VERSION "BodyCAN"

NS_ :

BS_:

BU_: CCM CEM DDM ETC ILCM PDM POT RLDM RRDM SMD SMP TRM Vector_XXX

BO_ 1 New_Message_240: 8 Vector__XXX
 SG_ New_Signal_3402 : 0|8@1+ (1,0) [0|0] "" Vector__XXX

BO_ 0 New_Message_239: 8 Vector__XXX
 SG_ New_Signal_3401 : 7|3@1- (2,3) [1|3] "ars" Vector__XXX

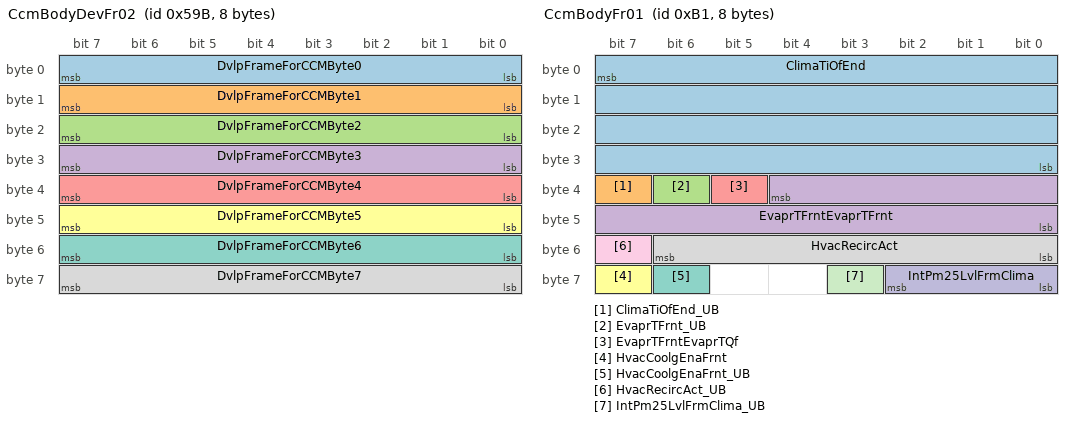
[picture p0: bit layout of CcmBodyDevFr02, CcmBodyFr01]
BO_ 1435 CcmBodyDevFr02: 8 CCM
 SG_ DvlpFrameForCCMByte0 : 7|8@0+ (1,0) [0|255] "Unitless"  CEM
 SG_ DvlpFrameForCCMByte1 : 15|8@0+ (1,0) [0|255] "Unitless"  CEM
 SG_ DvlpFrameForCCMByte2 : 23|8@0+ (1,0) [0|255] "Unitless"  CEM
 SG_ DvlpFrameForCCMByte3 : 31|8@0+ (1,0) [0|255] "Unitless"  CEM
 SG_ DvlpFrameForCCMByte4 : 39|8@0+ (1,0) [0|255] "Unitless"  CEM
 SG_ DvlpFrameForCCMByte5 : 47|8@0+ (1,0) [0|255] "Unitless"  CEM
 SG_ DvlpFrameForCCMByte6 : 55|8@0+ (1,0) [0|255] "Unitless"  CEM
 SG_ DvlpFrameForCCMByte7 : 63|8@0+ (1,0) [0|255] "Unitless"  CEM

BO_ 177 CcmBodyFr01: 8 CCM
 SG_ ClimaTiOfEnd : 7|32@0+ (0.1,0) [0|429496729.5] "s"  CEM
 SG_ ClimaTiOfEnd_UB : 39|1@0+ (1,0) [0|1] ""  CEM
 SG_ EvaprTFrnt_UB : 38|1@0+ (1,0) [0|1] ""  CEM
 SG_ EvaprTFrntEvaprTFrnt : 36|13@0- (0.1,0) [-256|255.9] "degC"  CEM
 SG_ EvaprTFrntEvaprTQf : 37|1@0+ (1,0) [0|1] ""  CEM
 SG_ HvacCoolgEnaFrnt : 63|1@0+ (1,0) [0|1] ""  CEM
 SG_ HvacCoolgEnaFrnt_UB : 62|1@0+ (1,0) [0|1] ""  CEM
 SG_ HvacRecircAct : 54|7@0+ (1,0) [0|100] "%"  CEM
 SG_ HvacRecircAct_UB : 55|1@0+ (1,0) [0|1] ""  CEM
 SG_ IntPm25LvlFrmClima : 58|3@0+ (1,0) [0|7] ""  CEM
 SG_ IntPm25LvlFrmClima_UB : 59|1@0+ (1,0) [0|1] ""  CEM

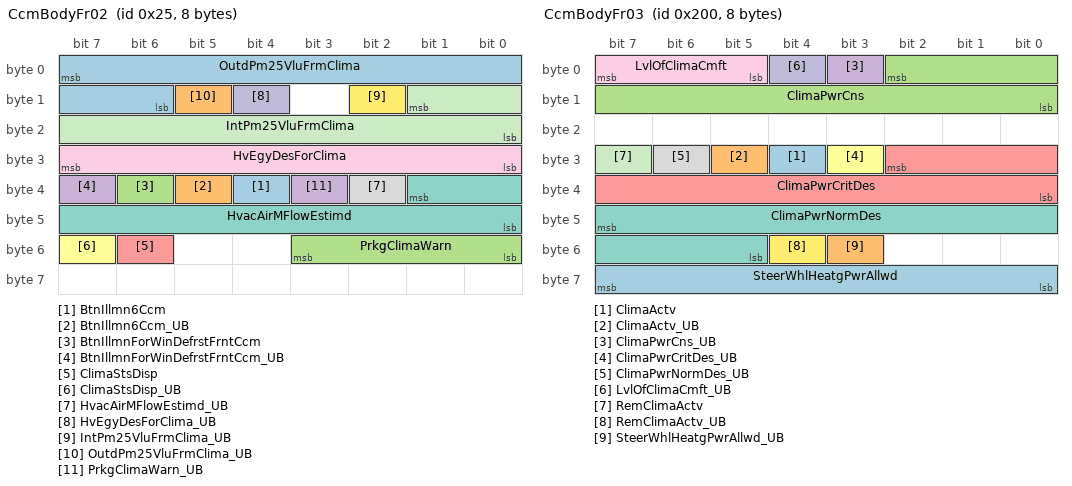
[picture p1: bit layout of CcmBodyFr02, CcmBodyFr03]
BO_ 37 CcmBodyFr02: 8 CCM
 SG_ BtnIllmn6Ccm : 36|1@0+ (1,0) [0|1] ""  CEM
 SG_ BtnIllmn6Ccm_UB : 37|1@0+ (1,0) [0|1] ""  CEM
 SG_ BtnIllmnForWinDefrstFrntCcm : 38|1@0+ (1,0) [0|1] ""  CEM
 SG_ BtnIllmnForWinDefrstFrntCcm_UB : 39|1@0+ (1,0) [0|1] ""  CEM
 SG_ ClimaStsDisp : 54|1@0+ (1,0) [0|1] ""  CEM
 SG_ ClimaStsDisp_UB : 55|1@0+ (1,0) [0|1] ""  CEM
 SG_ HvacAirMFlowEstimd : 33|10@0+ (1,0) [0|1000] "Kg / h"  CEM
 SG_ HvacAirMFlowEstimd_UB : 34|1@0+ (1,0) [0|1] ""  CEM
 SG_ HvEgyDesForClima : 31|8@0+ (50,0) [0|12750] "Wh"  CEM
 SG_ HvEgyDesForClima_UB : 12|1@0+ (1,0) [0|1] ""  CEM
 SG_ IntPm25VluFrmClima : 9|10@0+ (1,0) [0|1023] "Unitless"  CEM
 SG_ IntPm25VluFrmClima_UB : 10|1@0+ (1,0) [0|1] ""  CEM
 SG_ OutdPm25VluFrmClima : 7|10@0+ (1,0) [0|1023] "Unitless"  CEM
 SG_ OutdPm25VluFrmClima_UB : 13|1@0+ (1,0) [0|1] ""  CEM
 SG_ PrkgClimaWarn : 51|4@0+ (1,0) [0|15] ""  CEM
 SG_ PrkgClimaWarn_UB : 35|1@0+ (1,0) [0|1] ""  CEM

BO_ 512 CcmBodyFr03: 8 CCM
 SG_ ClimaActv : 28|1@0+ (1,0) [0|1] ""  CEM
 SG_ ClimaActv_UB : 29|1@0+ (1,0) [0|1] ""  CEM
 SG_ ClimaPwrCns : 2|11@0+ (1,0) [0|2047] "W"  CEM
 SG_ ClimaPwrCns_UB : 3|1@0+ (1,0) [0|1] ""  CEM
 SG_ ClimaPwrCritDes : 26|11@0+ (1,0) [0|2047] "W"  CEM
 SG_ ClimaPwrCritDes_UB : 27|1@0+ (1,0) [0|1] ""  CEM
 SG_ ClimaPwrNormDes : 47|11@0+ (1,0) [0|2047] "W"  CEM
 SG_ ClimaPwrNormDes_UB : 30|1@0+ (1,0) [0|1] ""  CEM
 SG_ LvlOfClimaCmft : 7|3@0+ (1,0) [0|7] ""  CEM
 SG_ LvlOfClimaCmft_UB : 4|1@0+ (1,0) [0|1] ""  CEM
 SG_ RemClimaActv : 31|1@0+ (1,0) [0|1] ""  CEM
 SG_ RemClimaActv_UB : 52|1@0+ (1,0) [0|1] ""  CEM
 SG_ SteerWhlHeatgPwrAllwd : 63|8@0+ (1,0) [0|255] "Unitless"  CEM
 SG_ SteerWhlHeatgPwrAllwd_UB : 51|1@0+ (1,0) [0|1] ""  CEM

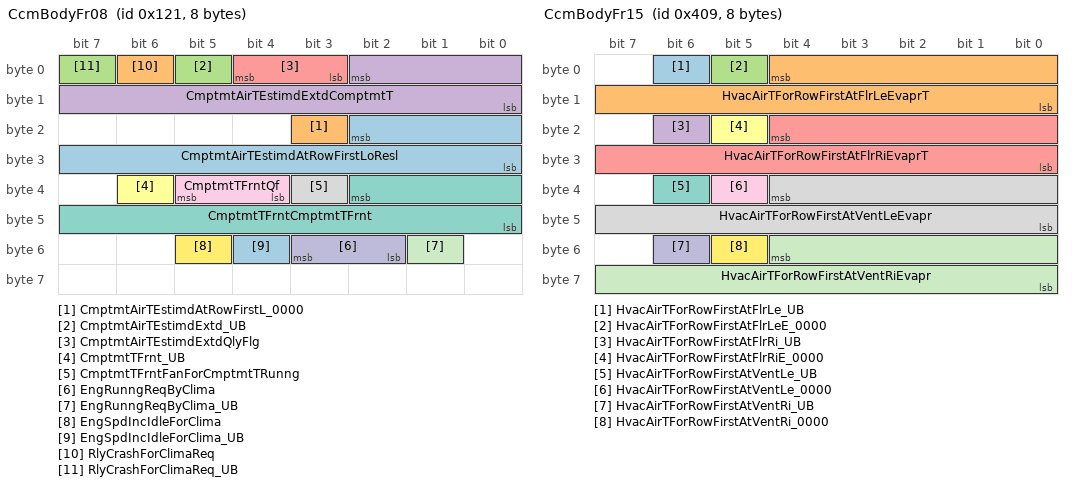
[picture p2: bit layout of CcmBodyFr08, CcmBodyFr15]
BO_ 289 CcmBodyFr08: 8 CCM
 SG_ CmptmtAirTEstimdAtRowFirstLoResl : 18|11@0+ (0.1,-60) [-60|125] "degC"  CEM
 SG_ CmptmtAirTEstimdAtRowFirstL_0000 : 19|1@0+ (1,0) [0|1] ""  CEM
 SG_ CmptmtAirTEstimdExtd_UB : 5|1@0+ (1,0) [0|1] ""  CEM
 SG_ CmptmtAirTEstimdExtdComptmtT : 2|11@0+ (0.1,-60) [-60|125] "degC"  CEM
 SG_ CmptmtAirTEstimdExtdQlyFlg : 4|2@0+ (1,0) [0|3] ""  CEM
 SG_ CmptmtTFrnt_UB : 38|1@0+ (1,0) [0|1] ""  CEM,SMD,SMP
 SG_ CmptmtTFrntCmptmtTFrnt : 34|11@0+ (0.1,-60) [-60|125] "degC"  CEM,SMD,SMP
 SG_ CmptmtTFrntFanForCmptmtTRunng : 35|1@0+ (1,0) [0|1] ""  CEM,SMD,SMP
 SG_ CmptmtTFrntQf : 37|2@0+ (1,0) [0|3] ""  CEM,SMD,SMP
 SG_ EngRunngReqByClima : 51|2@0+ (1,0) [0|3] ""  CEM
 SG_ EngRunngReqByClima_UB : 49|1@0+ (1,0) [0|1] ""  CEM
 SG_ EngSpdIncIdleForClima : 53|1@0+ (1,0) [0|1] ""  CEM
 SG_ EngSpdIncIdleForClima_UB : 52|1@0+ (1,0) [0|1] ""  CEM
 SG_ RlyCrashForClimaReq : 6|1@0+ (1,0) [0|1] ""  CEM
 SG_ RlyCrashForClimaReq_UB : 7|1@0+ (1,0) [0|1] ""  CEM

BO_ 1029 CcmBodyFr11: 8 CCM
 SG_ AirTFbFromClima_UB : 1|1@0+ (1,0) [0|1] ""  CEM
 SG_ AirTFbFromClimaAirTFbFromClima : 15|8@0- (1,0) [-128|127] "Unitless"  CEM
 SG_ AirTFbFromClimaDataQf : 0|1@0+ (1,0) [0|1] ""  CEM
 SG_ ClimaCmptSts : 5|3@0+ (1,0) [0|7] ""  CEM
 SG_ ClimaCmptSts_UB : 6|1@0+ (1,0) [0|1] ""  CEM
 SG_ ClimaDefrstSts : 28|1@0+ (1,0) [0|1] ""  CEM
 SG_ ClimaDefrstSts_UB : 27|1@0+ (1,0) [0|1] ""  CEM
 SG_ ClimaOvrHeatProActv : 54|1@0+ (1,0) [0|1] ""  CEM
 SG_ ClimaOvrHeatProActv_UB : 53|1@0+ (1,0) [0|1] ""  CEM
 SG_ CupHoldrActvAllwd : 25|10@0+ (0.1,0) [0|102.3] "W"  CEM
 SG_ CupHoldrActvAllwd_UB : 26|1@0+ (1,0) [0|1] ""  CEM
 SG_ HvacEvaprTSpFrnt : 47|8@0+ (0.1,-5) [-5|20] "Unitless"  CEM
 SG_ HvacEvaprTSpFrnt_UB : 55|1@0+ (1,0) [0|1] ""  CEM
 SG_ HvacEvaprTSpRe : 63|8@0+ (0.1,-5) [-5|20] "Unitless"  CEM
 SG_ HvacEvaprTSpRe_UB : 7|1@0+ (1,0) [0|1] ""  CEM
 SG_ PwrEstimdAtStbForClima : 23|11@0+ (1,0) [0|2047] "W"  CEM
 SG_ PwrEstimdAtStbForClima_UB : 2|1@0+ (1,0) [0|1] ""  CEM

BO_ 1033 CcmBodyFr15: 8 CCM
 SG_ HvacAirTForRowFirstAtFlrLe_UB : 6|1@0+ (1,0) [0|1] ""  CEM
 SG_ HvacAirTForRowFirstAtFlrLeEvaprT : 4|13@0- (0.1,0) [-256|255.9] "degC"  CEM
 SG_ HvacAirTForRowFirstAtFlrLeE_0000 : 5|1@0+ (1,0) [0|1] ""  CEM
 SG_ HvacAirTForRowFirstAtFlrRi_UB : 22|1@0+ (1,0) [0|1] ""  CEM
 SG_ HvacAirTForRowFirstAtFlrRiEvaprT : 20|13@0- (0.1,0) [-256|255.9] "degC"  CEM
 SG_ HvacAirTForRowFirstAtFlrRiE_0000 : 21|1@0+ (1,0) [0|1] ""  CEM
 SG_ HvacAirTForRowFirstAtVentLe_UB : 38|1@0+ (1,0) [0|1] ""  CEM
 SG_ HvacAirTForRowFirstAtVentLeEvapr : 36|13@0- (0.1,0) [-256|255.9] "degC"  CEM
 SG_ HvacAirTForRowFirstAtVentLe_0000 : 37|1@0+ (1,0) [0|1] ""  CEM
 SG_ HvacAirTForRowFirstAtVentRi_UB : 54|1@0+ (1,0) [0|1] ""  CEM
 SG_ HvacAirTForRowFirstAtVentRiEvapr : 52|13@0- (0.1,0) [-256|255.9] "degC"  CEM
 SG_ HvacAirTForRowFirstAtVentRi_0000 : 53|1@0+ (1,0) [0|1] ""  CEM

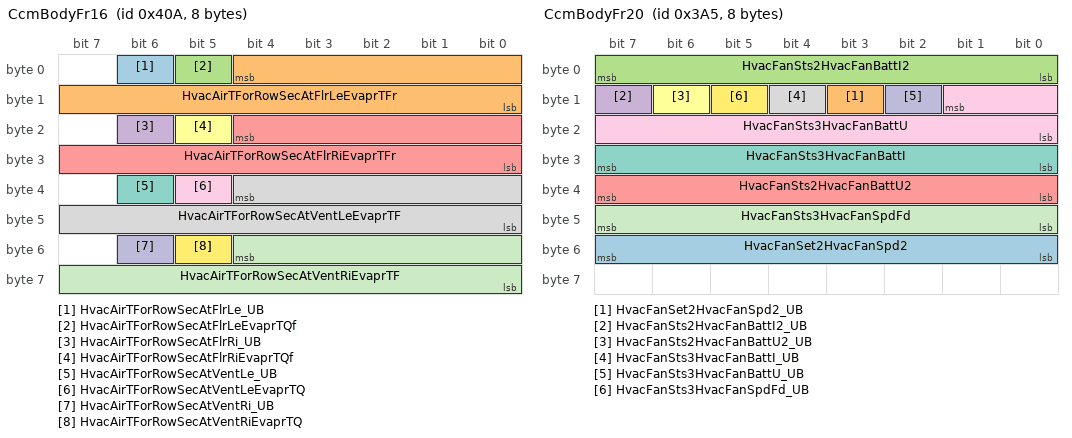
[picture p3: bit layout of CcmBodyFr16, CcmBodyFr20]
BO_ 1034 CcmBodyFr16: 8 CCM
 SG_ HvacAirTForRowSecAtFlrLe_UB : 6|1@0+ (1,0) [0|1] ""  CEM
 SG_ HvacAirTForRowSecAtFlrLeEvaprTFr : 4|13@0- (0.1,0) [-256|255.9] "degC"  CEM
 SG_ HvacAirTForRowSecAtFlrLeEvaprTQf : 5|1@0+ (1,0) [0|1] ""  CEM
 SG_ HvacAirTForRowSecAtFlrRi_UB : 22|1@0+ (1,0) [0|1] ""  CEM
 SG_ HvacAirTForRowSecAtFlrRiEvaprTFr : 20|13@0- (0.1,0) [-256|255.9] "degC"  CEM
 SG_ HvacAirTForRowSecAtFlrRiEvaprTQf : 21|1@0+ (1,0) [0|1] ""  CEM
 SG_ HvacAirTForRowSecAtVentLe_UB : 38|1@0+ (1,0) [0|1] ""  CEM
 SG_ HvacAirTForRowSecAtVentLeEvaprTF : 36|13@0- (0.1,0) [-256|255.9] "degC"  CEM
 SG_ HvacAirTForRowSecAtVentLeEvaprTQ : 37|1@0+ (1,0) [0|1] ""  CEM
 SG_ HvacAirTForRowSecAtVentRi_UB : 54|1@0+ (1,0) [0|1] ""  CEM
 SG_ HvacAirTForRowSecAtVentRiEvaprTF : 52|13@0- (0.1,0) [-256|255.9] "degC"  CEM
 SG_ HvacAirTForRowSecAtVentRiEvaprTQ : 53|1@0+ (1,0) [0|1] ""  CEM

BO_ 933 CcmBodyFr20: 8 CCM
 SG_ HvacFanSet2HvacFanSpd2 : 55|8@0+ (1,0) [0|255] "Unitless"  CEM
 SG_ HvacFanSet2HvacFanSpd2_UB : 11|1@0+ (1,0) [0|1] ""  CEM
 SG_ HvacFanSts2HvacFanBattI2 : 7|8@0+ (0.25,0) [0|63.25] "A"  CEM
 SG_ HvacFanSts2HvacFanBattI2_UB : 15|1@0+ (1,0) [0|1] ""  CEM
 SG_ HvacFanSts2HvacFanBattU2 : 39|8@0+ (0.1,0) [0|25.4] "Volt"  CEM
 SG_ HvacFanSts2HvacFanBattU2_UB : 14|1@0+ (1,0) [0|1] ""  CEM
 SG_ HvacFanSts3HvacFanBattI : 31|8@0+ (0.15,0) [0|38.25] "A"  CEM
 SG_ HvacFanSts3HvacFanBattI_UB : 12|1@0+ (1,0) [0|1] ""  CEM
 SG_ HvacFanSts3HvacFanBattU : 9|10@0+ (0.1,0) [0|102.3] "Volt"  CEM
 SG_ HvacFanSts3HvacFanBattU_UB : 10|1@0+ (1,0) [0|1] ""  CEM
 SG_ HvacFanSts3HvacFanSpdFd : 47|8@0+ (20,300) [300|5400] "rpm"  CEM
 SG_ HvacFanSts3HvacFanSpdFd_UB : 13|1@0+ (1,0) [0|1] ""  CEM

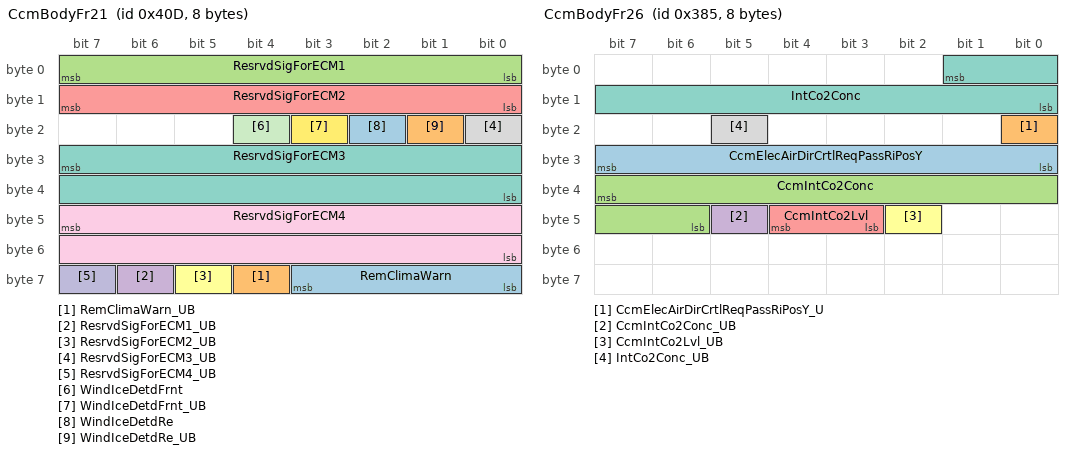
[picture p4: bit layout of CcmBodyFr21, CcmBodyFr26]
BO_ 1037 CcmBodyFr21: 8 CCM
 SG_ RemClimaWarn : 59|4@0+ (1,0) [0|15] ""  CEM
 SG_ RemClimaWarn_UB : 60|1@0+ (1,0) [0|1] ""  CEM
 SG_ ResrvdSigForECM1 : 7|8@0+ (1,0) [0|255] "Unitless"  CEM
 SG_ ResrvdSigForECM1_UB : 62|1@0+ (1,0) [0|1] ""  CEM
 SG_ ResrvdSigForECM2 : 15|8@0+ (1,0) [0|255] "Unitless"  CEM
 SG_ ResrvdSigForECM2_UB : 61|1@0+ (1,0) [0|1] ""  CEM
 SG_ ResrvdSigForECM3 : 31|16@0+ (1,0) [0|65535] "Unitless"  CEM
 SG_ ResrvdSigForECM3_UB : 16|1@0+ (1,0) [0|1] ""  CEM
 SG_ ResrvdSigForECM4 : 47|16@0+ (1,0) [0|65535] "Unitless"  CEM
 SG_ ResrvdSigForECM4_UB : 63|1@0+ (1,0) [0|1] ""  CEM
 SG_ WindIceDetdFrnt : 20|1@0+ (1,0) [0|1] ""  CEM
 SG_ WindIceDetdFrnt_UB : 19|1@0+ (1,0) [0|1] ""  CEM
 SG_ WindIceDetdRe : 18|1@0+ (1,0) [0|1] ""  CEM
 SG_ WindIceDetdRe_UB : 17|1@0+ (1,0) [0|1] ""  CEM

BO_ 1040 CcmBodyFr22: 8 CCM
 SG_ CmptModForHp : 23|3@0+ (1,0) [0|7] ""  CEM
 SG_ CmptModForHp_UB : 31|1@0+ (1,0) [0|1] ""  CEM
 SG_ HpReqCritSts : 4|1@0+ (1,0) [0|1] ""  CEM
 SG_ HpReqCritSts_UB : 47|1@0+ (1,0) [0|1] ""  CEM
 SG_ HvacCondsorT_UB : 30|1@0+ (1,0) [0|1] ""  CEM
 SG_ HvacCondsorTEvaprTFrnt : 28|13@0- (0.1,0) [-256|255.9] "degC"  CEM
 SG_ HvacCondsorTEvaprTQf : 29|1@0+ (1,0) [0|1] ""  CEM
 SG_ HvacCondsorTsp_UB : 46|1@0+ (1,0) [0|1] ""  CEM
 SG_ HvacCondsorTspEvaprTFrnt : 44|13@0- (0.1,0) [-256|255.9] "degC"  CEM
 SG_ HvacCondsorTspEvaprTQf : 45|1@0+ (1,0) [0|1] ""  CEM
 SG_ HvahBlwReq : 19|2@0+ (1,0) [0|3] ""  CEM
 SG_ HvahBlwReq_UB : 20|1@0+ (1,0) [0|1] ""  CEM
 SG_ HvahPwrReq : 15|8@0+ (20,0) [0|5100] "W"  CEM
 SG_ HvahPwrReq_UB : 16|1@0+ (1,0) [0|1] ""  CEM
 SG_ ReEvapVlvSts : 7|3@0+ (1,0) [0|7] ""  CEM
 SG_ ReEvapVlvSts_UB : 56|1@0+ (1,0) [0|1] ""  CEM
 SG_ RemClimaDelaySts : 57|1@0+ (1,0) [0|1] ""  CEM
 SG_ RemClimaDelaySts_UB : 58|1@0+ (1,0) [0|1] ""  CEM
 SG_ RemClimaExtnTiRspn : 59|1@0+ (1,0) [0|1] ""  CEM
 SG_ RemClimaExtnTiRspn_UB : 60|1@0+ (1,0) [0|1] ""  CEM
 SG_ RemClimaHvRspn : 61|1@0+ (1,0) [0|1] ""  CEM
 SG_ RemClimaHvRspn_UB : 62|1@0+ (1,0) [0|1] ""  CEM
 SG_ RemClimaHvSts : 63|1@0+ (1,0) [0|1] ""  CEM
 SG_ RemClimaHvSts_UB : 17|1@0+ (1,0) [0|1] ""  CEM

BO_ 1049 CcmBodyFr25: 8 CCM
 SG_ ClimaSts : 20|1@0+ (1,0) [0|1] ""  CEM
 SG_ ClimaSts_UB : 12|1@0+ (1,0) [0|1] ""  CEM
 SG_ ElecDefrstReq_UB : 56|1@0+ (1,0) [0|1] ""  CEM
 SG_ ElecDefrstReqMirrDefrstReq : 50|1@0+ (1,0) [0|1] ""  CEM
 SG_ ElecDefrstReqWinDefrstFrntReq : 49|1@0+ (1,0) [0|1] ""  CEM
 SG_ ElecDefrstReqWinDefrstReReq : 48|1@0+ (1,0) [0|1] ""  CEM
 SG_ FragCh1UseUpWrn : 60|1@0+ (1,0) [0|1] ""  CEM
 SG_ FragCh1UseUpWrn_UB : 59|1@0+ (1,0) [0|1] ""  CEM
 SG_ FragCh2UseUpWrn : 58|1@0+ (1,0) [0|1] ""  CEM
 SG_ FragCh2UseUpWrn_UB : 57|1@0+ (1,0) [0|1] ""  CEM
 SG_ FragCh3UseUpWrn : 42|1@0+ (1,0) [0|1] ""  CEM
 SG_ FragCh3UseUpWrn_UB : 41|1@0+ (1,0) [0|1] ""  CEM
 SG_ FragCh4UseUpWrn : 44|1@0+ (1,0) [0|1] ""  CEM
 SG_ FragCh4UseUpWrn_UB : 43|1@0+ (1,0) [0|1] ""  CEM
 SG_ FragCh5UseUpWrn : 46|1@0+ (1,0) [0|1] ""  CEM
 SG_ FragCh5UseUpWrn_UB : 45|1@0+ (1,0) [0|1] ""  CEM
 SG_ FragLvlFrmClima : 55|2@0+ (1,0) [0|3] ""  CEM
 SG_ FragLvlFrmClima_UB : 40|1@0+ (1,0) [0|1] ""  CEM
 SG_ FragStsFrmClima : 23|2@0+ (1,0) [0|3] ""  CEM
 SG_ FragStsFrmClima_UB : 61|1@0+ (1,0) [0|1] ""  CEM
 SG_ FrntHvacBlowerSts : 9|2@0+ (1,0) [0|3] ""  CEM
 SG_ FrntHvacBlowerSts_UB : 13|1@0+ (1,0) [0|1] ""  CEM
 SG_ HeatrAirTReq : 7|9@0+ (0.5,-60) [-60|195.5] "Unitless"  CEM
 SG_ HeatrAirTReq_UB : 14|1@0+ (1,0) [0|1] ""  CEM
 SG_ HvacCoolgEnaRe : 39|1@0+ (1,0) [0|1] ""  CEM
 SG_ HvacCoolgEnaRe_UB : 47|1@0+ (1,0) [0|1] ""  CEM
 SG_ HvacOsaAndRecActrQfForHp : 10|1@0+ (1,0) [0|1] ""  CEM
 SG_ HvacOsaAndRecActrQfForHp_UB : 34|1@0+ (1,0) [0|1] ""  CEM
 SG_ HvahAirTsp : 18|11@0+ (0.1,-40) [-40|164.7] "degC"  CEM
 SG_ HvahAirTsp_UB : 11|1@0+ (1,0) [0|1] ""  CEM
 SG_ HvahHeatgReq : 19|1@0+ (1,0) [0|1] ""  CEM
 SG_ HvahHeatgReq_UB : 21|1@0+ (1,0) [0|1] ""  CEM
 SG_ IntPm25StsFrmClima : 52|2@0+ (1,0) [0|3] ""  CEM
 SG_ IntPm25StsFrmClima_UB : 53|1@0+ (1,0) [0|1] ""  CEM
 SG_ OutdPm25LvlFrmClima : 37|3@0+ (1,0) [0|7] ""  CEM
 SG_ OutdPm25LvlFrmClima_UB : 38|1@0+ (1,0) [0|1] ""  CEM
 SG_ PostDrvgClimaAvl : 32|1@0+ (1,0) [0|1] ""  CEM
 SG_ PostDrvgClimaAvl_UB : 33|1@0+ (1,0) [0|1] ""  CEM

BO_ 901 CcmBodyFr26: 8 CCM
 SG_ CcmElecAirDirCrtlReqPassRiPosY : 31|8@0+ (1,0) [0|255] "Unitless"  CEM
 SG_ CcmElecAirDirCrtlReqPassRiPosY_U : 16|1@0+ (1,0) [0|1] ""  CEM
 SG_ CcmIntCo2Conc : 39|10@0+ (10,0) [0|10230] "Unitless"  CEM
 SG_ CcmIntCo2Conc_UB : 45|1@0+ (1,0) [0|1] ""  CEM
 SG_ CcmIntCo2Lvl : 44|2@0+ (1,0) [0|3] ""  CEM
 SG_ CcmIntCo2Lvl_UB : 42|1@0+ (1,0) [0|1] ""  CEM
 SG_ IntCo2Conc : 1|10@0+ (10,0) [0|10230] "Unitless"  CEM
 SG_ IntCo2Conc_UB : 21|1@0+ (1,0) [0|1] ""  CEM

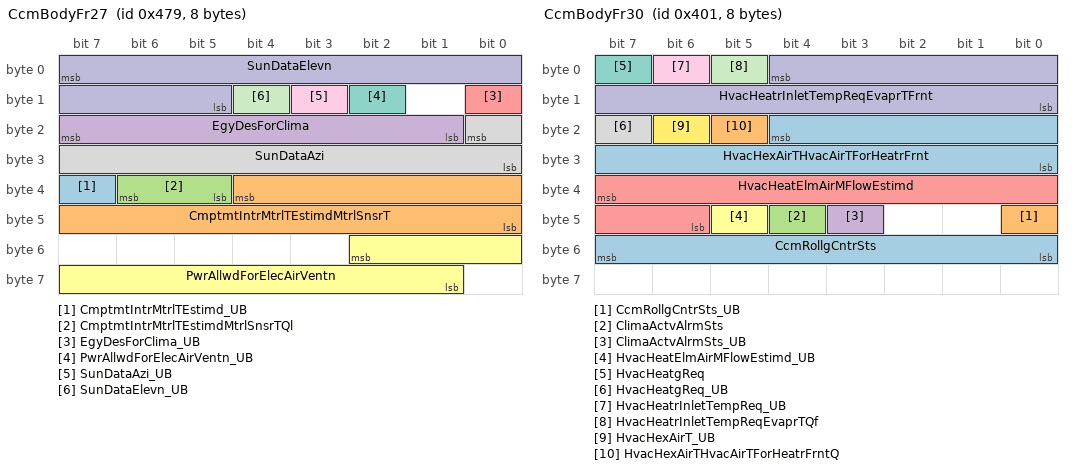
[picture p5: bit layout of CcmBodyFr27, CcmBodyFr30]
BO_ 1145 CcmBodyFr27: 8 CCM
 SG_ CmptmtIntrMtrlTEstimd_UB : 39|1@0+ (1,0) [0|1] ""  CEM
 SG_ CmptmtIntrMtrlTEstimdMtrlSnsrT : 36|13@0- (0.1,0) [-256|255.9] "degC"  CEM
 SG_ CmptmtIntrMtrlTEstimdMtrlSnsrTQl : 38|2@0+ (1,0) [0|3] ""  CEM
 SG_ EgyDesForClima : 23|7@0+ (1,0) [0|127] "Wh"  CEM
 SG_ EgyDesForClima_UB : 8|1@0+ (1,0) [0|1] ""  CEM
 SG_ PwrAllwdForElecAirVentn : 50|10@0+ (0.1,0) [0|102.3] "W"  CEM
 SG_ PwrAllwdForElecAirVentn_UB : 10|1@0+ (1,0) [0|1] ""  CEM
 SG_ SunDataAzi : 16|9@0+ (1,0) [0|511] "Unitless"  CEM
 SG_ SunDataAzi_UB : 11|1@0+ (1,0) [0|1] ""  CEM
 SG_ SunDataElevn : 7|11@0+ (0.1,-90) [-90|90] "Deg"  CEM
 SG_ SunDataElevn_UB : 12|1@0+ (1,0) [0|1] ""  CEM

BO_ 1168 CcmBodyFr28: 8 CCM
 SG_ AmbTEstimd_UB : 5|1@0+ (1,0) [0|1] ""  CEM
 SG_ AmbTEstimdAmbTEstimd : 2|11@0+ (0.1,-70) [-70|134.7] "degC"  CEM
 SG_ AmbTEstimdQf : 3|1@0+ (1,0) [0|1] ""  CEM
 SG_ CcmAirClngSts : 61|2@0+ (1,0) [0|3] ""  CEM
 SG_ CcmAirClngSts_UB : 59|1@0+ (1,0) [0|1] ""  CEM
 SG_ DrvrSeatHeatgPwrAllwd : 23|8@0+ (1,0) [0|255] "Unitless"  CEM,SMD
 SG_ DrvrSeatHeatgPwrAllwd_UB : 6|1@0+ (1,0) [0|1] ""  CEM,SMD
 SG_ PassSeatHeatgPwrAllwd : 31|8@0+ (1,0) [0|255] "Unitless"  CEM,SMP
 SG_ PassSeatHeatgPwrAllwd_UB : 7|1@0+ (1,0) [0|1] ""  CEM,SMP
 SG_ SeatClimaDurgClima_UB : 63|1@0+ (1,0) [0|1] ""  SMD,SMP
 SG_ SeatClimaDurgClimaHmiSeatHeatgFo : 41|2@0+ (1,0) [0|3] ""  SMD,SMP
 SG_ SeatClimaDurgClimaHmiSeatHe_0000 : 43|2@0+ (1,0) [0|3] ""  SMD,SMP
 SG_ SeatClimaDurgClimaHmiSeatHe_0001 : 45|2@0+ (1,0) [0|3] ""  SMD,SMP
 SG_ SeatClimaDurgClimaHmiSeatHe_0002 : 47|2@0+ (1,0) [0|3] ""  SMD,SMP
 SG_ SeatClimaDurgClimaHmiSeatVentnFo : 49|2@0+ (1,0) [0|3] ""  SMD,SMP
 SG_ SeatClimaDurgClimaHmiSeatVe_0000 : 51|2@0+ (1,0) [0|3] ""  SMD,SMP
 SG_ SeatClimaDurgClimaHmiSeatVe_0001 : 53|2@0+ (1,0) [0|3] ""  SMD,SMP
 SG_ SeatClimaDurgClimaHmiSeatVe_0002 : 55|2@0+ (1,0) [0|3] ""  SMD,SMP
 SG_ SecRowLeSeatHeatgPwrAllwd : 39|8@0+ (1,0) [0|255] "Unitless"  CEM
 SG_ SecRowLeSeatHeatgPwrAllwd_UB : 62|1@0+ (1,0) [0|1] ""  CEM

BO_ 1184 CcmBodyFr29: 8 CCM
 SG_ DefrstMaxSts : 63|1@0+ (1,0) [0|1] ""  CEM
 SG_ DefrstMaxSts_UB : 62|1@0+ (1,0) [0|1] ""  CEM
 SG_ ElecAirVentnAvlSts : 45|3@0+ (1,0) [0|7] ""  CEM
 SG_ ElecAirVentnAvlSts_UB : 42|1@0+ (1,0) [0|1] ""  CEM
 SG_ FragCh1Id : 7|8@0+ (1,0) [0|255] "Unitless"  CEM
 SG_ FragCh1Id_UB : 55|1@0+ (1,0) [0|1] ""  CEM
 SG_ FragCh2Id : 15|8@0+ (1,0) [0|255] "Unitless"  CEM
 SG_ FragCh2Id_UB : 54|1@0+ (1,0) [0|1] ""  CEM
 SG_ FragCh3Id : 23|8@0+ (1,0) [0|255] "Unitless"  CEM
 SG_ FragCh3Id_UB : 53|1@0+ (1,0) [0|1] ""  CEM
 SG_ FragCh4Id : 31|8@0+ (1,0) [0|255] "Unitless"  CEM
 SG_ FragCh4Id_UB : 52|1@0+ (1,0) [0|1] ""  CEM
 SG_ FragCh5Id : 39|8@0+ (1,0) [0|255] "Unitless"  CEM
 SG_ FragCh5Id_UB : 51|1@0+ (1,0) [0|1] ""  CEM
 SG_ FragRefreshPopUp : 41|1@0+ (1,0) [0|1] ""  CEM
 SG_ FragRefreshPopUp_UB : 50|1@0+ (1,0) [0|1] ""  CEM
 SG_ IntPm25HiPopUp : 49|2@0+ (1,0) [0|3] ""  CEM
 SG_ IntPm25HiPopUp_UB : 61|1@0+ (1,0) [0|1] ""  CEM
 SG_ OutdAirQly_UB : 59|1@0+ (1,0) [0|1] ""  CEM
 SG_ OutdAirQlyOutdAirQly : 57|2@0+ (1,0) [0|3] ""  CEM
 SG_ OutdAirQlyQf : 58|1@0+ (1,0) [0|1] ""  CEM
 SG_ OutdPm25StsFrmClima : 47|2@0+ (1,0) [0|3] ""  CEM
 SG_ OutdPm25StsFrmClima_UB : 60|1@0+ (1,0) [0|1] ""  CEM

BO_ 1025 CcmBodyFr30: 8 CCM
 SG_ CcmRollgCntrSts : 55|8@0+ (1,0) [0|255] "Unitless"  CEM
 SG_ CcmRollgCntrSts_UB : 40|1@0+ (1,0) [0|1] ""  CEM
 SG_ ClimaActvAlrmSts : 44|1@0+ (1,0) [0|1] ""  CEM
 SG_ ClimaActvAlrmSts_UB : 43|1@0+ (1,0) [0|1] ""  CEM
 SG_ HvacHeatElmAirMFlowEstimd : 39|10@0+ (1,0) [0|1000] "Kg / h"  CEM
 SG_ HvacHeatElmAirMFlowEstimd_UB : 45|1@0+ (1,0) [0|1] ""  CEM
 SG_ HvacHeatgReq : 7|1@0+ (1,0) [0|1] ""  CEM
 SG_ HvacHeatgReq_UB : 23|1@0+ (1,0) [0|1] ""  CEM
 SG_ HvacHeatrInletTempReq_UB : 6|1@0+ (1,0) [0|1] ""  CEM
 SG_ HvacHeatrInletTempReqEvaprTFrnt : 4|13@0- (0.1,0) [-256|255.9] "degC"  CEM
 SG_ HvacHeatrInletTempReqEvaprTQf : 5|1@0+ (1,0) [0|1] ""  CEM
 SG_ HvacHexAirT_UB : 22|1@0+ (1,0) [0|1] ""  CEM
 SG_ HvacHexAirTHvacAirTForHeatrFrnt : 20|13@0- (0.1,0) [-256|255.9] "degC"  CEM
 SG_ HvacHexAirTHvacAirTForHeatrFrntQ : 21|1@0+ (1,0) [0|1] ""  CEM

BO_ 295 CcmBodyFr31: 8 CCM
 SG_ AirFragCh1RunngSts : 55|1@0+ (1,0) [0|1] ""  CEM
 SG_ AirFragCh1RunngSts_UB : 58|1@0+ (1,0) [0|1] ""  CEM
 SG_ AirFragCh2RunngSts : 54|1@0+ (1,0) [0|1] ""  CEM
 SG_ AirFragCh2RunngSts_UB : 57|1@0+ (1,0) [0|1] ""  CEM
 SG_ AirFragCh3RunngSts : 53|1@0+ (1,0) [0|1] ""  CEM
 SG_ AirFragCh3RunngSts_UB : 56|1@0+ (1,0) [0|1] ""  CEM
 SG_ AirFragCh4RunngSts : 52|1@0+ (1,0) [0|1] ""  CEM
 SG_ AirFragCh4RunngSts_UB : 50|1@0+ (1,0) [0|1] ""  CEM
 SG_ AirFragCh5RunngSts : 51|1@0+ (1,0) [0|1] ""  CEM
 SG_ AirFragCh5RunngSts_UB : 49|1@0+ (1,0) [0|1] ""  CEM
 SG_ DrvrSeatVentnPwrAllwd : 7|8@0+ (1,0) [0|255] "Unitless"  CEM,SMD
 SG_ DrvrSeatVentnPwrAllwd_UB : 59|1@0+ (1,0) [0|1] ""  CEM,SMD
 SG_ EcoClimaSts : 47|1@0+ (1,0) [0|1] ""  CEM
 SG_ EcoClimaSts_UB : 46|1@0+ (1,0) [0|1] ""  CEM
 SG_ PassSeatVentnPwrAllwd : 15|8@0+ (1,0) [0|255] "Unitless"  CEM,SMP
 SG_ PassSeatVentnPwrAllwd_UB : 60|1@0+ (1,0) [0|1] ""  CEM,SMP
 SG_ SecRowLeSeatVentnPwrAllwd : 23|8@0+ (1,0) [0|255] "Unitless"  CEM
 SG_ SecRowLeSeatVentnPwrAllwd_UB : 61|1@0+ (1,0) [0|1] ""  CEM
 SG_ SecRowRiSeatHeatgPwrAllwd : 31|8@0+ (1,0) [0|255] "Unitless"  CEM
 SG_ SecRowRiSeatHeatgPwrAllwd_UB : 62|1@0+ (1,0) [0|1] ""  CEM
 SG_ SecRowRiSeatVentnPwrAllwd : 39|8@0+ (1,0) [0|255] "Unitless"  CEM
 SG_ SecRowRiSeatVentnPwrAllwd_UB : 63|1@0+ (1,0) [0|1] ""  CEM
 SG_ SteerWhlHeatgDurgClima : 45|1@0+ (1,0) [0|1] ""  CEM
 SG_ SteerWhlHeatgDurgClima_UB : 44|1@0+ (1,0) [0|1] ""  CEM

BO_ 831 CcmBodyFr34: 8 CCM
 SG_ CarTiIntForClima : 39|32@0+ (0.1,0) [0|429496729.5] "s"  CEM
 SG_ CarTiIntForClima_UB : 31|1@0+ (1,0) [0|1] ""  CEM
 SG_ ClimaCoolgReqLvl : 27|2@0+ (1,0) [0|3] ""  CEM
 SG_ ClimaCoolgReqLvl_UB : 29|1@0+ (1,0) [0|1] ""  CEM
 SG_ ClimaHeatgReqLvl : 25|2@0+ (1,0) [0|3] ""  CEM
 SG_ ClimaHeatgReqLvl_UB : 28|1@0+ (1,0) [0|1] ""  CEM
 SG_ ClimaOvrHeatPrtSts : 23|1@0+ (1,0) [0|1] ""  CEM
 SG_ ClimaOvrHeatPrtSts_UB : 30|1@0+ (1,0) [0|1] ""  CEM
 SG_ EvaprVlvReStsExtd_UB : 14|1@0+ (1,0) [0|1] ""  CEM
 SG_ EvaprVlvReStsExtdDiagcStsForCirc : 13|2@0+ (1,0) [0|3] ""  CEM
 SG_ EvaprVlvReStsExtdDiagcStsForShoT : 11|2@0+ (1,0) [0|3] ""  CEM
 SG_ EvaprVlvReStsExtdDiagcStsFo_0000 : 9|2@0+ (1,0) [0|3] ""  CEM
 SG_ ReHvacBlowerSts : 17|2@0+ (1,0) [0|3] ""  CEM
 SG_ ReHvacBlowerSts_UB : 18|1@0+ (1,0) [0|1] ""  CEM
 SG_ RlyCmftForClimaReq : 22|1@0+ (1,0) [0|1] ""  CEM
 SG_ RlyCmftForClimaReq_UB : 21|1@0+ (1,0) [0|1] ""  CEM
 SG_ UBoostReqByClima : 20|1@0+ (1,0) [0|1] ""  CEM
 SG_ UBoostReqByClima_UB : 19|1@0+ (1,0) [0|1] ""  CEM

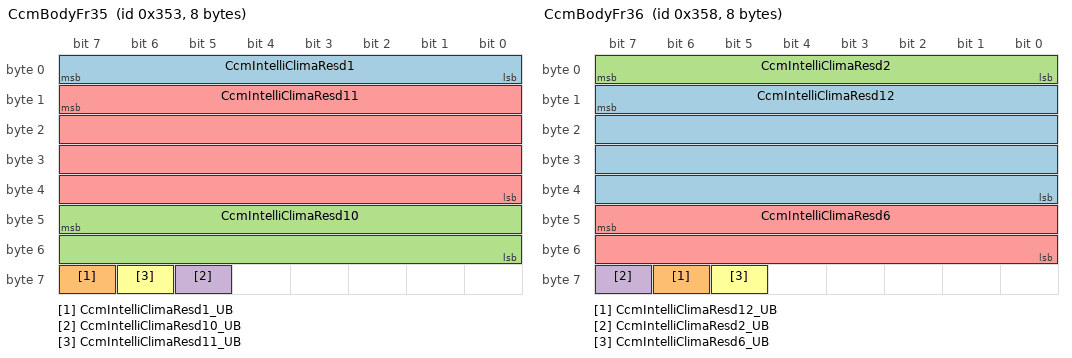
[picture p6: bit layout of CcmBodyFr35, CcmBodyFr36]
BO_ 851 CcmBodyFr35: 8 CCM
 SG_ CcmIntelliClimaResd1 : 7|8@0+ (1,0) [0|255] "Unitless"  CEM
 SG_ CcmIntelliClimaResd1_UB : 63|1@0+ (1,0) [0|1] ""  CEM
 SG_ CcmIntelliClimaResd10 : 47|16@0+ (1,0) [0|65535] "Unitless"  CEM
 SG_ CcmIntelliClimaResd10_UB : 61|1@0+ (1,0) [0|1] ""  CEM
 SG_ CcmIntelliClimaResd11 : 15|32@0+ (1,0) [0|4294967295] "Unitless"  CEM
 SG_ CcmIntelliClimaResd11_UB : 62|1@0+ (1,0) [0|1] ""  CEM

BO_ 856 CcmBodyFr36: 8 CCM
 SG_ CcmIntelliClimaResd12 : 15|32@0+ (1,0) [0|4294967295] "Unitless"  CEM
 SG_ CcmIntelliClimaResd12_UB : 62|1@0+ (1,0) [0|1] ""  CEM
 SG_ CcmIntelliClimaResd2 : 7|8@0+ (1,0) [0|255] "Unitless"  CEM
 SG_ CcmIntelliClimaResd2_UB : 63|1@0+ (1,0) [0|1] ""  CEM
 SG_ CcmIntelliClimaResd6 : 47|16@0+ (1,0) [0|65535] "Unitless"  CEM
 SG_ CcmIntelliClimaResd6_UB : 61|1@0+ (1,0) [0|1] ""  CEM

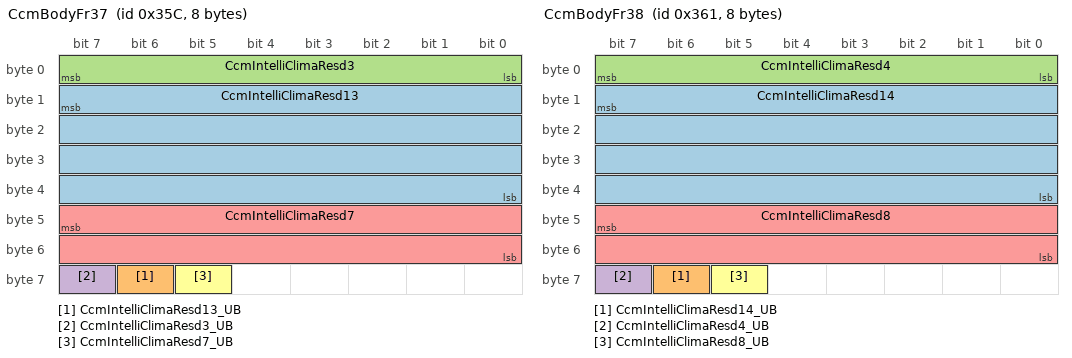
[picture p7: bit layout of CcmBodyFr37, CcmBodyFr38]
BO_ 860 CcmBodyFr37: 8 CCM
 SG_ CcmIntelliClimaResd13 : 15|32@0+ (1,0) [0|4294967295] "Unitless"  CEM
 SG_ CcmIntelliClimaResd13_UB : 62|1@0+ (1,0) [0|1] ""  CEM
 SG_ CcmIntelliClimaResd3 : 7|8@0+ (1,0) [0|255] "Unitless"  CEM
 SG_ CcmIntelliClimaResd3_UB : 63|1@0+ (1,0) [0|1] ""  CEM
 SG_ CcmIntelliClimaResd7 : 47|16@0+ (1,0) [0|65535] "Unitless"  CEM
 SG_ CcmIntelliClimaResd7_UB : 61|1@0+ (1,0) [0|1] ""  CEM

BO_ 865 CcmBodyFr38: 8 CCM
 SG_ CcmIntelliClimaResd14 : 15|32@0+ (1,0) [0|4294967295] "Unitless"  CEM
 SG_ CcmIntelliClimaResd14_UB : 62|1@0+ (1,0) [0|1] ""  CEM
 SG_ CcmIntelliClimaResd4 : 7|8@0+ (1,0) [0|255] "Unitless"  CEM
 SG_ CcmIntelliClimaResd4_UB : 63|1@0+ (1,0) [0|1] ""  CEM
 SG_ CcmIntelliClimaResd8 : 47|16@0+ (1,0) [0|65535] "Unitless"  CEM
 SG_ CcmIntelliClimaResd8_UB : 61|1@0+ (1,0) [0|1] ""  CEM

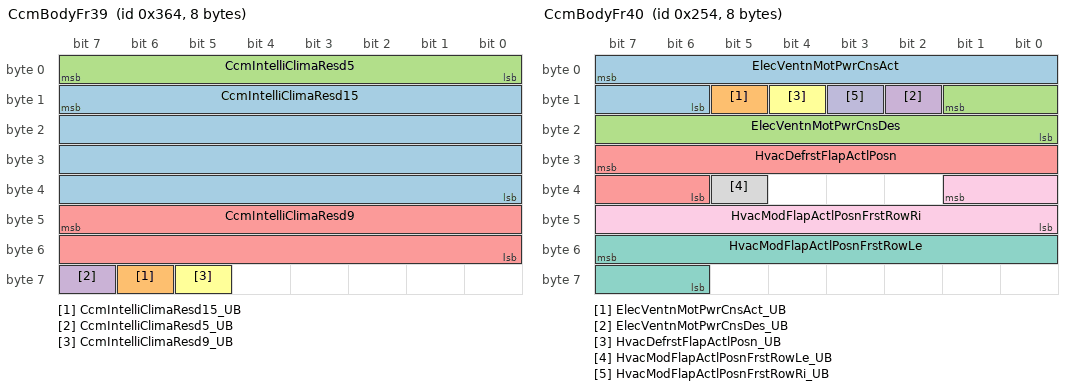
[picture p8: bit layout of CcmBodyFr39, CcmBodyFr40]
BO_ 868 CcmBodyFr39: 8 CCM
 SG_ CcmIntelliClimaResd15 : 15|32@0+ (1,0) [0|4294967295] "Unitless"  CEM
 SG_ CcmIntelliClimaResd15_UB : 62|1@0+ (1,0) [0|1] ""  CEM
 SG_ CcmIntelliClimaResd5 : 7|8@0+ (1,0) [0|255] "Unitless"  CEM
 SG_ CcmIntelliClimaResd5_UB : 63|1@0+ (1,0) [0|1] ""  CEM
 SG_ CcmIntelliClimaResd9 : 47|16@0+ (1,0) [0|65535] "Unitless"  CEM
 SG_ CcmIntelliClimaResd9_UB : 61|1@0+ (1,0) [0|1] ""  CEM

BO_ 596 CcmBodyFr40: 8 CCM
 SG_ ElecVentnMotPwrCnsAct : 7|10@0+ (0.1,0) [0|102.3] "W"  CEM
 SG_ ElecVentnMotPwrCnsAct_UB : 13|1@0+ (1,0) [0|1] ""  CEM
 SG_ ElecVentnMotPwrCnsDes : 9|10@0+ (0.1,0) [0|102.3] "W"  CEM
 SG_ ElecVentnMotPwrCnsDes_UB : 10|1@0+ (1,0) [0|1] ""  CEM
 SG_ HvacDefrstFlapActlPosn : 31|10@0+ (0.1,0) [0|100] "%"  CEM
 SG_ HvacDefrstFlapActlPosn_UB : 12|1@0+ (1,0) [0|1] ""  CEM
 SG_ HvacModFlapActlPosnFrstRowLe : 55|10@0+ (0.1,0) [0|100] "%"  CEM
 SG_ HvacModFlapActlPosnFrstRowLe_UB : 37|1@0+ (1,0) [0|1] ""  CEM
 SG_ HvacModFlapActlPosnFrstRowRi : 33|10@0+ (0.1,0) [0|100] "%"  CEM
 SG_ HvacModFlapActlPosnFrstRowRi_UB : 11|1@0+ (1,0) [0|1] ""  CEM

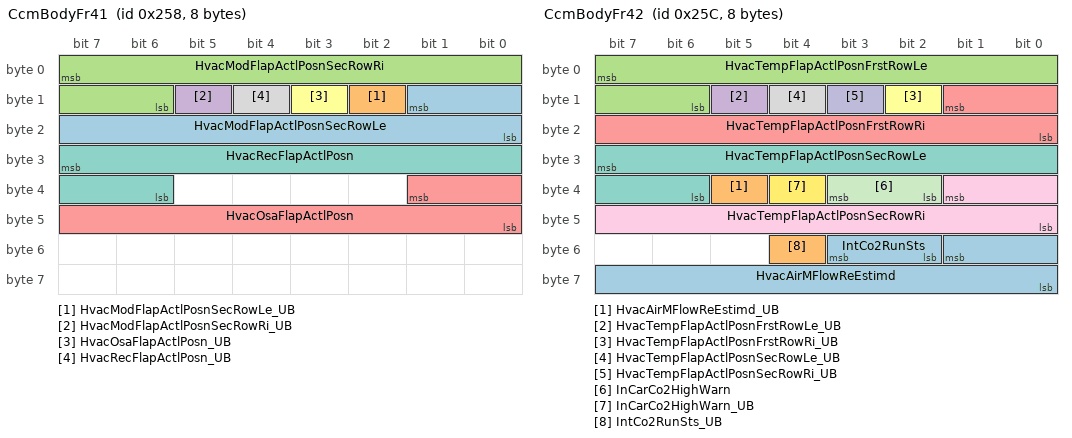
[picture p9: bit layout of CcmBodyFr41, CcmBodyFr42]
BO_ 600 CcmBodyFr41: 8 CCM
 SG_ HvacModFlapActlPosnSecRowLe : 9|10@0+ (0.1,0) [0|100] "%"  CEM
 SG_ HvacModFlapActlPosnSecRowLe_UB : 10|1@0+ (1,0) [0|1] ""  CEM
 SG_ HvacModFlapActlPosnSecRowRi : 7|10@0+ (0.1,0) [0|100] "%"  CEM
 SG_ HvacModFlapActlPosnSecRowRi_UB : 13|1@0+ (1,0) [0|1] ""  CEM
 SG_ HvacOsaFlapActlPosn : 33|10@0+ (0.1,0) [0|100] "%"  CEM
 SG_ HvacOsaFlapActlPosn_UB : 11|1@0+ (1,0) [0|1] ""  CEM
 SG_ HvacRecFlapActlPosn : 31|10@0+ (0.1,0) [0|100] "%"  CEM
 SG_ HvacRecFlapActlPosn_UB : 12|1@0+ (1,0) [0|1] ""  CEM

BO_ 604 CcmBodyFr42: 8 CCM
 SG_ HvacAirMFlowReEstimd : 49|10@0+ (1,0) [0|1000] "Kg / h"  CEM
 SG_ HvacAirMFlowReEstimd_UB : 37|1@0+ (1,0) [0|1] ""  CEM
 SG_ HvacTempFlapActlPosnFrstRowLe : 7|10@0+ (0.1,0) [0|100] "%"  CEM
 SG_ HvacTempFlapActlPosnFrstRowLe_UB : 13|1@0+ (1,0) [0|1] ""  CEM
 SG_ HvacTempFlapActlPosnFrstRowRi : 9|10@0+ (0.1,0) [0|100] "%"  CEM
 SG_ HvacTempFlapActlPosnFrstRowRi_UB : 10|1@0+ (1,0) [0|1] ""  CEM
 SG_ HvacTempFlapActlPosnSecRowLe : 31|10@0+ (0.1,0) [0|100] "%"  CEM
 SG_ HvacTempFlapActlPosnSecRowLe_UB : 12|1@0+ (1,0) [0|1] ""  CEM
 SG_ HvacTempFlapActlPosnSecRowRi : 33|10@0+ (0.1,0) [0|100] "%"  CEM
 SG_ HvacTempFlapActlPosnSecRowRi_UB : 11|1@0+ (1,0) [0|1] ""  CEM
 SG_ InCarCo2HighWarn : 35|2@0+ (1,0) [0|3] ""  CEM
 SG_ InCarCo2HighWarn_UB : 36|1@0+ (1,0) [0|1] ""  CEM
 SG_ IntCo2RunSts : 51|2@0+ (1,0) [0|3] ""  CEM
 SG_ IntCo2RunSts_UB : 52|1@0+ (1,0) [0|1] ""  CEM

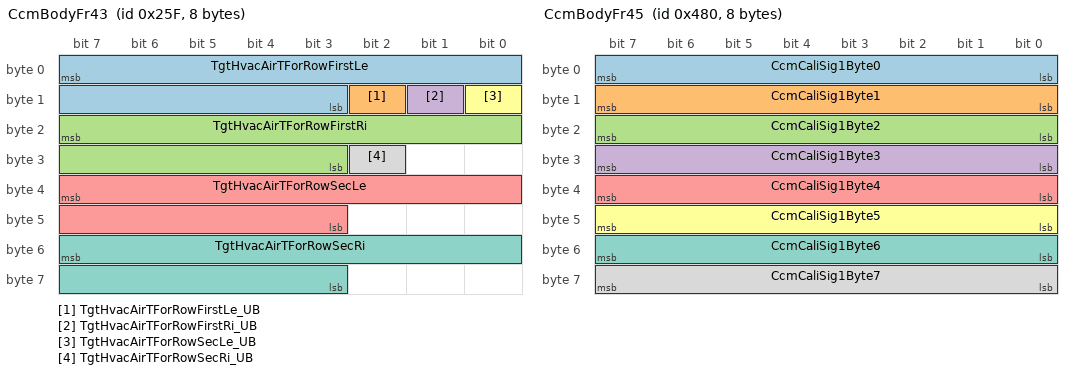
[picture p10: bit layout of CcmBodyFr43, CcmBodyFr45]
BO_ 607 CcmBodyFr43: 8 CCM
 SG_ TgtHvacAirTForRowFirstLe : 7|13@0- (0.1,0) [-256|255.9] "degC"  CEM
 SG_ TgtHvacAirTForRowFirstLe_UB : 10|1@0+ (1,0) [0|1] ""  CEM
 SG_ TgtHvacAirTForRowFirstRi : 23|13@0- (0.1,0) [-256|255.9] "degC"  CEM
 SG_ TgtHvacAirTForRowFirstRi_UB : 9|1@0+ (1,0) [0|1] ""  CEM
 SG_ TgtHvacAirTForRowSecLe : 39|13@0- (0.1,0) [-256|255.9] "degC"  CEM
 SG_ TgtHvacAirTForRowSecLe_UB : 8|1@0+ (1,0) [0|1] ""  CEM
 SG_ TgtHvacAirTForRowSecRi : 55|13@0- (0.1,0) [-256|255.9] "degC"  CEM
 SG_ TgtHvacAirTForRowSecRi_UB : 26|1@0+ (1,0) [0|1] ""  CEM

BO_ 593 CcmBodyFr44: 8 CCM
 SG_ AutoDefrstReqPopUp : 23|1@0+ (1,0) [0|1] ""  CEM
 SG_ AutoDefrstReqPopUp_UB : 22|1@0+ (1,0) [0|1] ""  CEM
 SG_ AutoDeHumPopUp : 21|1@0+ (1,0) [0|1] ""  CEM
 SG_ AutoDeHumPopUp_UB : 20|1@0+ (1,0) [0|1] ""  CEM
 SG_ ClimaOffReq : 13|2@0+ (1,0) [0|3] ""  CEM
 SG_ ClimaOffReq_UB : 11|1@0+ (1,0) [0|1] ""  CEM
 SG_ ClimaOnReq : 26|3@0+ (1,0) [0|7] ""  CEM
 SG_ ClimaOnReq_UB : 17|1@0+ (1,0) [0|1] ""  CEM
 SG_ ClimaOvrHeatProRspn : 31|1@0+ (1,0) [0|1] ""  CEM
 SG_ ClimaOvrHeatProRspn_UB : 30|1@0+ (1,0) [0|1] ""  CEM
 SG_ ClimaOvrHeatProWarn : 29|2@0+ (1,0) [0|3] ""  CEM
 SG_ ClimaOvrHeatProWarn_UB : 27|1@0+ (1,0) [0|1] ""  CEM
 SG_ Co2WarnForTelm : 19|1@0+ (1,0) [0|1] ""  CEM
 SG_ Co2WarnForTelm_UB : 18|1@0+ (1,0) [0|1] ""  CEM
 SG_ DiDblLock : 2|1@0+ (1,0) [0|1] ""  CEM
 SG_ DiDblLock_UB : 1|1@0+ (1,0) [0|1] ""  CEM
 SG_ RemStrtClimaRspn : 15|1@0+ (1,0) [0|1] ""  CEM
 SG_ RemStrtClimaRspn_UB : 14|1@0+ (1,0) [0|1] ""  CEM
 SG_ RoofOpnReqFrmClima : 7|1@0+ (1,0) [0|1] ""  CEM
 SG_ RoofOpnReqFrmClima_UB : 6|1@0+ (1,0) [0|1] ""  CEM
 SG_ SunRoofOpnPopUpForHmi : 10|1@0+ (1,0) [0|1] ""  CEM
 SG_ SunRoofOpnPopUpForHmi_UB : 9|1@0+ (1,0) [0|1] ""  CEM
 SG_ WinAndRoofReqFrmClima : 5|2@0+ (1,0) [0|3] ""  CEM
 SG_ WinAndRoofReqFrmClima_UB : 3|1@0+ (1,0) [0|1] ""  CEM
 SG_ WinRfClsdReqForCoolgDwn : 0|1@0+ (1,0) [0|1] ""  CEM
 SG_ WinRfClsdReqForCoolgDwn_UB : 8|1@0+ (1,0) [0|1] ""  CEM

BO_ 1152 CcmBodyFr45: 8 CCM
 SG_ CcmCaliSig1Byte0 : 7|8@0+ (1,0) [0|255] "Unitless"  CEM
 SG_ CcmCaliSig1Byte1 : 15|8@0+ (1,0) [0|255] "Unitless"  CEM
 SG_ CcmCaliSig1Byte2 : 23|8@0+ (1,0) [0|255] "Unitless"  CEM
 SG_ CcmCaliSig1Byte3 : 31|8@0+ (1,0) [0|255] "Unitless"  CEM
 SG_ CcmCaliSig1Byte4 : 39|8@0+ (1,0) [0|255] "Unitless"  CEM
 SG_ CcmCaliSig1Byte5 : 47|8@0+ (1,0) [0|255] "Unitless"  CEM
 SG_ CcmCaliSig1Byte6 : 55|8@0+ (1,0) [0|255] "Unitless"  CEM
 SG_ CcmCaliSig1Byte7 : 63|8@0+ (1,0) [0|255] "Unitless"  CEM

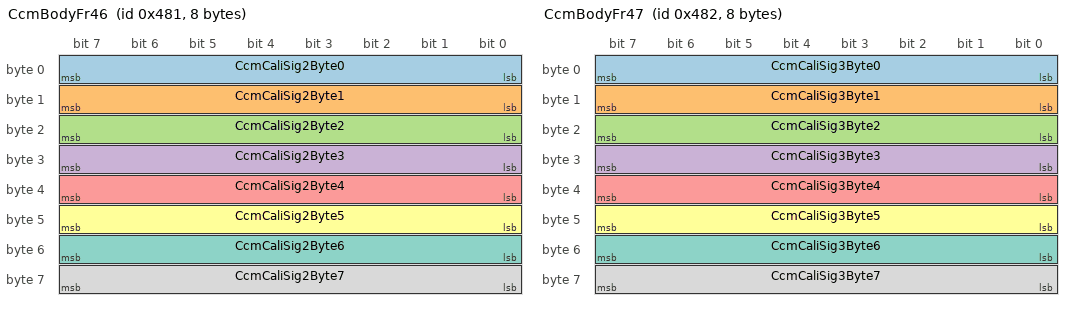
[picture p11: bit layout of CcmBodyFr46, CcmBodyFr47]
BO_ 1153 CcmBodyFr46: 8 CCM
 SG_ CcmCaliSig2Byte0 : 7|8@0+ (1,0) [0|255] "Unitless"  CEM
 SG_ CcmCaliSig2Byte1 : 15|8@0+ (1,0) [0|255] "Unitless"  CEM
 SG_ CcmCaliSig2Byte2 : 23|8@0+ (1,0) [0|255] "Unitless"  CEM
 SG_ CcmCaliSig2Byte3 : 31|8@0+ (1,0) [0|255] "Unitless"  CEM
 SG_ CcmCaliSig2Byte4 : 39|8@0+ (1,0) [0|255] "Unitless"  CEM
 SG_ CcmCaliSig2Byte5 : 47|8@0+ (1,0) [0|255] "Unitless"  CEM
 SG_ CcmCaliSig2Byte6 : 55|8@0+ (1,0) [0|255] "Unitless"  CEM
 SG_ CcmCaliSig2Byte7 : 63|8@0+ (1,0) [0|255] "Unitless"  CEM

BO_ 1154 CcmBodyFr47: 8 CCM
 SG_ CcmCaliSig3Byte0 : 7|8@0+ (1,0) [0|255] "Unitless"  CEM
 SG_ CcmCaliSig3Byte1 : 15|8@0+ (1,0) [0|255] "Unitless"  CEM
 SG_ CcmCaliSig3Byte2 : 23|8@0+ (1,0) [0|255] "Unitless"  CEM
 SG_ CcmCaliSig3Byte3 : 31|8@0+ (1,0) [0|255] "Unitless"  CEM
 SG_ CcmCaliSig3Byte4 : 39|8@0+ (1,0) [0|255] "Unitless"  CEM
 SG_ CcmCaliSig3Byte5 : 47|8@0+ (1,0) [0|255] "Unitless"  CEM
 SG_ CcmCaliSig3Byte6 : 55|8@0+ (1,0) [0|255] "Unitless"  CEM
 SG_ CcmCaliSig3Byte7 : 63|8@0+ (1,0) [0|255] "Unitless"  CEM

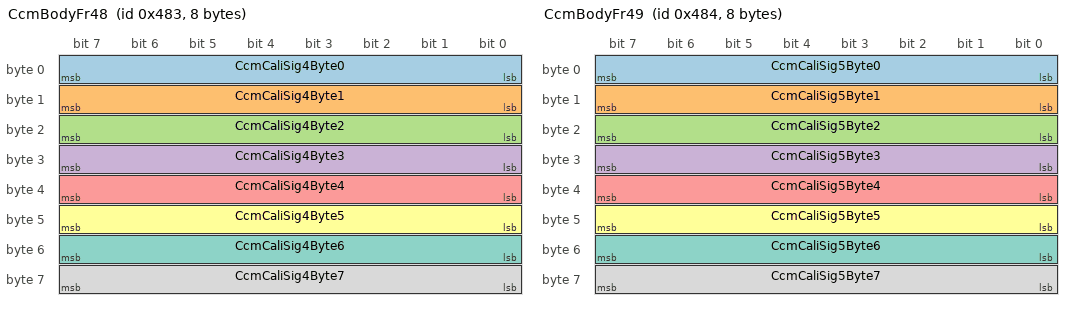
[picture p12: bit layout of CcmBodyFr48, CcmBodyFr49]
BO_ 1155 CcmBodyFr48: 8 CCM
 SG_ CcmCaliSig4Byte0 : 7|8@0+ (1,0) [0|255] "Unitless"  CEM
 SG_ CcmCaliSig4Byte1 : 15|8@0+ (1,0) [0|255] "Unitless"  CEM
 SG_ CcmCaliSig4Byte2 : 23|8@0+ (1,0) [0|255] "Unitless"  CEM
 SG_ CcmCaliSig4Byte3 : 31|8@0+ (1,0) [0|255] "Unitless"  CEM
 SG_ CcmCaliSig4Byte4 : 39|8@0+ (1,0) [0|255] "Unitless"  CEM
 SG_ CcmCaliSig4Byte5 : 47|8@0+ (1,0) [0|255] "Unitless"  CEM
 SG_ CcmCaliSig4Byte6 : 55|8@0+ (1,0) [0|255] "Unitless"  CEM
 SG_ CcmCaliSig4Byte7 : 63|8@0+ (1,0) [0|255] "Unitless"  CEM

BO_ 1156 CcmBodyFr49: 8 CCM
 SG_ CcmCaliSig5Byte0 : 7|8@0+ (1,0) [0|255] "Unitless"  CEM
 SG_ CcmCaliSig5Byte1 : 15|8@0+ (1,0) [0|255] "Unitless"  CEM
 SG_ CcmCaliSig5Byte2 : 23|8@0+ (1,0) [0|255] "Unitless"  CEM
 SG_ CcmCaliSig5Byte3 : 31|8@0+ (1,0) [0|255] "Unitless"  CEM
 SG_ CcmCaliSig5Byte4 : 39|8@0+ (1,0) [0|255] "Unitless"  CEM
 SG_ CcmCaliSig5Byte5 : 47|8@0+ (1,0) [0|255] "Unitless"  CEM
 SG_ CcmCaliSig5Byte6 : 55|8@0+ (1,0) [0|255] "Unitless"  CEM
 SG_ CcmCaliSig5Byte7 : 63|8@0+ (1,0) [0|255] "Unitless"  CEM

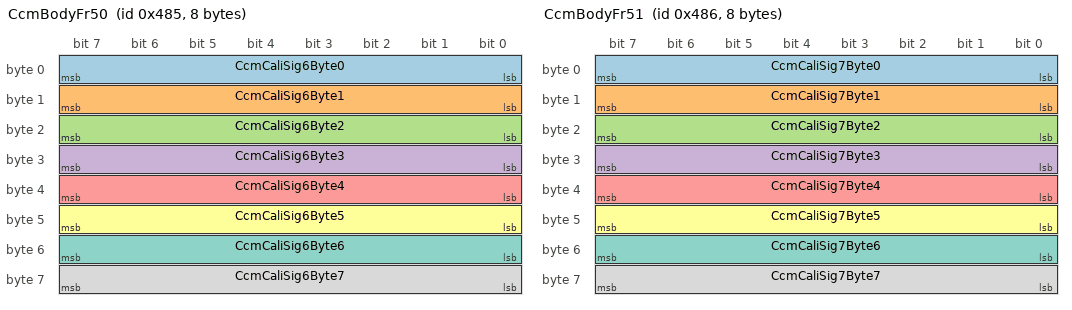
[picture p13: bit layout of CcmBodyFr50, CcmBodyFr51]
BO_ 1157 CcmBodyFr50: 8 CCM
 SG_ CcmCaliSig6Byte0 : 7|8@0+ (1,0) [0|255] "Unitless"  CEM
 SG_ CcmCaliSig6Byte1 : 15|8@0+ (1,0) [0|255] "Unitless"  CEM
 SG_ CcmCaliSig6Byte2 : 23|8@0+ (1,0) [0|255] "Unitless"  CEM
 SG_ CcmCaliSig6Byte3 : 31|8@0+ (1,0) [0|255] "Unitless"  CEM
 SG_ CcmCaliSig6Byte4 : 39|8@0+ (1,0) [0|255] "Unitless"  CEM
 SG_ CcmCaliSig6Byte5 : 47|8@0+ (1,0) [0|255] "Unitless"  CEM
 SG_ CcmCaliSig6Byte6 : 55|8@0+ (1,0) [0|255] "Unitless"  CEM
 SG_ CcmCaliSig6Byte7 : 63|8@0+ (1,0) [0|255] "Unitless"  CEM

BO_ 1158 CcmBodyFr51: 8 CCM
 SG_ CcmCaliSig7Byte0 : 7|8@0+ (1,0) [0|255] "Unitless"  CEM
 SG_ CcmCaliSig7Byte1 : 15|8@0+ (1,0) [0|255] "Unitless"  CEM
 SG_ CcmCaliSig7Byte2 : 23|8@0+ (1,0) [0|255] "Unitless"  CEM
 SG_ CcmCaliSig7Byte3 : 31|8@0+ (1,0) [0|255] "Unitless"  CEM
 SG_ CcmCaliSig7Byte4 : 39|8@0+ (1,0) [0|255] "Unitless"  CEM
 SG_ CcmCaliSig7Byte5 : 47|8@0+ (1,0) [0|255] "Unitless"  CEM
 SG_ CcmCaliSig7Byte6 : 55|8@0+ (1,0) [0|255] "Unitless"  CEM
 SG_ CcmCaliSig7Byte7 : 63|8@0+ (1,0) [0|255] "Unitless"  CEM

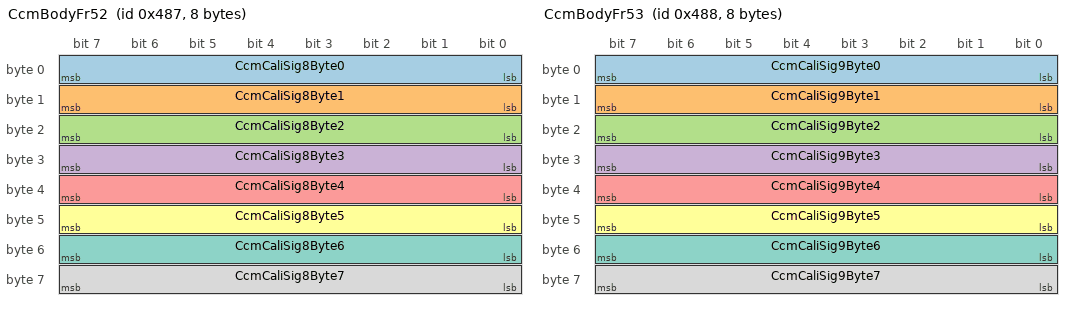
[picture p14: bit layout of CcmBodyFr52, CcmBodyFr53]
BO_ 1159 CcmBodyFr52: 8 CCM
 SG_ CcmCaliSig8Byte0 : 7|8@0+ (1,0) [0|255] "Unitless"  CEM
 SG_ CcmCaliSig8Byte1 : 15|8@0+ (1,0) [0|255] "Unitless"  CEM
 SG_ CcmCaliSig8Byte2 : 23|8@0+ (1,0) [0|255] "Unitless"  CEM
 SG_ CcmCaliSig8Byte3 : 31|8@0+ (1,0) [0|255] "Unitless"  CEM
 SG_ CcmCaliSig8Byte4 : 39|8@0+ (1,0) [0|255] "Unitless"  CEM
 SG_ CcmCaliSig8Byte5 : 47|8@0+ (1,0) [0|255] "Unitless"  CEM
 SG_ CcmCaliSig8Byte6 : 55|8@0+ (1,0) [0|255] "Unitless"  CEM
 SG_ CcmCaliSig8Byte7 : 63|8@0+ (1,0) [0|255] "Unitless"  CEM

BO_ 1160 CcmBodyFr53: 8 CCM
 SG_ CcmCaliSig9Byte0 : 7|8@0+ (1,0) [0|255] "Unitless"  CEM
 SG_ CcmCaliSig9Byte1 : 15|8@0+ (1,0) [0|255] "Unitless"  CEM
 SG_ CcmCaliSig9Byte2 : 23|8@0+ (1,0) [0|255] "Unitless"  CEM
 SG_ CcmCaliSig9Byte3 : 31|8@0+ (1,0) [0|255] "Unitless"  CEM
 SG_ CcmCaliSig9Byte4 : 39|8@0+ (1,0) [0|255] "Unitless"  CEM
 SG_ CcmCaliSig9Byte5 : 47|8@0+ (1,0) [0|255] "Unitless"  CEM
 SG_ CcmCaliSig9Byte6 : 55|8@0+ (1,0) [0|255] "Unitless"  CEM
 SG_ CcmCaliSig9Byte7 : 63|8@0+ (1,0) [0|255] "Unitless"  CEM

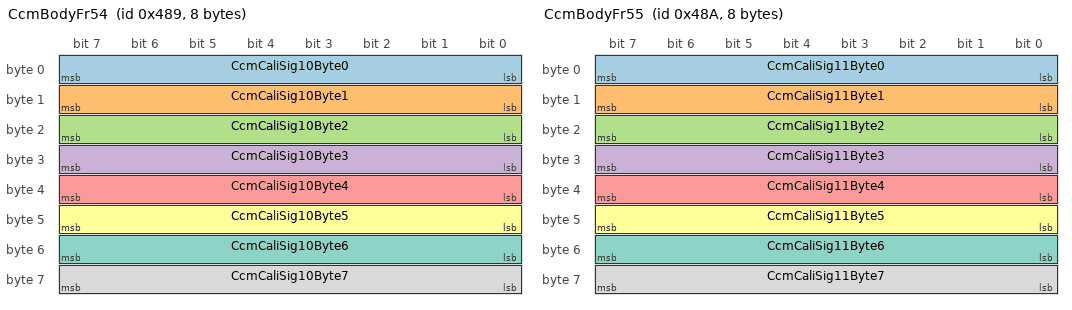
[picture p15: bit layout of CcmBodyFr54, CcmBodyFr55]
BO_ 1161 CcmBodyFr54: 8 CCM
 SG_ CcmCaliSig10Byte0 : 7|8@0+ (1,0) [0|255] "Unitless"  CEM
 SG_ CcmCaliSig10Byte1 : 15|8@0+ (1,0) [0|255] "Unitless"  CEM
 SG_ CcmCaliSig10Byte2 : 23|8@0+ (1,0) [0|255] "Unitless"  CEM
 SG_ CcmCaliSig10Byte3 : 31|8@0+ (1,0) [0|255] "Unitless"  CEM
 SG_ CcmCaliSig10Byte4 : 39|8@0+ (1,0) [0|255] "Unitless"  CEM
 SG_ CcmCaliSig10Byte5 : 47|8@0+ (1,0) [0|255] "Unitless"  CEM
 SG_ CcmCaliSig10Byte6 : 55|8@0+ (1,0) [0|255] "Unitless"  CEM
 SG_ CcmCaliSig10Byte7 : 63|8@0+ (1,0) [0|255] "Unitless"  CEM

BO_ 1162 CcmBodyFr55: 8 CCM
 SG_ CcmCaliSig11Byte0 : 7|8@0+ (1,0) [0|255] "Unitless"  CEM
 SG_ CcmCaliSig11Byte1 : 15|8@0+ (1,0) [0|255] "Unitless"  CEM
 SG_ CcmCaliSig11Byte2 : 23|8@0+ (1,0) [0|255] "Unitless"  CEM
 SG_ CcmCaliSig11Byte3 : 31|8@0+ (1,0) [0|255] "Unitless"  CEM
 SG_ CcmCaliSig11Byte4 : 39|8@0+ (1,0) [0|255] "Unitless"  CEM
 SG_ CcmCaliSig11Byte5 : 47|8@0+ (1,0) [0|255] "Unitless"  CEM
 SG_ CcmCaliSig11Byte6 : 55|8@0+ (1,0) [0|255] "Unitless"  CEM
 SG_ CcmCaliSig11Byte7 : 63|8@0+ (1,0) [0|255] "Unitless"  CEM

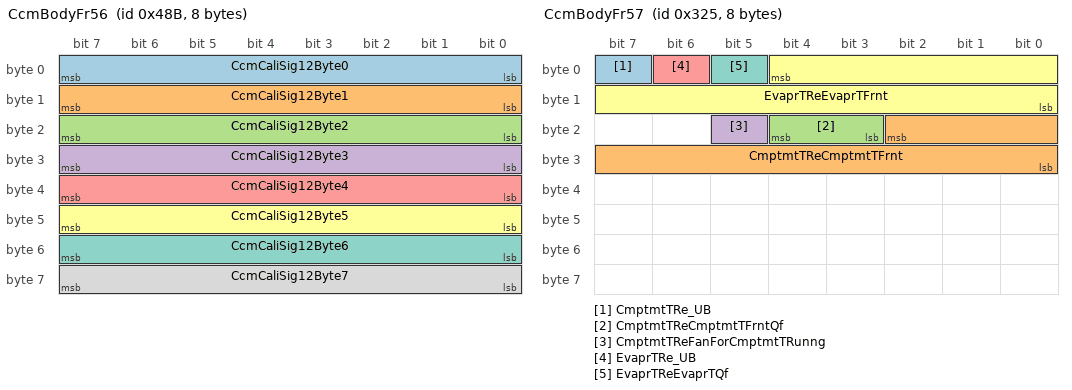
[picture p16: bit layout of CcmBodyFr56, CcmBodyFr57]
BO_ 1163 CcmBodyFr56: 8 CCM
 SG_ CcmCaliSig12Byte0 : 7|8@0+ (1,0) [0|255] "Unitless"  CEM
 SG_ CcmCaliSig12Byte1 : 15|8@0+ (1,0) [0|255] "Unitless"  CEM
 SG_ CcmCaliSig12Byte2 : 23|8@0+ (1,0) [0|255] "Unitless"  CEM
 SG_ CcmCaliSig12Byte3 : 31|8@0+ (1,0) [0|255] "Unitless"  CEM
 SG_ CcmCaliSig12Byte4 : 39|8@0+ (1,0) [0|255] "Unitless"  CEM
 SG_ CcmCaliSig12Byte5 : 47|8@0+ (1,0) [0|255] "Unitless"  CEM
 SG_ CcmCaliSig12Byte6 : 55|8@0+ (1,0) [0|255] "Unitless"  CEM
 SG_ CcmCaliSig12Byte7 : 63|8@0+ (1,0) [0|255] "Unitless"  CEM

BO_ 805 CcmBodyFr57: 8 CCM
 SG_ CmptmtTRe_UB : 7|1@0+ (1,0) [0|1] ""  CEM
 SG_ CmptmtTReCmptmtTFrnt : 18|11@0+ (0.1,-60) [-60|125] "degC"  CEM
 SG_ CmptmtTReCmptmtTFrntQf : 20|2@0+ (1,0) [0|3] ""  CEM
 SG_ CmptmtTReFanForCmptmtTRunng : 21|1@0+ (1,0) [0|1] ""  CEM
 SG_ EvaprTRe_UB : 6|1@0+ (1,0) [0|1] ""  CEM
 SG_ EvaprTReEvaprTFrnt : 4|13@0- (0.1,0) [-256|255.9] "degC"  CEM
 SG_ EvaprTReEvaprTQf : 5|1@0+ (1,0) [0|1] ""  CEM

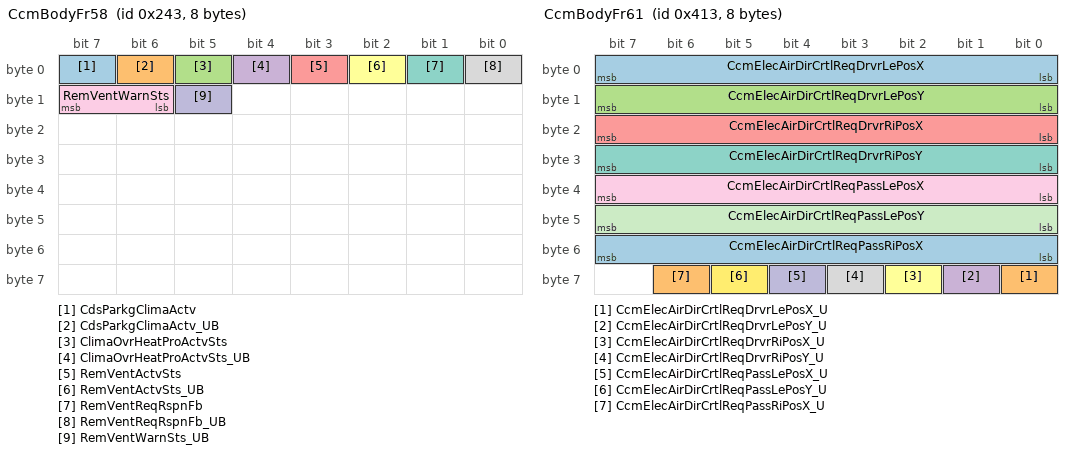
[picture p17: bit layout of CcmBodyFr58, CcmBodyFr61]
BO_ 579 CcmBodyFr58: 8 CCM
 SG_ CdsParkgClimaActv : 7|1@0+ (1,0) [0|1] ""  CEM
 SG_ CdsParkgClimaActv_UB : 6|1@0+ (1,0) [0|1] ""  CEM
 SG_ ClimaOvrHeatProActvSts : 5|1@0+ (1,0) [0|1] ""  CEM
 SG_ ClimaOvrHeatProActvSts_UB : 4|1@0+ (1,0) [0|1] ""  CEM
 SG_ RemVentActvSts : 3|1@0+ (1,0) [0|1] ""  CEM
 SG_ RemVentActvSts_UB : 2|1@0+ (1,0) [0|1] ""  CEM
 SG_ RemVentReqRspnFb : 1|1@0+ (1,0) [0|1] ""  CEM
 SG_ RemVentReqRspnFb_UB : 0|1@0+ (1,0) [0|1] ""  CEM
 SG_ RemVentWarnSts : 15|2@0+ (1,0) [0|3] ""  CEM
 SG_ RemVentWarnSts_UB : 13|1@0+ (1,0) [0|1] ""  CEM

BO_ 1043 CcmBodyFr61: 8 CCM
 SG_ CcmElecAirDirCrtlReqDrvrLePosX : 7|8@0+ (1,0) [0|255] "Unitless"  CEM
 SG_ CcmElecAirDirCrtlReqDrvrLePosX_U : 56|1@0+ (1,0) [0|1] ""  CEM
 SG_ CcmElecAirDirCrtlReqDrvrLePosY : 15|8@0+ (1,0) [0|255] "Unitless"  CEM
 SG_ CcmElecAirDirCrtlReqDrvrLePosY_U : 57|1@0+ (1,0) [0|1] ""  CEM
 SG_ CcmElecAirDirCrtlReqDrvrRiPosX : 23|8@0+ (1,0) [0|255] "Unitless"  CEM
 SG_ CcmElecAirDirCrtlReqDrvrRiPosX_U : 58|1@0+ (1,0) [0|1] ""  CEM
 SG_ CcmElecAirDirCrtlReqDrvrRiPosY : 31|8@0+ (1,0) [0|255] "Unitless"  CEM
 SG_ CcmElecAirDirCrtlReqDrvrRiPosY_U : 59|1@0+ (1,0) [0|1] ""  CEM
 SG_ CcmElecAirDirCrtlReqPassLePosX : 39|8@0+ (1,0) [0|255] "Unitless"  CEM
 SG_ CcmElecAirDirCrtlReqPassLePosX_U : 60|1@0+ (1,0) [0|1] ""  CEM
 SG_ CcmElecAirDirCrtlReqPassLePosY : 47|8@0+ (1,0) [0|255] "Unitless"  CEM
 SG_ CcmElecAirDirCrtlReqPassLePosY_U : 61|1@0+ (1,0) [0|1] ""  CEM
 SG_ CcmElecAirDirCrtlReqPassRiPosX : 55|8@0+ (1,0) [0|255] "Unitless"  CEM
 SG_ CcmElecAirDirCrtlReqPassRiPosX_U : 62|1@0+ (1,0) [0|1] ""  CEM

BO_ 1282 CcmBodyNMFr: 8 CCM
 SG_ PNC16_CCM : 16|1@0+ (1,0) [0|0] ""  TRM
 SG_ PNC17_CCM : 17|1@0+ (1,0) [0|0] ""  TRM
 SG_ PNC18_CCM : 18|1@0+ (1,0) [0|0] ""  TRM
 SG_ PNC19_CCM : 19|1@0+ (1,0) [0|0] ""  TRM
 SG_ PNC20_CCM : 20|1@0+ (1,0) [0|0] ""  TRM
 SG_ PNC21_CCM : 21|1@0+ (1,0) [0|0] ""  TRM
 SG_ PNC22_CCM : 22|1@0+ (1,0) [0|0] ""  TRM
 SG_ PNC23_CCM : 23|1@0+ (1,0) [0|0] ""  TRM
 SG_ PNC24_CCM : 24|1@0+ (1,0) [0|0] ""  TRM
 SG_ PNC25_CCM : 25|1@0+ (1,0) [0|0] ""  TRM
 SG_ PNC26_CCM : 26|1@0+ (1,0) [0|0] ""  TRM
 SG_ PNC27_CCM : 27|1@0+ (1,0) [0|0] ""  TRM
 SG_ PNC28_CCM : 28|1@0+ (1,0) [0|0] ""  TRM
 SG_ PNC29_CCM : 29|1@0+ (1,0) [0|0] ""  TRM
 SG_ PNC30_CCM : 30|1@0+ (1,0) [0|0] ""  TRM
 SG_ PNC31_CCM : 31|1@0+ (1,0) [0|0] ""  TRM
 SG_ PNC32_CCM : 32|1@0+ (1,0) [0|0] ""  TRM
 SG_ PNC33_CCM : 33|1@0+ (1,0) [0|0] ""  TRM
 SG_ PNC34_CCM : 34|1@0+ (1,0) [0|0] ""  TRM
 SG_ PNC35_CCM : 35|1@0+ (1,0) [0|0] ""  TRM
 SG_ PNC36_CCM : 36|1@0+ (1,0) [0|0] ""  TRM
 SG_ PNC37_CCM : 37|1@0+ (1,0) [0|0] ""  TRM
 SG_ PNC38_CCM : 38|1@0+ (1,0) [0|0] ""  TRM
 SG_ PNC39_CCM : 39|1@0+ (1,0) [0|0] ""  TRM
 SG_ PNC40_CCM : 40|1@0+ (1,0) [0|0] ""  TRM
 SG_ PNC41_CCM : 41|1@0+ (1,0) [0|0] ""  TRM
 SG_ PNC42_CCM : 42|1@0+ (1,0) [0|0] ""  TRM
 SG_ NM_PNI_CCM : 14|1@0+ (1,0) [0|0] ""  TRM
 SG_ NM_AW_CCM : 12|1@0+ (1,0) [0|0] ""  TRM
 SG_ NM_CS_CCM : 11|1@0+ (1,0) [0|0] ""  TRM
 SG_ NM_RMR_CCM : 8|1@0+ (1,0) [0|0] ""  TRM
 SG_ NM_NodeID_CCM : 7|8@0+ (1,0) [0|0] ""  TRM

BO_ 1346 CcmBodyVFCVectorFr: 8 CCM
 SG_ VFCVectorCCMBlockID : 1|2@0+ (1,0) [0|3] "Unitless"  ETC
 SG_ VFCVectorCCMVFCid0 : 2|1@0+ (1,0) [0|1] ""  ETC
 SG_ VFCVectorCCMVFCid1 : 3|1@0+ (1,0) [0|1] ""  ETC
 SG_ VFCVectorCCMVFCid10 : 12|1@0+ (1,0) [0|1] ""  ETC
 SG_ VFCVectorCCMVFCid11 : 13|1@0+ (1,0) [0|1] ""  ETC
 SG_ VFCVectorCCMVFCid12 : 14|1@0+ (1,0) [0|1] ""  ETC
 SG_ VFCVectorCCMVFCid13 : 15|1@0+ (1,0) [0|1] ""  ETC
 SG_ VFCVectorCCMVFCid14 : 16|1@0+ (1,0) [0|1] ""  ETC
 SG_ VFCVectorCCMVFCid15 : 17|1@0+ (1,0) [0|1] ""  ETC
 SG_ VFCVectorCCMVFCid16 : 18|1@0+ (1,0) [0|1] ""  ETC
 SG_ VFCVectorCCMVFCid17 : 19|1@0+ (1,0) [0|1] ""  ETC
 SG_ VFCVectorCCMVFCid18 : 20|1@0+ (1,0) [0|1] ""  ETC
 SG_ VFCVectorCCMVFCid19 : 21|1@0+ (1,0) [0|1] ""  ETC
 SG_ VFCVectorCCMVFCid2 : 4|1@0+ (1,0) [0|1] ""  ETC
 SG_ VFCVectorCCMVFCid20 : 22|1@0+ (1,0) [0|1] ""  ETC
 SG_ VFCVectorCCMVFCid21 : 23|1@0+ (1,0) [0|1] ""  ETC
 SG_ VFCVectorCCMVFCid22 : 24|1@0+ (1,0) [0|1] ""  ETC
 SG_ VFCVectorCCMVFCid23 : 25|1@0+ (1,0) [0|1] ""  ETC
 SG_ VFCVectorCCMVFCid24 : 26|1@0+ (1,0) [0|1] ""  ETC
 SG_ VFCVectorCCMVFCid25 : 27|1@0+ (1,0) [0|1] ""  ETC
 SG_ VFCVectorCCMVFCid26 : 28|1@0+ (1,0) [0|1] ""  ETC
 SG_ VFCVectorCCMVFCid27 : 29|1@0+ (1,0) [0|1] ""  ETC
 SG_ VFCVectorCCMVFCid28 : 30|1@0+ (1,0) [0|1] ""  ETC
 SG_ VFCVectorCCMVFCid29 : 31|1@0+ (1,0) [0|1] ""  ETC
 SG_ VFCVectorCCMVFCid3 : 5|1@0+ (1,0) [0|1] ""  ETC
 SG_ VFCVectorCCMVFCid30 : 32|1@0+ (1,0) [0|1] ""  ETC
 SG_ VFCVectorCCMVFCid31 : 33|1@0+ (1,0) [0|1] ""  ETC
 SG_ VFCVectorCCMVFCid32 : 34|1@0+ (1,0) [0|1] ""  ETC
 SG_ VFCVectorCCMVFCid33 : 35|1@0+ (1,0) [0|1] ""  ETC
 SG_ VFCVectorCCMVFCid34 : 36|1@0+ (1,0) [0|1] ""  ETC
 SG_ VFCVectorCCMVFCid35 : 37|1@0+ (1,0) [0|1] ""  ETC
 SG_ VFCVectorCCMVFCid36 : 38|1@0+ (1,0) [0|1] ""  ETC
 SG_ VFCVectorCCMVFCid37 : 39|1@0+ (1,0) [0|1] ""  ETC
 SG_ VFCVectorCCMVFCid38 : 40|1@0+ (1,0) [0|1] ""  ETC
 SG_ VFCVectorCCMVFCid39 : 41|1@0+ (1,0) [0|1] ""  ETC
 SG_ VFCVectorCCMVFCid4 : 6|1@0+ (1,0) [0|1] ""  ETC
 SG_ VFCVectorCCMVFCid40 : 42|1@0+ (1,0) [0|1] ""  ETC
 SG_ VFCVectorCCMVFCid41 : 43|1@0+ (1,0) [0|1] ""  ETC
 SG_ VFCVectorCCMVFCid42 : 44|1@0+ (1,0) [0|1] ""  ETC
 SG_ VFCVectorCCMVFCid43 : 45|1@0+ (1,0) [0|1] ""  ETC
 SG_ VFCVectorCCMVFCid44 : 46|1@0+ (1,0) [0|1] ""  ETC
 SG_ VFCVectorCCMVFCid45 : 47|1@0+ (1,0) [0|1] ""  ETC
 SG_ VFCVectorCCMVFCid46 : 48|1@0+ (1,0) [0|1] ""  ETC
 SG_ VFCVectorCCMVFCid47 : 49|1@0+ (1,0) [0|1] ""  ETC
 SG_ VFCVectorCCMVFCid48 : 50|1@0+ (1,0) [0|1] ""  ETC
 SG_ VFCVectorCCMVFCid49 : 51|1@0+ (1,0) [0|1] ""  ETC
 SG_ VFCVectorCCMVFCid5 : 7|1@0+ (1,0) [0|1] ""  ETC
 SG_ VFCVectorCCMVFCid50 : 52|1@0+ (1,0) [0|1] ""  ETC
 SG_ VFCVectorCCMVFCid51 : 53|1@0+ (1,0) [0|1] ""  ETC
 SG_ VFCVectorCCMVFCid52 : 54|1@0+ (1,0) [0|1] ""  ETC
 SG_ VFCVectorCCMVFCid53 : 55|1@0+ (1,0) [0|1] ""  ETC
 SG_ VFCVectorCCMVFCid54 : 56|1@0+ (1,0) [0|1] ""  ETC
 SG_ VFCVectorCCMVFCid55 : 57|1@0+ (1,0) [0|1] ""  ETC
 SG_ VFCVectorCCMVFCid56 : 58|1@0+ (1,0) [0|1] ""  ETC
 SG_ VFCVectorCCMVFCid57 : 59|1@0+ (1,0) [0|1] ""  ETC
 SG_ VFCVectorCCMVFCid58 : 60|1@0+ (1,0) [0|1] ""  ETC
 SG_ VFCVectorCCMVFCid59 : 61|1@0+ (1,0) [0|1] ""  ETC
 SG_ VFCVectorCCMVFCid6 : 8|1@0+ (1,0) [0|1] ""  ETC
 SG_ VFCVectorCCMVFCid60 : 62|1@0+ (1,0) [0|1] ""  ETC
 SG_ VFCVectorCCMVFCid61 : 63|1@0+ (1,0) [0|1] ""  ETC
 SG_ VFCVectorCCMVFCid7 : 9|1@0+ (1,0) [0|1] ""  ETC
 SG_ VFCVectorCCMVFCid8 : 10|1@0+ (1,0) [0|1] ""  ETC
 SG_ VFCVectorCCMVFCid9 : 11|1@0+ (1,0) [0|1] ""  ETC

BO_ 1553 CcmToCemBodyDiagResFrame: 8 CCM
 SG_ CcmToCemBodyDiagResNpdu : 7|64@0+ (1,0) [0|0] ""  CEM

BO_ 1409 CcmToEtcXCPFr01: 8 CCM

BO_ 1410 CcmToEtcXCPFr02: 8 CCM

BO_ 1411 CcmToEtcXCPFr03: 8 CCM

BO_ 1412 CcmToEtcXCPFr04: 8 CCM

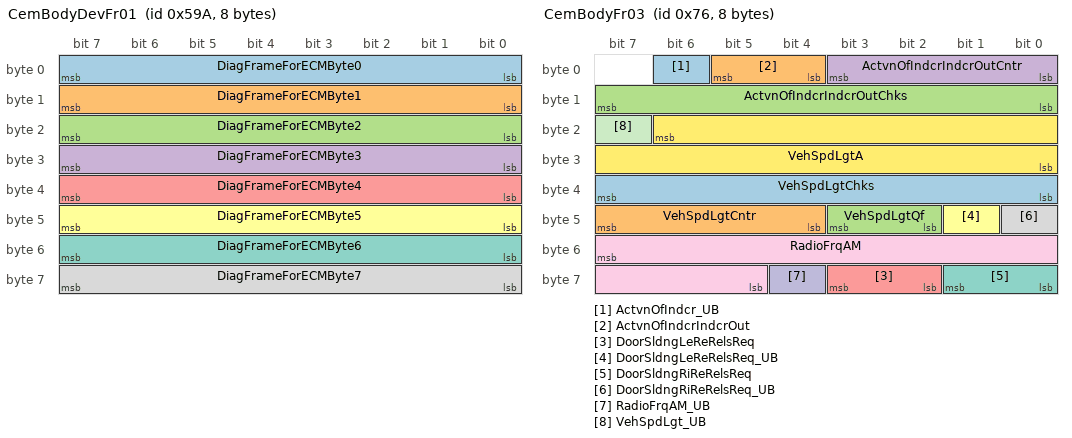
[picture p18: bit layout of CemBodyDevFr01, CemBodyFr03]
BO_ 1434 CemBodyDevFr01: 8 CEM
 SG_ DiagFrameForECMByte0 : 7|8@0+ (1,0) [0|255] "Unitless"  CCM
 SG_ DiagFrameForECMByte1 : 15|8@0+ (1,0) [0|255] "Unitless"  CCM
 SG_ DiagFrameForECMByte2 : 23|8@0+ (1,0) [0|255] "Unitless"  CCM
 SG_ DiagFrameForECMByte3 : 31|8@0+ (1,0) [0|255] "Unitless"  CCM
 SG_ DiagFrameForECMByte4 : 39|8@0+ (1,0) [0|255] "Unitless"  CCM
 SG_ DiagFrameForECMByte5 : 47|8@0+ (1,0) [0|255] "Unitless"  CCM
 SG_ DiagFrameForECMByte6 : 55|8@0+ (1,0) [0|255] "Unitless"  CCM
 SG_ DiagFrameForECMByte7 : 63|8@0+ (1,0) [0|255] "Unitless"  CCM

BO_ 32 CemBodyFr01: 8 CEM
 SG_ DigVideoRecSwt : 17|1@0+ (1,0) [0|1] ""  CCM
 SG_ DigVideoRecSwt_UB : 16|1@0+ (1,0) [0|1] ""  CCM
 SG_ DoorDrvrLockCmd : 7|4@0+ (1,0) [0|15] ""  DDM
 SG_ DoorDrvrLockCmd_UB : 3|1@0+ (1,0) [0|1] ""  DDM
 SG_ DoorDrvrRelsReq : 39|2@0+ (1,0) [0|3] ""  DDM
 SG_ DoorDrvrRelsReq_UB : 25|1@0+ (1,0) [0|1] ""  DDM
 SG_ DoorLeReLockCmd : 11|4@0+ (1,0) [0|15] ""  RLDM
 SG_ DoorLeReLockCmd_UB : 12|1@0+ (1,0) [0|1] ""  RLDM
 SG_ DoorLeReRelsReq : 37|2@0+ (1,0) [0|3] ""  RLDM
 SG_ DoorLeReRelsReq_UB : 62|1@0+ (1,0) [0|1] ""  RLDM
 SG_ DoorPassLockCmd : 23|4@0+ (1,0) [0|15] ""  PDM
 SG_ DoorPassLockCmd_UB : 19|1@0+ (1,0) [0|1] ""  PDM
 SG_ DoorPassRelsReq : 35|2@0+ (1,0) [0|3] ""  PDM
 SG_ DoorPassRelsReq_UB : 61|1@0+ (1,0) [0|1] ""  PDM
 SG_ DoorRiReLockCmd : 31|4@0+ (1,0) [0|15] ""  RRDM
 SG_ DoorRiReLockCmd_UB : 27|1@0+ (1,0) [0|1] ""  RRDM
 SG_ DoorRiReRelsReq : 33|2@0+ (1,0) [0|3] ""  RRDM
 SG_ DoorRiReRelsReq_UB : 24|1@0+ (1,0) [0|1] ""  RRDM
 SG_ GlvBoxOpenReqFromUI : 18|1@0+ (1,0) [0|1] ""  CCM
 SG_ GlvBoxOpenReqFromUI_UB : 26|1@0+ (1,0) [0|1] ""  CCM
 SG_ HmiSeatClima_UB : 63|1@0+ (1,0) [0|1] ""  CCM,SMD,SMP
 SG_ HmiSeatClimaHmiSeatHeatgForRowFi : 41|2@0+ (1,0) [0|3] ""  CCM,SMD,SMP
 SG_ HmiSeatClimaHmiSeatHeatgFor_0000 : 43|2@0+ (1,0) [0|3] ""  CCM,SMD,SMP
 SG_ HmiSeatClimaHmiSeatHeatgForRowSe : 45|2@0+ (1,0) [0|3] ""  CCM,SMD,SMP
 SG_ HmiSeatClimaHmiSeatHeatgFor_0001 : 47|2@0+ (1,0) [0|3] ""  CCM,SMD,SMP
 SG_ HmiSeatClimaHmiSeatVentnForRowFi : 49|2@0+ (1,0) [0|3] ""  CCM,SMD,SMP
 SG_ HmiSeatClimaHmiSeatVentnFor_0000 : 51|2@0+ (1,0) [0|3] ""  CCM,SMD,SMP
 SG_ HmiSeatClimaHmiSeatVentnForRowSe : 53|2@0+ (1,0) [0|3] ""  CCM,SMD,SMP
 SG_ HmiSeatClimaHmiSeatVentnFor_0001 : 55|2@0+ (1,0) [0|3] ""  CCM,SMD,SMP
 SG_ IndcrSts : 58|2@0+ (1,0) [0|3] ""  DDM,PDM,TRM
 SG_ IndcrSts_UB : 56|1@0+ (1,0) [0|1] ""  DDM,PDM,TRM
 SG_ TrlrLiBrkActvt : 60|1@0+ (1,0) [0|1] ""  TRM
 SG_ TrlrLiBrkActvt_UB : 59|1@0+ (1,0) [0|1] ""  TRM
 SG_ TrlrLiTurnIndcrActvt : 2|2@0+ (1,0) [0|3] ""  TRM
 SG_ TrlrLiTurnIndcrActvt_UB : 15|1@0+ (1,0) [0|1] ""  TRM

BO_ 64 CemBodyFr02: 8 CEM
 SG_ CabinCoolingReq : 60|1@0+ (1,0) [0|1] ""  CCM
 SG_ CabinCoolingReq_UB : 59|1@0+ (1,0) [0|1] ""  CCM
 SG_ DoorDrvrIntrSwtLedLockgCmd : 31|1@0+ (1,0) [0|1] ""  DDM
 SG_ DoorDrvrIntrSwtLedLockgCmd_UB : 30|1@0+ (1,0) [0|1] ""  DDM
 SG_ DoorDrvrSts : 55|2@0+ (1,0) [0|3] ""  CCM,DDM,ILCM,PDM,RLDM,RRDM,SMD,TRM
 SG_ DoorDrvrSts_UB : 53|1@0+ (1,0) [0|1] ""  CCM,DDM,ILCM,PDM,RLDM,RRDM,SMD,TRM
 SG_ DoorLeReSts : 43|2@0+ (1,0) [0|3] ""  CCM,DDM,ILCM,PDM,RLDM,RRDM,TRM
 SG_ DoorLeReSts_UB : 44|1@0+ (1,0) [0|1] ""  CCM,DDM,ILCM,PDM,RLDM,RRDM,TRM
 SG_ DoorPassIntrSwtLedLockgCmd : 39|1@0+ (1,0) [0|1] ""  PDM
 SG_ DoorPassIntrSwtLedLockgCmd_UB : 38|1@0+ (1,0) [0|1] ""  PDM
 SG_ IHUAPSts : 58|1@0+ (1,0) [0|1] ""  CCM
 SG_ IHUAPSts_UB : 57|1@0+ (1,0) [0|1] ""  CCM
 SG_ LcmaIndcnLe : 51|2@0+ (1,0) [0|3] ""  DDM,PDM
 SG_ LcmaIndcnLe_UB : 52|1@0+ (1,0) [0|1] ""  DDM,PDM
 SG_ LcmaIndcnRi : 63|2@0+ (1,0) [0|3] ""  DDM,PDM
 SG_ LcmaIndcnRi_UB : 36|1@0+ (1,0) [0|1] ""  DDM,PDM
 SG_ PassLoadAndStoreReq_UB : 29|1@0+ (1,0) [0|1] ""  SMP
 SG_ PassLoadAndStoreReqErgoPosn : 28|2@0+ (1,0) [0|3] ""  SMP
 SG_ PassLoadAndStoreReqErgoSetgEve : 26|3@0+ (1,0) [0|7] ""  SMP
 SG_ SaveSetgToMemPrmnt : 49|2@0+ (1,0) [0|3] ""  CCM,DDM,ILCM,SMD
 SG_ SaveSetgToMemPrmnt_UB : 37|1@0+ (1,0) [0|1] ""  CCM,DDM,ILCM,SMD
 SG_ TrNoKeyPrsntAcoustReq : 41|1@0+ (1,0) [0|1] ""  POT
 SG_ TrNoKeyPrsntAcoustReq_UB : 40|1@0+ (1,0) [0|1] ""  POT
 SG_ TrOpenerReq_UB : 61|1@0+ (1,0) [0|1] ""  POT
 SG_ TrOpenerReqTrigSrc : 18|3@0+ (1,0) [0|7] ""  POT
 SG_ TrOpenerReqTrOpenerReq : 21|3@0+ (1,0) [0|7] ""  POT
 SG_ TwliBriSts : 23|1@0+ (1,0) [0|1] ""  CCM,DDM,ILCM,PDM,RLDM,RRDM,TRM
 SG_ TwliBriSts_UB : 22|1@0+ (1,0) [0|1] ""  CCM,DDM,ILCM,PDM,RLDM,RRDM,TRM
 SG_ VehMtnSt_UB : 7|1@0+ (1,0) [0|1] ""  DDM,PDM,POT,RLDM,RRDM,TRM
 SG_ VehMtnStChks : 15|8@0+ (1,0) [0|255] "Unitless"  DDM,PDM,POT,RLDM,RRDM,TRM
 SG_ VehMtnStCntr : 6|4@0+ (1,0) [0|15] "Unitless"  DDM,PDM,POT,RLDM,RRDM,TRM
 SG_ VehMtnStVehMtnSt : 2|3@0+ (1,0) [0|7] ""  DDM,PDM,POT,RLDM,RRDM,TRM
 SG_ WinGlbCmd : 34|3@0+ (1,0) [0|7] ""  CCM,DDM,PDM,RLDM,RRDM
 SG_ WinGlbCmd_UB : 35|1@0+ (1,0) [0|1] ""  CCM,DDM,PDM,RLDM,RRDM

BO_ 118 CemBodyFr03: 8 CEM
 SG_ ActvnOfIndcr_UB : 6|1@0+ (1,0) [0|1] ""  DDM,PDM
 SG_ ActvnOfIndcrIndcrOut : 5|2@0+ (1,0) [0|3] ""  DDM,PDM
 SG_ ActvnOfIndcrIndcrOutChks : 15|8@0+ (1,0) [0|255] "Unitless"  DDM,PDM
 SG_ ActvnOfIndcrIndcrOutCntr : 3|4@0+ (1,0) [0|15] "Unitless"  DDM,PDM
 SG_ DoorSldngLeReRelsReq : 59|2@0+ (1,0) [0|3] ""  Vector_XXX
 SG_ DoorSldngLeReRelsReq_UB : 41|1@0+ (1,0) [0|1] ""  Vector_XXX
 SG_ DoorSldngRiReRelsReq : 57|2@0+ (1,0) [0|3] ""  Vector_XXX
 SG_ DoorSldngRiReRelsReq_UB : 40|1@0+ (1,0) [0|1] ""  Vector_XXX
 SG_ RadioFrqAM : 55|11@0+ (1,522) [522|1710] "Unitless"  DDM,PDM,POT,RLDM,RRDM
 SG_ RadioFrqAM_UB : 60|1@0+ (1,0) [0|1] ""  DDM,PDM,POT,RLDM,RRDM
 SG_ VehSpdLgt_UB : 23|1@0+ (1,0) [0|1] ""  CCM,DDM,ILCM,PDM,POT,RLDM,RRDM,SMD,SMP,TRM
 SG_ VehSpdLgtA : 22|15@0+ (0.00391,0) [0|125.0027] "m/s"  CCM,DDM,ILCM,PDM,POT,RLDM,RRDM,SMD,SMP,TRM
 SG_ VehSpdLgtChks : 39|8@0+ (1,0) [0|255] "Unitless"  CCM,DDM,ILCM,PDM,POT,RLDM,RRDM,SMD,SMP,TRM
 SG_ VehSpdLgtCntr : 47|4@0+ (1,0) [0|15] "Unitless"  CCM,DDM,ILCM,PDM,POT,RLDM,RRDM,SMD,SMP,TRM
 SG_ VehSpdLgtQf : 43|2@0+ (1,0) [0|3] ""  CCM,DDM,ILCM,PDM,POT,RLDM,RRDM,SMD,SMP,TRM

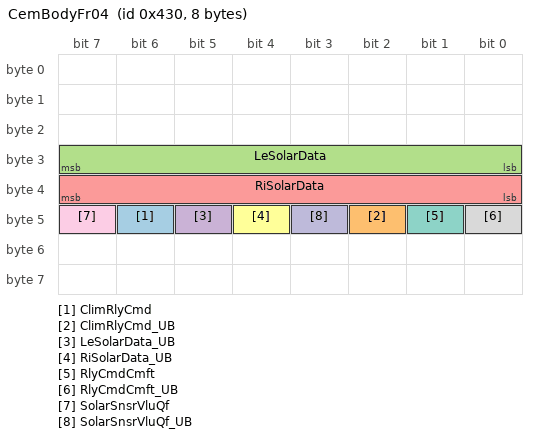
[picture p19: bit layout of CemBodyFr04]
BO_ 1072 CemBodyFr04: 8 CEM
 SG_ ClimRlyCmd : 46|1@0+ (1,0) [0|1] ""  CCM
 SG_ ClimRlyCmd_UB : 42|1@0+ (1,0) [0|1] ""  CCM
 SG_ LeSolarData : 31|8@0+ (5,0) [0|1275] "W/m2"  CCM
 SG_ LeSolarData_UB : 45|1@0+ (1,0) [0|1] ""  CCM
 SG_ RiSolarData : 39|8@0+ (5,0) [0|1275] "W/m2"  CCM
 SG_ RiSolarData_UB : 44|1@0+ (1,0) [0|1] ""  CCM
 SG_ RlyCmdCmft : 41|1@0+ (1,0) [0|1] ""  CCM
 SG_ RlyCmdCmft_UB : 40|1@0+ (1,0) [0|1] ""  CCM
 SG_ SolarSnsrVluQf : 47|1@0+ (1,0) [0|1] ""  CCM
 SG_ SolarSnsrVluQf_UB : 43|1@0+ (1,0) [0|1] ""  CCM

CM_ BU_ CEM "Central Electronic Module";
CM_ BU_ DDM "Driver Door Module";
CM_ BU_ ETC "External Tester Connector";
CM_ BU_ PDM "Passenger Door Module";
CM_ BU_ POT "Power Operated Tailgate";
CM_ BU_ RLDM "Rear Driver Door Module";
CM_ BU_ RRDM "Rear Passenger Door Module ";
CM_ BU_ TRM "Trailer Module";
CM_ SG_ 1435 DvlpFrameForCCMByte0 "Reserved developing frame byte0 for CCM.";
CM_ SG_ 1435 DvlpFrameForCCMByte1 "Reserved developing frame byte1 for CCM.";
CM_ SG_ 1435 DvlpFrameForCCMByte2 "Reserved developing frame byte2 for CCM.";
CM_ SG_ 1435 DvlpFrameForCCMByte3 "Reserved developing frame byte3 for CCM.";
CM_ SG_ 1435 DvlpFrameForCCMByte4 "Reserved developing frame byte4 for CCM.";
CM_ SG_ 1435 DvlpFrameForCCMByte5 "Reserved developing frame byte5 for CCM.";
CM_ SG_ 1435 DvlpFrameForCCMByte6 "Reserved developing frame byte6 for CCM.";
CM_ SG_ 1435 DvlpFrameForCCMByte7 "Reserved developing frame byte7 for CCM.";
CM_ SG_ 177 ClimaTiOfEnd "Informs of when the last pre-conditioning was ended.";
CM_ SG_ 177 EvaprTFrntEvaprTFrnt "Air temperature measured in HVAC after evaporator";
CM_ SG_ 177 EvaprTFrntEvaprTQf "Air temperature measured in HVAC after evaporator signal quality.";
CM_ SG_ 177 HvacCoolgEnaFrnt "Request cooling for front HVAC. ";
CM_ SG_ 177 HvacRecircAct "Amount of recirculated air in front HVAC. ";
CM_ SG_ 177 IntPm25LvlFrmClima "Inside PM 2.5 level of compartment.";
CM_ SG_ 37 BtnIllmn6Ccm "Rear frost function illumination.";
CM_ SG_ 37 BtnIllmnForWinDefrstFrntCcm "Front frost function illumination.";
CM_ SG_ 37 ClimaStsDisp "Climate status for Hmi.";
CM_ SG_ 37 HvacAirMFlowEstimd "Estimated total mass air flow in front HVAC. ";
CM_ SG_ 37 HvEgyDesForClima "Desired energy from high voltage system to use for climatisation";
CM_ SG_ 37 IntPm25VluFrmClima "Inside PM 2.5 value of compartment.";
CM_ SG_ 37 OutdPm25VluFrmClima "Outside PM2.5 value of compartment.";
CM_ SG_ 37 PrkgClimaWarn "Informs if anything has gone wrong with the parking climatisation.";
CM_ SG_ 512 ClimaActv "Informs if a parking climatisation is active (either pre- or post conditioning).";
CM_ SG_ 512 ClimaPwrCns "Actual current consumption of electric climate loads";
CM_ SG_ 512 ClimaPwrCritDes "Critical power level needed for electric climate loads";
CM_ SG_ 512 ClimaPwrNormDes "Desired power wanted for electric climate loads";
CM_ SG_ 512 LvlOfClimaCmft "Current Clean Zone level sent to HMI.";
CM_ SG_ 512 RemClimaActv "Remote climate start status.";
CM_ SG_ 512 SteerWhlHeatgPwrAllwd "Steering wheel heating power allowed percent.";
CM_ SG_ 289 CmptmtAirTEstimdAtRowFirstLoResl "Estimated compartment temperature at head level, first row";
CM_ SG_ 289 CmptmtAirTEstimdExtdComptmtT "Estimated compartment temperature with quality flag Estimated compartment Temperature";
CM_ SG_ 289 CmptmtAirTEstimdExtdQlyFlg "Estimated compartment temperature with quality flag Quality flag ";
CM_ SG_ 289 CmptmtTFrntCmptmtTFrnt "Measured temperature in compartment. ";
CM_ SG_ 289 CmptmtTFrntFanForCmptmtTRunng "Fan for component temperature requirement.";
CM_ SG_ 289 CmptmtTFrntQf "Component temperature sensor signal quality.";
CM_ SG_ 289 EngRunngReqByClima "Request from climate control to start engine or inhibit stop. Used maintain a desirable comfort level in compartment.";
CM_ SG_ 289 EngSpdIncIdleForClima "Request to increase idle speed. Used when current engine speed is insufficient for climate comfort";
CM_ SG_ 289 RlyCrashForClimaReq "Request to activate crash relay in order to have power supply for front blower.";
CM_ SG_ 1029 AirTFbFromClimaAirTFbFromClima "Air Temperature feedback in % from Climate control";
CM_ SG_ 1029 AirTFbFromClimaDataQf "Data quality signal";
CM_ SG_ 1029 ClimaCmptSts "Compartment climate status.";
CM_ SG_ 1029 ClimaDefrstSts "Defrost status.";
CM_ SG_ 1029 ClimaOvrHeatProActv "Over heat protection function activation status.";
CM_ SG_ 1029 CupHoldrActvAllwd "Cup holder activation power allowed for cup holder.";
CM_ SG_ 1029 HvacEvaprTSpFrnt "Set value for air temperature after evaporator in front HVAC";
CM_ SG_ 1029 HvacEvaprTSpRe "Set value for air temperature after evaporator in rear HVAC";
CM_ SG_ 1029 PwrEstimdAtStbForClima "Estimated power reduction in standby";
CM_ SG_ 1033 HvacAirTForRowFirstAtFlrLeEvaprT "First row left floor air temperature.";
CM_ SG_ 1033 HvacAirTForRowFirstAtFlrLeE_0000 "First row left floor air temperature quality flag.";
CM_ SG_ 1033 HvacAirTForRowFirstAtFlrRiEvaprT "First row right floor air temperature.";
CM_ SG_ 1033 HvacAirTForRowFirstAtFlrRiE_0000 "First row right floor air temperature quality flag";
CM_ SG_ 1033 HvacAirTForRowFirstAtVentLeEvapr "First row left ventilation air temperature.";
CM_ SG_ 1033 HvacAirTForRowFirstAtVentLe_0000 "First row left ventilation air temperature quality flag.";
CM_ SG_ 1033 HvacAirTForRowFirstAtVentRiEvapr "First row right ventilation air temperature.";
CM_ SG_ 1033 HvacAirTForRowFirstAtVentRi_0000 "First row right ventilation air temperature quality flag";
CM_ SG_ 1034 HvacAirTForRowSecAtFlrLeEvaprTFr "Second row left floor air temperature.";
CM_ SG_ 1034 HvacAirTForRowSecAtFlrLeEvaprTQf "Second row left floor air temperature quality flag.";
CM_ SG_ 1034 HvacAirTForRowSecAtFlrRiEvaprTFr "Second row right floor air temperature.";
CM_ SG_ 1034 HvacAirTForRowSecAtFlrRiEvaprTQf "Second row right floor air temperature quality flag.";
CM_ SG_ 1034 HvacAirTForRowSecAtVentLeEvaprTF "Second row left ventilation air temperature.";
CM_ SG_ 1034 HvacAirTForRowSecAtVentLeEvaprTQ "Second row left ventilation air temperature quality flag.";
CM_ SG_ 1034 HvacAirTForRowSecAtVentRiEvaprTF "Second row right ventilation air temperature.";
CM_ SG_ 1034 HvacAirTForRowSecAtVentRiEvaprTQ "Second row right ventilation air temperature quality flag.";
CM_ SG_ 933 HvacFanSet2HvacFanSpd2 "Fan speed.";
CM_ SG_ 933 HvacFanSts2HvacFanBattI2 "blower current.";
CM_ SG_ 933 HvacFanSts2HvacFanBattU2 "supply voltage.";
CM_ SG_ 933 HvacFanSts3HvacFanBattI "blower current.";
CM_ SG_ 933 HvacFanSts3HvacFanBattU "supply voltage.";
CM_ SG_ 933 HvacFanSts3HvacFanSpdFd "blower speed feedback";
CM_ SG_ 1037 RemClimaWarn "Remote climate activation failure feedback.";
CM_ SG_ 1037 ResrvdSigForECM1 "Reserved signal 1 for ECM.";
CM_ SG_ 1037 ResrvdSigForECM2 "Reserved signal 2 for ECM.";
CM_ SG_ 1037 ResrvdSigForECM3 "Reserved signal 3 for ECM.";
CM_ SG_ 1037 ResrvdSigForECM4 "Reserved signal 4 for ECM.";
CM_ SG_ 1037 WindIceDetdFrnt "Ice on the front windscreen is detected according to algorithm in CCM.";
CM_ SG_ 1037 WindIceDetdRe "Ice on the rear window and or exterior rear view mirrors is detected according to algorithm in CCM.";
CM_ SG_ 1040 CmptModForHp "Compartment status for heat pump system. Value is 0x0 vent, 0x1 cool, 0x2 heat, 0x3 cool defog, 0x4 heat defog, 0x5 to 0x255 reserved.";
CM_ SG_ 1040 HpReqCritSts "Heat pump critical request status.";
CM_ SG_ 1040 HvacCondsorTEvaprTFrnt "heat pump inner condensor actual temperature.";
CM_ SG_ 1040 HvacCondsorTEvaprTQf "heat pump inner condensor actual temperature quality flag.";
CM_ SG_ 1040 HvacCondsorTspEvaprTFrnt "heat pump inner condensor target temperture.";
CM_ SG_ 1040 HvacCondsorTspEvaprTQf "heat pump inner condensor target temperture signal quality.";
CM_ SG_ 1040 HvahBlwReq "Blower off request for Hvah short to battery error.";
CM_ SG_ 1040 HvahPwrReq "HVAH power consumption request.";
CM_ SG_ 1040 ReEvapVlvSts "Status of rear evaporator valve.";
CM_ SG_ 1040 RemClimaDelaySts "remote climate delay request status feedback.";
CM_ SG_ 1040 RemClimaExtnTiRspn "Remote climate delay time execution response.";
CM_ SG_ 1040 RemClimaHvRspn "Remote climate high voltage request receiving response to telematics system.";
CM_ SG_ 1040 RemClimaHvSts "Climate request high voltage status.";
CM_ SG_ 1049 ClimaSts "Climatisation status";
CM_ SG_ 1049 ElecDefrstReqMirrDefrstReq "Request to activate electric defrosters.  Mirror defroster request";
CM_ SG_ 1049 ElecDefrstReqWinDefrstFrntReq "Request to activate electric defrosters.  Windscreen defroster request";
CM_ SG_ 1049 ElecDefrstReqWinDefrstReReq "Request to activate electric defrosters.  Rear window defroster request";
CM_ SG_ 1049 FragCh1UseUpWrn "To remind customer the fragrance channel 1 use up.";
CM_ SG_ 1049 FragCh2UseUpWrn "To remind customer the fragrance channel 2 use up.";
CM_ SG_ 1049 FragCh3UseUpWrn "To remind customer the fragrance channel 3 use up.";
CM_ SG_ 1049 FragCh4UseUpWrn "To remind customer the fragrance channel 4 use up.";
CM_ SG_ 1049 FragCh5UseUpWrn "To remind customer the fragrance channel 5 use up.";
CM_ SG_ 1049 FragLvlFrmClima "Fragrance level status from climate.";
CM_ SG_ 1049 FragStsFrmClima "Fragrance use up and error warn from climate to Hmi.";
CM_ SG_ 1049 FrntHvacBlowerSts "Front blower status.";
CM_ SG_ 1049 HeatrAirTReq "Heater air temperature request.";
CM_ SG_ 1049 HvacCoolgEnaRe "Request cooling for rear HVAC";
CM_ SG_ 1049 HvacOsaAndRecActrQfForHp "Recirculation ratio for HVAC from CCM to Heatpump.";
CM_ SG_ 1049 HvahAirTsp "Air temperature target temperature at outlet of HVAH. Only used by EF1E.";
CM_ SG_ 1049 HvahHeatgReq "HVAH heater heating enable.";
CM_ SG_ 1049 IntPm25StsFrmClima "Interior Pm 2.5 sensor status feedback.";
CM_ SG_ 1049 OutdPm25LvlFrmClima "Outside PM 2.5 level of compartment.";
CM_ SG_ 1049 PostDrvgClimaAvl "Informs if post climatisation is available.";
CM_ SG_ 901 CcmElecAirDirCrtlReqPassRiPosY "VGA position for HMI";
CM_ SG_ 901 CcmIntCo2Conc "concentration of Co2";
CM_ SG_ 901 CcmIntCo2Lvl "Level of Co2 concentration";
CM_ SG_ 901 IntCo2Conc "In car CO2 concentration.";
CM_ SG_ 1145 CmptmtIntrMtrlTEstimdMtrlSnsrT "Material temperature";
CM_ SG_ 1145 CmptmtIntrMtrlTEstimdMtrlSnsrTQl "Materical quality flag";
CM_ SG_ 1145 EgyDesForClima "Desired energy to use for climatisation";
CM_ SG_ 1145 PwrAllwdForElecAirVentn "Power allowed for electrical ventilation motor.";
CM_ SG_ 1145 SunDataAzi "Sun azimuth angle.";
CM_ SG_ 1145 SunDataElevn "Sun elevation angle";
CM_ SG_ 1168 AmbTEstimdAmbTEstimd "Estimated/filtered/modelled amibient temperature based on information from ambient temp sensor and all other available temperature sensors and vehicle information.  Estimated ambient temperature";
CM_ SG_ 1168 AmbTEstimdQf "Estimated/filtered/modelled amibient temperature based on information from ambient temp sensor and all other available temperature sensors and vehicle information.  Quality factor for estimated signal";
CM_ SG_ 1168 CcmAirClngSts "CCM feedback AIU Status to HMI";
CM_ SG_ 1168 DrvrSeatHeatgPwrAllwd "Power limitation for driver seat climatization.";
CM_ SG_ 1168 PassSeatHeatgPwrAllwd "Power limitation for passenger seat climatization.";
CM_ SG_ 1168 SeatClimaDurgClimaHmiSeatHeatgFo "Seat heating status for first row left seat";
CM_ SG_ 1168 SeatClimaDurgClimaHmiSeatHe_0000 "Seat heating status for first row right seat.";
CM_ SG_ 1168 SeatClimaDurgClimaHmiSeatHe_0001 "Seat heating status for second row left status.";
CM_ SG_ 1168 SeatClimaDurgClimaHmiSeatHe_0002 "Seat heating status for second row right seat.";
CM_ SG_ 1168 SeatClimaDurgClimaHmiSeatVentnFo "Seat ventialtion status for first row left seat";
CM_ SG_ 1168 SeatClimaDurgClimaHmiSeatVe_0000 "Seat ventilation status for first row right";
CM_ SG_ 1168 SeatClimaDurgClimaHmiSeatVe_0001 "Seat ventilation status for second row left";
CM_ SG_ 1168 SeatClimaDurgClimaHmiSeatVe_0002 "Seat ventilation status for second row right";
CM_ SG_ 1168 SecRowLeSeatHeatgPwrAllwd "Power limitation for second row left seat climatization.";
CM_ SG_ 1184 DefrstMaxSts "Max defroster status";
CM_ SG_ 1184 ElecAirVentnAvlSts "Electrical air ventilation motor on, off, error status.";
CM_ SG_ 1184 FragCh1Id "Fragrance channel 1 ID from climate to Hmi.";
CM_ SG_ 1184 FragCh2Id "Fragrance channel 1 ID from climate to Hmi.";
CM_ SG_ 1184 FragCh3Id "Fragrance channel 1 ID from climate to Hmi.";
CM_ SG_ 1184 FragCh4Id "Fragrance channel 1 ID from climate to Hmi.";
CM_ SG_ 1184 FragCh5Id "Fragrance channel 1 ID from climate to Hmi.";
CM_ SG_ 1184 FragRefreshPopUp "This port is used to inform driver fragrance refresh is activated.";
CM_ SG_ 1184 IntPm25HiPopUp "Inside PM2.5 value high warning for IHU to Pop up.";
CM_ SG_ 1184 OutdAirQlyOutdAirQly "OutSide Air Quality";
CM_ SG_ 1184 OutdAirQlyQf "Quality Factor OutSide Air Quality";
CM_ SG_ 1184 OutdPm25StsFrmClima "Outside Pm 2.5 sensor status feedback.";
CM_ SG_ 1025 CcmRollgCntrSts "Ccm round counter signal to indicate CCM busoff status.";
CM_ SG_ 1025 ClimaActvAlrmSts "Siignal to inform IMS (Interior Motion Sensor) that some kind of climatisation/heating/cooling/fan running activity is ongoing.";
CM_ SG_ 1025 HvacHeatElmAirMFlowEstimd "Estimated total mass air flow in front HVAC heater element. ";
CM_ SG_ 1025 HvacHeatgReq "Hvac heating request";
CM_ SG_ 1025 HvacHeatrInletTempReqEvaprTFrnt "Front evaporator temperature.";
CM_ SG_ 1025 HvacHeatrInletTempReqEvaprTQf "Front evaporator signal quality.";
CM_ SG_ 1025 HvacHexAirTHvacAirTForHeatrFrnt "Temperature";
CM_ SG_ 1025 HvacHexAirTHvacAirTForHeatrFrntQ "Interpretation: 
SnsrDataNotOk - The accuracy of the data is undefinable
SnrsDataOk - The data is calculated with the specified accuracy";
CM_ SG_ 295 AirFragCh1RunngSts "Air fragrance channel 1 detection.";
CM_ SG_ 295 AirFragCh2RunngSts "Air fragrance channel 2 detection.";
CM_ SG_ 295 AirFragCh3RunngSts "Air fragrance channel 3 detection.";
CM_ SG_ 295 AirFragCh4RunngSts "Air fragrance channel 4 detection.";
CM_ SG_ 295 AirFragCh5RunngSts "Air fragrance channel 5 detection.";
CM_ SG_ 295 DrvrSeatVentnPwrAllwd "Allowed driver seat ventilation power.";
CM_ SG_ 295 EcoClimaSts "Eco climate status.";
CM_ SG_ 295 PassSeatVentnPwrAllwd "Allowed passenger seat ventilation power.";
CM_ SG_ 295 SecRowLeSeatVentnPwrAllwd "Allowed second row left seat ventilation power.";
CM_ SG_ 295 SecRowRiSeatHeatgPwrAllwd "Power limitation for second row right seat climatization.";
CM_ SG_ 295 SecRowRiSeatVentnPwrAllwd "Allowed second row right seat ventilation power.";
CM_ SG_ 295 SteerWhlHeatgDurgClima "Requests for remote steering wheel heating.";
CM_ SG_ 831 CarTiIntForClima "CCM internal mirror of CarTiGlb. Keeps counting when the bus signal is not available.";
CM_ SG_ 831 ClimaCoolgReqLvl "Climatization cooling level request.";
CM_ SG_ 831 ClimaHeatgReqLvl "Climatization heating level request.";
CM_ SG_ 831 ClimaOvrHeatPrtSts "Request for climate system to change usage mode from abandon to inactive.";
CM_ SG_ 831 EvaprVlvReStsExtdDiagcStsForCirc "The electric circuit of rear evaporator valve is open";
CM_ SG_ 831 EvaprVlvReStsExtdDiagcStsForShoT "Rear evaporator valve short to battery.";
CM_ SG_ 831 EvaprVlvReStsExtdDiagcStsFo_0000 "Rear evaporator valve short to ground";
CM_ SG_ 831 ReHvacBlowerSts "Rear HVAC blower status.";
CM_ SG_ 831 RlyCmftForClimaReq "Request to close comfort relay, used by ClimateControl to ensure all wanted sensors and actuators are power supplied.";
CM_ SG_ 831 UBoostReqByClima "Request of extra voltage to boost HVAC fan speed level";
CM_ SG_ 851 CcmIntelliClimaResd1 "CCM reserved signal for intelligent climate.";
CM_ SG_ 851 CcmIntelliClimaResd10 "CCM reserved signal for intelligent climate.";
CM_ SG_ 851 CcmIntelliClimaResd11 "CCM reserved signal for intelligent climate.";
CM_ SG_ 856 CcmIntelliClimaResd12 "CCM reserved signal for intelligent climate.";
CM_ SG_ 856 CcmIntelliClimaResd2 "CCM reserved signal for intelligent climate.";
CM_ SG_ 856 CcmIntelliClimaResd6 "CCM reserved signal for intelligent climate.";
CM_ SG_ 860 CcmIntelliClimaResd13 "CCM reserved signal for intelligent climate.";
CM_ SG_ 860 CcmIntelliClimaResd3 "CCM reserved signal for intelligent climate.";
CM_ SG_ 860 CcmIntelliClimaResd7 "CCM reserved signal for intelligent climate.";
CM_ SG_ 865 CcmIntelliClimaResd14 "CCM reserved signal for intelligent climate.";
CM_ SG_ 865 CcmIntelliClimaResd4 "CCM reserved signal for intelligent climate.";
CM_ SG_ 865 CcmIntelliClimaResd8 "CCM reserved signal for intelligent climate.";
CM_ SG_ 868 CcmIntelliClimaResd15 "CCM reserved signal for intelligent climate.";
CM_ SG_ 868 CcmIntelliClimaResd5 "CCM reserved signal for intelligent climate.";
CM_ SG_ 868 CcmIntelliClimaResd9 "CCM reserved signal for intelligent climate.";
CM_ SG_ 596 ElecVentnMotPwrCnsAct "Electrical ventilation motor actual power consumption.";
CM_ SG_ 596 ElecVentnMotPwrCnsDes "Electrical ventilation motor estimated power consumption.";
CM_ SG_ 596 HvacDefrstFlapActlPosn "Defrost actual flap position.";
CM_ SG_ 596 HvacModFlapActlPosnFrstRowLe "Vent actual flap position for first row.";
CM_ SG_ 596 HvacModFlapActlPosnFrstRowRi "Floor actual flap position for first row.";
CM_ SG_ 600 HvacModFlapActlPosnSecRowLe "Vent actual flap position for second row.";
CM_ SG_ 600 HvacModFlapActlPosnSecRowRi "Floor actual flap position for second row.";
CM_ SG_ 600 HvacOsaFlapActlPosn "OSA actual flap position.";
CM_ SG_ 600 HvacRecFlapActlPosn "Recirculation actual flap position.";
CM_ SG_ 604 HvacAirMFlowReEstimd "Estimated total mass air flow in rear HVAC.";
CM_ SG_ 604 HvacTempFlapActlPosnFrstRowLe "Left temperature actual flap position for first row.";
CM_ SG_ 604 HvacTempFlapActlPosnFrstRowRi "Right temperature actual flap position for first row.";
CM_ SG_ 604 HvacTempFlapActlPosnSecRowLe "Left temperature actual flap position for second row.";
CM_ SG_ 604 HvacTempFlapActlPosnSecRowRi "Right temperature actual flap position for second row.";
CM_ SG_ 604 InCarCo2HighWarn "In car CO2 concentration high warning for different level.";
CM_ SG_ 604 IntCo2RunSts "CO2 Sensor run status.";
CM_ SG_ 607 TgtHvacAirTForRowFirstLe "First row left target outlet air temperature.";
CM_ SG_ 607 TgtHvacAirTForRowFirstRi "First row right target outlet air temperature.";
CM_ SG_ 607 TgtHvacAirTForRowSecLe "Second row left target outlet air temperature.";
CM_ SG_ 607 TgtHvacAirTForRowSecRi "Second row right target outlet air temperature.";
CM_ SG_ 593 AutoDefrstReqPopUp "Auto defroster request pop up.";
CM_ SG_ 593 AutoDeHumPopUp "Pop up for compartment auto dehumidity to HMI system.";
CM_ SG_ 593 ClimaOffReq "Signal sent from CCM to IHU to request climate off.";
CM_ SG_ 593 ClimaOnReq "The climate activation request.";
CM_ SG_ 593 ClimaOvrHeatProRspn "Response signal used to notice telematics system that climate control system already receive setting signal for over heat protection from telematics system successfully.";
CM_ SG_ 593 ClimaOvrHeatProWarn "Feedback warning of Over heat protection function";
CM_ SG_ 593 Co2WarnForTelm "Indicating CO2 sensor error status.";
CM_ SG_ 593 DiDblLock "Disable double lock due to increasing incar carbon dioxide concentration.";
CM_ SG_ 593 RemStrtClimaRspn "remote start climatization response to telematics.";
CM_ SG_ 593 RoofOpnReqFrmClima "Roof window open request from climate.";
CM_ SG_ 593 SunRoofOpnPopUpForHmi "Pop up for high Co2 in compartment.";
CM_ SG_ 593 WinAndRoofReqFrmClima "To request open or close all windows and roof. 0x0: No req; 0x1: Open req; 0x2: Close req.";
CM_ SG_ 593 WinRfClsdReqForCoolgDwn "Windows and sunroof closed rquest due to poor cooling down or heating up.";
CM_ SG_ 1152 CcmCaliSig1Byte0 "Climate control internal calibration signals polling part 1 byte 0.";
CM_ SG_ 1152 CcmCaliSig1Byte1 "Climate control internal calibration signals polling part 1 byte 1.";
CM_ SG_ 1152 CcmCaliSig1Byte2 "Climate control internal calibration signals polling part 1 byte 2.";
CM_ SG_ 1152 CcmCaliSig1Byte3 "Climate control internal calibration signals polling part 1 byte 3.";
CM_ SG_ 1152 CcmCaliSig1Byte4 "Climate control internal calibration signals polling part 1 byte 4.";
CM_ SG_ 1152 CcmCaliSig1Byte5 "Climate control internal calibration signals polling part 1 byte 5.";
CM_ SG_ 1152 CcmCaliSig1Byte6 "Climate control internal calibration signals polling part 1 byte 6.";
CM_ SG_ 1152 CcmCaliSig1Byte7 "Climate control internal calibration signals polling part 1 byte 7.";
CM_ SG_ 1153 CcmCaliSig2Byte0 "Climate control internal calibration signals polling part 2 byte 0.";
CM_ SG_ 1153 CcmCaliSig2Byte1 "Climate control internal calibration signals polling part 2 byte 1.";
CM_ SG_ 1153 CcmCaliSig2Byte2 "Climate control internal calibration signals polling part 2 byte 2.";
CM_ SG_ 1153 CcmCaliSig2Byte3 "Climate control internal calibration signals polling part 2 byte 3.";
CM_ SG_ 1153 CcmCaliSig2Byte4 "Climate control internal calibration signals polling part 2 byte 4.";
CM_ SG_ 1153 CcmCaliSig2Byte5 "Climate control internal calibration signals polling part 2 byte 5.";
CM_ SG_ 1153 CcmCaliSig2Byte6 "Climate control internal calibration signals polling part 2 byte 6.";
CM_ SG_ 1153 CcmCaliSig2Byte7 "Climate control internal calibration signals polling part 2 byte 7.";
CM_ SG_ 1154 CcmCaliSig3Byte0 "Climate control internal calibration signals polling part 3 byte 0.";
CM_ SG_ 1154 CcmCaliSig3Byte1 "Climate control internal calibration signals polling part 3 byte 1.";
CM_ SG_ 1154 CcmCaliSig3Byte2 "Climate control internal calibration signals polling part 3 byte 2.";
CM_ SG_ 1154 CcmCaliSig3Byte3 "Climate control internal calibration signals polling part 3 byte 3.";
CM_ SG_ 1154 CcmCaliSig3Byte4 "Climate control internal calibration signals polling part 3 byte 4.";
CM_ SG_ 1154 CcmCaliSig3Byte5 "Climate control internal calibration signals polling part 3 byte 5.";
CM_ SG_ 1154 CcmCaliSig3Byte6 "Climate control internal calibration signals polling part 3 byte 6.";
CM_ SG_ 1154 CcmCaliSig3Byte7 "Climate control internal calibration signals polling part 3 byte 7.";
CM_ SG_ 1155 CcmCaliSig4Byte0 "Climate control internal calibration signals polling part 4 byte 0.";
CM_ SG_ 1155 CcmCaliSig4Byte1 "Climate control internal calibration signals polling part 4 byte 1.";
CM_ SG_ 1155 CcmCaliSig4Byte2 "Climate control internal calibration signals polling part 4 byte 2.";
CM_ SG_ 1155 CcmCaliSig4Byte3 "Climate control internal calibration signals polling part 4 byte 3.";
CM_ SG_ 1155 CcmCaliSig4Byte4 "Climate control internal calibration signals polling part 4 byte 4.";
CM_ SG_ 1155 CcmCaliSig4Byte5 "Climate control internal calibration signals polling part 4 byte 5.";
CM_ SG_ 1155 CcmCaliSig4Byte6 "Climate control internal calibration signals polling part 4 byte 6.";
CM_ SG_ 1155 CcmCaliSig4Byte7 "Climate control internal calibration signals polling part 4 byte 7.";
CM_ SG_ 1156 CcmCaliSig5Byte0 "Climate control internal calibration signals polling part 5 byte 0.";
CM_ SG_ 1156 CcmCaliSig5Byte1 "Climate control internal calibration signals polling part 5 byte 1.";
CM_ SG_ 1156 CcmCaliSig5Byte2 "Climate control internal calibration signals polling part 5 byte 2.";
CM_ SG_ 1156 CcmCaliSig5Byte3 "Climate control internal calibration signals polling part 5 byte 3.";
CM_ SG_ 1156 CcmCaliSig5Byte4 "Climate control internal calibration signals polling part 5 byte 4.";
CM_ SG_ 1156 CcmCaliSig5Byte5 "Climate control internal calibration signals polling part 5 byte 5.";
CM_ SG_ 1156 CcmCaliSig5Byte6 "Climate control internal calibration signals polling part 5 byte 6.";
CM_ SG_ 1156 CcmCaliSig5Byte7 "Climate control internal calibration signals polling part 5 byte 7.";
CM_ SG_ 1157 CcmCaliSig6Byte0 "Climate control internal calibration signals polling part 6 byte 0.";
CM_ SG_ 1157 CcmCaliSig6Byte1 "Climate control internal calibration signals polling part 6 byte 1.";
CM_ SG_ 1157 CcmCaliSig6Byte2 "Climate control internal calibration signals polling part 6 byte 2.";
CM_ SG_ 1157 CcmCaliSig6Byte3 "Climate control internal calibration signals polling part 6 byte 3.";
CM_ SG_ 1157 CcmCaliSig6Byte4 "Climate control internal calibration signals polling part 6 byte 4.";
CM_ SG_ 1157 CcmCaliSig6Byte5 "Climate control internal calibration signals polling part 6 byte 5.";
CM_ SG_ 1157 CcmCaliSig6Byte6 "Climate control internal calibration signals polling part 6 byte 6.";
CM_ SG_ 1157 CcmCaliSig6Byte7 "Climate control internal calibration signals polling part 6 byte 7.";
CM_ SG_ 1158 CcmCaliSig7Byte0 "Climate control internal calibration signals polling part 7 byte 0.";
CM_ SG_ 1158 CcmCaliSig7Byte1 "Climate control internal calibration signals polling part 7 byte 1.";
CM_ SG_ 1158 CcmCaliSig7Byte2 "Climate control internal calibration signals polling part 7 byte 2.";
CM_ SG_ 1158 CcmCaliSig7Byte3 "Climate control internal calibration signals polling part 7 byte 3.";
CM_ SG_ 1158 CcmCaliSig7Byte4 "Climate control internal calibration signals polling part 7 byte 4.";
CM_ SG_ 1158 CcmCaliSig7Byte5 "Climate control internal calibration signals polling part 7 byte 5.";
CM_ SG_ 1158 CcmCaliSig7Byte6 "Climate control internal calibration signals polling part 7 byte 6.";
CM_ SG_ 1158 CcmCaliSig7Byte7 "Climate control internal calibration signals polling part 7 byte 7.";
CM_ SG_ 1159 CcmCaliSig8Byte0 "Climate control internal calibration signals polling part 8 byte 0.";
CM_ SG_ 1159 CcmCaliSig8Byte1 "Climate control internal calibration signals polling part 8 byte 1.";
CM_ SG_ 1159 CcmCaliSig8Byte2 "Climate control internal calibration signals polling part 8 byte 2.";
CM_ SG_ 1159 CcmCaliSig8Byte3 "Climate control internal calibration signals polling part 8 byte 3.";
CM_ SG_ 1159 CcmCaliSig8Byte4 "Climate control internal calibration signals polling part 8 byte 4.";
CM_ SG_ 1159 CcmCaliSig8Byte5 "Climate control internal calibration signals polling part 8 byte 5.";
CM_ SG_ 1159 CcmCaliSig8Byte6 "Climate control internal calibration signals polling part 8 byte 6.";
CM_ SG_ 1159 CcmCaliSig8Byte7 "Climate control internal calibration signals polling part 8 byte 7.";
CM_ SG_ 1160 CcmCaliSig9Byte0 "Climate control internal calibration signals polling part 9 byte 0.";
CM_ SG_ 1160 CcmCaliSig9Byte1 "Climate control internal calibration signals polling part 9 byte 1.";
CM_ SG_ 1160 CcmCaliSig9Byte2 "Climate control internal calibration signals polling part 9 byte 2.";
CM_ SG_ 1160 CcmCaliSig9Byte3 "Climate control internal calibration signals polling part 9 byte 3.";
CM_ SG_ 1160 CcmCaliSig9Byte4 "Climate control internal calibration signals polling part 9 byte 4.";
CM_ SG_ 1160 CcmCaliSig9Byte5 "Climate control internal calibration signals polling part 9 byte 5.";
CM_ SG_ 1160 CcmCaliSig9Byte6 "Climate control internal calibration signals polling part 9 byte 6.";
CM_ SG_ 1160 CcmCaliSig9Byte7 "Climate control internal calibration signals polling part 9 byte 7.";
CM_ SG_ 1161 CcmCaliSig10Byte0 "Climate control internal calibration signals polling part 10 byte 0.";
CM_ SG_ 1161 CcmCaliSig10Byte1 "Climate control internal calibration signals polling part 10 byte 1.";
CM_ SG_ 1161 CcmCaliSig10Byte2 "Climate control internal calibration signals polling part 10 byte 2.";
CM_ SG_ 1161 CcmCaliSig10Byte3 "Climate control internal calibration signals polling part 10 byte 3.";
CM_ SG_ 1161 CcmCaliSig10Byte4 "Climate control internal calibration signals polling part 10 byte 4.";
CM_ SG_ 1161 CcmCaliSig10Byte5 "Climate control internal calibration signals polling part 10 byte 5.";
CM_ SG_ 1161 CcmCaliSig10Byte6 "Climate control internal calibration signals polling part 10 byte 6.";
CM_ SG_ 1161 CcmCaliSig10Byte7 "Climate control internal calibration signals polling part 10 byte 7.";
CM_ SG_ 1162 CcmCaliSig11Byte0 "Climate control internal calibration signals polling part 11 byte 0.";
CM_ SG_ 1162 CcmCaliSig11Byte1 "Climate control internal calibration signals polling part 11 byte 1.";
CM_ SG_ 1162 CcmCaliSig11Byte2 "Climate control internal calibration signals polling part 11 byte 2.";
CM_ SG_ 1162 CcmCaliSig11Byte3 "Climate control internal calibration signals polling part 11 byte 3.";
CM_ SG_ 1162 CcmCaliSig11Byte4 "Climate control internal calibration signals polling part 11 byte 4.";
CM_ SG_ 1162 CcmCaliSig11Byte5 "Climate control internal calibration signals polling part 11 byte 5.";
CM_ SG_ 1162 CcmCaliSig11Byte6 "Climate control internal calibration signals polling part 11 byte 6.";
CM_ SG_ 1162 CcmCaliSig11Byte7 "Climate control internal calibration signals polling part 11 byte 7.";
CM_ SG_ 1163 CcmCaliSig12Byte0 "Climate control internal calibration signals polling part 12 byte 0.";
CM_ SG_ 1163 CcmCaliSig12Byte1 "Climate control internal calibration signals polling part 12 byte 1.";
CM_ SG_ 1163 CcmCaliSig12Byte2 "Climate control internal calibration signals polling part 12 byte 2.";
CM_ SG_ 1163 CcmCaliSig12Byte3 "Climate control internal calibration signals polling part 12 byte 3.";
CM_ SG_ 1163 CcmCaliSig12Byte4 "Climate control internal calibration signals polling part 12 byte 4.";
CM_ SG_ 1163 CcmCaliSig12Byte5 "Climate control internal calibration signals polling part 12 byte 5.";
CM_ SG_ 1163 CcmCaliSig12Byte6 "Climate control internal calibration signals polling part 12 byte 6.";
CM_ SG_ 1163 CcmCaliSig12Byte7 "Climate control internal calibration signals polling part 12 byte 7.";
CM_ SG_ 805 CmptmtTReCmptmtTFrnt "Rear incar temperature.";
CM_ SG_ 805 CmptmtTReCmptmtTFrntQf "Rear incar temperature quality flag";
CM_ SG_ 805 CmptmtTReFanForCmptmtTRunng "Fan for component temperature requirement.";
CM_ SG_ 805 EvaprTReEvaprTFrnt "Actual air temperature after rear evaporator.";
CM_ SG_ 805 EvaprTReEvaprTQf "Actual air temperature quality flag after rear evaporator.";
CM_ SG_ 579 CdsParkgClimaActv "CDS parking climatization activation status.";
CM_ SG_ 579 ClimaOvrHeatProActvSts "Feedback over heat protection function enable/disable.";
CM_ SG_ 579 RemVentActvSts "Report remote ventilation activation status.";
CM_ SG_ 579 RemVentReqRspnFb "Feedback to telematics whether receive remote ventilation activate/deactivate successfully.";
CM_ SG_ 579 RemVentWarnSts "Reporting actuator or energy errors during RemVent ";
CM_ SG_ 1043 CcmElecAirDirCrtlReqDrvrLePosX "VGA position for HMI";
CM_ SG_ 1043 CcmElecAirDirCrtlReqDrvrLePosY "VGA position for HMI";
CM_ SG_ 1043 CcmElecAirDirCrtlReqDrvrRiPosX "VGA position for HMI";
CM_ SG_ 1043 CcmElecAirDirCrtlReqDrvrRiPosY "VGA position for HMI";
CM_ SG_ 1043 CcmElecAirDirCrtlReqPassLePosX "VGA position for HMI";
CM_ SG_ 1043 CcmElecAirDirCrtlReqPassLePosY "VGA position for HMI";
CM_ SG_ 1043 CcmElecAirDirCrtlReqPassRiPosX "VGA position for HMI";
CM_ SG_ 1346 VFCVectorCCMBlockID "Block Identifier";
CM_ SG_ 1346 VFCVectorCCMVFCid0 "VFC0";
CM_ SG_ 1346 VFCVectorCCMVFCid1 "VFC1";
CM_ SG_ 1346 VFCVectorCCMVFCid10 "VFC10";
CM_ SG_ 1346 VFCVectorCCMVFCid11 "VFC11";
CM_ SG_ 1346 VFCVectorCCMVFCid12 "VFC12";
CM_ SG_ 1346 VFCVectorCCMVFCid13 "VFC13";
CM_ SG_ 1346 VFCVectorCCMVFCid14 "VFC14";
CM_ SG_ 1346 VFCVectorCCMVFCid15 "VFC15";
CM_ SG_ 1346 VFCVectorCCMVFCid16 "VFC16";
CM_ SG_ 1346 VFCVectorCCMVFCid17 "VFC17";
CM_ SG_ 1346 VFCVectorCCMVFCid18 "VFC18";
CM_ SG_ 1346 VFCVectorCCMVFCid19 "VFC19";
CM_ SG_ 1346 VFCVectorCCMVFCid2 "VFC2";
CM_ SG_ 1346 VFCVectorCCMVFCid20 "VFC20";
CM_ SG_ 1346 VFCVectorCCMVFCid21 "VFC21";
CM_ SG_ 1346 VFCVectorCCMVFCid22 "VFC22";
CM_ SG_ 1346 VFCVectorCCMVFCid23 "VFC23";
CM_ SG_ 1346 VFCVectorCCMVFCid24 "VFC24";
CM_ SG_ 1346 VFCVectorCCMVFCid25 "VFC25";
CM_ SG_ 1346 VFCVectorCCMVFCid26 "VFC26";
CM_ SG_ 1346 VFCVectorCCMVFCid27 "VFC27";
CM_ SG_ 1346 VFCVectorCCMVFCid28 "VFC28";
CM_ SG_ 1346 VFCVectorCCMVFCid29 "VFC29";
CM_ SG_ 1346 VFCVectorCCMVFCid3 "VFC3";
CM_ SG_ 1346 VFCVectorCCMVFCid30 "VFC30";
CM_ SG_ 1346 VFCVectorCCMVFCid31 "VFC31";
CM_ SG_ 1346 VFCVectorCCMVFCid32 "VFC32";
CM_ SG_ 1346 VFCVectorCCMVFCid33 "VFC33";
CM_ SG_ 1346 VFCVectorCCMVFCid34 "VFC34";
CM_ SG_ 1346 VFCVectorCCMVFCid35 "VFC35";
CM_ SG_ 1346 VFCVectorCCMVFCid36 "VFC36";
CM_ SG_ 1346 VFCVectorCCMVFCid37 "VFC37";
CM_ SG_ 1346 VFCVectorCCMVFCid38 "VFC38";
CM_ SG_ 1346 VFCVectorCCMVFCid39 "VFC39";
CM_ SG_ 1346 VFCVectorCCMVFCid4 "VFC4";
CM_ SG_ 1346 VFCVectorCCMVFCid40 "VFC40";
CM_ SG_ 1346 VFCVectorCCMVFCid41 "VFC41";
CM_ SG_ 1346 VFCVectorCCMVFCid42 "VFC42";
CM_ SG_ 1346 VFCVectorCCMVFCid43 "VFC43";
CM_ SG_ 1346 VFCVectorCCMVFCid44 "VFC44";
CM_ SG_ 1346 VFCVectorCCMVFCid45 "VFC45";
CM_ SG_ 1346 VFCVectorCCMVFCid46 "VFC46";
CM_ SG_ 1346 VFCVectorCCMVFCid47 "VFC47";
CM_ SG_ 1346 VFCVectorCCMVFCid48 "VFC48";
CM_ SG_ 1346 VFCVectorCCMVFCid49 "VFC49";
CM_ SG_ 1346 VFCVectorCCMVFCid5 "VFC5";
CM_ SG_ 1346 VFCVectorCCMVFCid50 "VFC50";
CM_ SG_ 1346 VFCVectorCCMVFCid51 "VFC51";
CM_ SG_ 1346 VFCVectorCCMVFCid52 "VFC52";
CM_ SG_ 1346 VFCVectorCCMVFCid53 "VFC53";
CM_ SG_ 1346 VFCVectorCCMVFCid54 "VFC54";
CM_ SG_ 1346 VFCVectorCCMVFCid55 "VFC55";
CM_ SG_ 1346 VFCVectorCCMVFCid56 "VFC56";
CM_ SG_ 1346 VFCVectorCCMVFCid57 "VFC57";
CM_ SG_ 1346 VFCVectorCCMVFCid58 "VFC58";
CM_ SG_ 1346 VFCVectorCCMVFCid59 "VFC59";
CM_ SG_ 1346 VFCVectorCCMVFCid6 "VFC6";
CM_ SG_ 1346 VFCVectorCCMVFCid60 "VFC60";
CM_ SG_ 1346 VFCVectorCCMVFCid61 "VFC61";
CM_ SG_ 1346 VFCVectorCCMVFCid7 "VFC7";
CM_ SG_ 1346 VFCVectorCCMVFCid8 "VFC8";
CM_ SG_ 1346 VFCVectorCCMVFCid9 "VFC9";
CM_ SG_ 1434 DiagFrameForECMByte0 "Sequence number.";
CM_ SG_ 1434 DiagFrameForECMByte1 "ECM diagnostic message1.";
CM_ SG_ 1434 DiagFrameForECMByte2 "ECM diagnostic message2.";
CM_ SG_ 1434 DiagFrameForECMByte3 "ECM diagnostic message3.";
CM_ SG_ 1434 DiagFrameForECMByte4 "ECM diagnostic message4.";
CM_ SG_ 1434 DiagFrameForECMByte5 "ECM diagnostic message5.";
CM_ SG_ 1434 DiagFrameForECMByte6 "ECM diagnostic message6.";
CM_ SG_ 1434 DiagFrameForECMByte7 "ECM diagnostic message7.";
CM_ SG_ 32 DigVideoRecSwt "Digital video recorder";
CM_ SG_ 32 DoorDrvrLockCmd "DoorDrvrLockCmd - Driver Door Lock Command
Locking Command signal to driver door
LockActvnOff - Idle Command
LockActvnUnlck - Unlock door
LockActvnLock - Lock door
LockActvnSafe - Double lock door
LockActvnUnlckByCrash - Crash Unlock door";
CM_ SG_ 32 DoorDrvrRelsReq "DoorDrvrRelsReq - Driver Door Release Request
Request to release the driver door.
On - Release request
Off - No release request
Invalid1and2 - No release request";
CM_ SG_ 32 DoorLeReLockCmd "DoorLeReLockCmd - Left Rear Door Lock Command
Locking Command signal to left rear door
LockActvnOff - Idle Command
LockActvnUnlck - Unlock door
LockActvnLock - Lock door
LockActvnSafe - Double lock door
LockActvnUnlckByCrash - Crash Unlock door";
CM_ SG_ 32 DoorLeReRelsReq "DoorLeReRelsReq - Left Rear Door Release Request
Request to release the left rear door.
On - Release request
Off - No release request
Invalid1and2 - No release request";
CM_ SG_ 32 DoorPassLockCmd "DoorPassLockCmd - Passenger Door Lock Command
Locking Command signal to passenger door
LockActvnOff - Idle Command
LockActvnUnlck - Unlock door
LockActvnLock - Lock door
LockActvnSafe - Double lock door
LockActvnUnlckByCrash - Crash Unlock door";
CM_ SG_ 32 DoorPassRelsReq "DoorPassRelsReq - Passenger Door Release Request
Request to release the passenger door.
On - Release request
Off - No release request
Invalid1and2 - No release request";
CM_ SG_ 32 DoorRiReLockCmd "DoorRiReLockCmd - Right Rear Door Lock Command
Locking Command signal to right rear door
LockActvnOff - Idle Command
LockActvnUnlck - Unlock door
LockActvnLock - Lock door
LockActvnSafe - Double lock door
LockActvnUnlckByCrash - Crash Unlock door";
CM_ SG_ 32 DoorRiReRelsReq "DoorRiReRelsReq - Right Rear Door Release Request
Request to release the right rear door.
On - Release request
Off - No release request
Invalid1and2 - No release request";
CM_ SG_ 32 GlvBoxOpenReqFromUI "E-glove box open";
CM_ SG_ 32 HmiSeatClimaHmiSeatHeatgForRowFi "Heating level for seat first row left";
CM_ SG_ 32 HmiSeatClimaHmiSeatHeatgFor_0000 "Heating level for seat first row right";
CM_ SG_ 32 HmiSeatClimaHmiSeatHeatgForRowSe "Heating level for seat second row left";
CM_ SG_ 32 HmiSeatClimaHmiSeatHeatgFor_0001 "Heating level for seat second row right";
CM_ SG_ 32 HmiSeatClimaHmiSeatVentnForRowFi "Ventilation level for seat first row left";
CM_ SG_ 32 HmiSeatClimaHmiSeatVentnFor_0000 "Ventilation level for seat first row right";
CM_ SG_ 32 HmiSeatClimaHmiSeatVentnForRowSe "Ventilation level for seat second row left";
CM_ SG_ 32 HmiSeatClimaHmiSeatVentnFor_0001 "Ventilation level for seat second row right";
CM_ SG_ 32 IndcrSts "Provides the state and not the event of HWL/Direction Indicator.";
CM_ SG_ 32 TrlrLiBrkActvt "Brake Light request for trailer if connected.";
CM_ SG_ 32 TrlrLiTurnIndcrActvt "Turn Indicators activation Trailer.";
CM_ SG_ 64 CabinCoolingReq "Cabin cooling activation request. Internal to ThermalManagement.";
CM_ SG_ 64 DoorDrvrIntrSwtLedLockgCmd "DoorDrvrIntrSwtLedLockgCmd - Driver Door Interior Lockg Switch LED command.
This is the command signal for the locking LED located in the driver door interior central locking switch.
On - LED shall be on
Off - LED shall be off";
CM_ SG_ 64 DoorDrvrSts "DoorDrvrSts - Driver Door Status
Ukwn - Unknown status
Opend - Opened
Clsd - Closed";
CM_ SG_ 64 DoorLeReSts "DoorLeReSts - Left Rear Side Door Status.
Ukwn - Unknown status
Opend - Opened
Clsd - Closed";
CM_ SG_ 64 DoorPassIntrSwtLedLockgCmd "DoorPassIntrSwtLedLockgCmd - Passenger Door Interior Lockg Switch LED command.
This is the command signal for the locking LED located in the passenger door interior central locking switch.
On - LED shall be on
Off - LED shall be off";
CM_ SG_ 64 IHUAPSts "APs status";
CM_ SG_ 64 LcmaIndcnLe "LCA left waning signal.";
CM_ SG_ 64 LcmaIndcnRi "LCA right waning signal";
CM_ SG_ 64 PassLoadAndStoreReqErgoPosn "EgroPosn is passenger,memory position signal, contain PassMemPosn.Idle,PassMemPosn.MemBnk1,PassMemPosn.MemBnk2,PassMemPosn.MemBnk3.
";
CM_ SG_ 64 PassLoadAndStoreReqErgoSetgEve "ErgoSetgEve is contains five command signal,EveMemPosn.Idle,EveMemPosn.Store,EveMemPosn.Load, EveMemPosn.Stop, EveMemPosn.AutMovmt";
CM_ SG_ 64 SaveSetgToMemPrmnt "Signal for personal settings saving concept
0: Profile locked, no saving to be performed
1: On the event (toggle 0 to 1) settings shall be saved (manually saving)
2: Automatic saving";
CM_ SG_ 64 TrNoKeyPrsntAcoustReq "TrNoKeyPrsntAcoustReq - Request for audible feedback sound when no valid key is present.
The audible sound shall be given when the signal changes value from off to on.";
CM_ SG_ 64 TrOpenerReqTrigSrc "TrOpenerReq - Tailgate or Bootlid Opener Request
Request signal to POT ECU. Signal contains type of request and trig source of request.";
CM_ SG_ 64 TrOpenerReqTrOpenerReq "TrOpenerReq - Tailgate or Bootlid Opener Request
Request signal to POT ECU. Signal contains type of request and trig source of request";
CM_ SG_ 64 TwliBriSts "Day or night status signal. Lux value (not this signal) sent from SUS to CEM and CEM sets day or night signal.";
CM_ SG_ 64 VehMtnStChks "Vehicle motion state information based on wheel speed sensors. Provides information about vehicle stand still and vehicle rolling direction. Checksum for vehicle motion state";
CM_ SG_ 64 VehMtnStCntr "Vehicle motion state information based on wheel speed sensors. Provides information about vehicle stand still and vehicle rolling direction. Counter for vehicle motion state";
CM_ SG_ 64 VehMtnStVehMtnSt "Vehicle motion state information based on wheel speed sensors. Provides information about vehicle stand still and vehicle rolling direction. Vehicle motion state";
CM_ SG_ 64 WinGlbCmd "Global open/close command that tells when to perform a global open or close.";
CM_ SG_ 118 ActvnOfIndcrIndcrOut "Direction indicator command";
CM_ SG_ 118 ActvnOfIndcrIndcrOutChks "CheckSum";
CM_ SG_ 118 ActvnOfIndcrIndcrOutCntr "Coounter";
CM_ SG_ 118 DoorSldngLeReRelsReq "DoorSldngLeReRelsReq - Left Rear Sliding Door Release Request
Request to release the left rear sliding door.
On - Release request
Off - No release request
Invalid1and2 - No release request";
CM_ SG_ 118 DoorSldngRiReRelsReq "DoorSldngRiReRelsReq - Right Rear Sliding Door Release Request
Request to release the right rear sliding door.
On - Release request
Off - No release request
Invalid1and2 - No release request";
CM_ SG_ 118 RadioFrqAM "radio frequency analog";
CM_ SG_ 118 VehSpdLgtA "Vehicle speed longitudinal based on wheel speed sensors and longitudinal acceleration.";
CM_ SG_ 118 VehSpdLgtChks "Checksum";
CM_ SG_ 118 VehSpdLgtCntr "Counter";
CM_ SG_ 118 VehSpdLgtQf "Quality factor for vehicle speed as measured by wheel speed sensors and longitudinal acceleration.";
CM_ SG_ 1072 ClimRlyCmd "climate relay status";
CM_ SG_ 1072 LeSolarData "left side solar value for climate control.";
CM_ SG_ 1072 RiSolarData "right side solar value for climate control.";
CM_ SG_ 1072 RlyCmdCmft "Comfort Relat status";
CM_ SG_ 1072 SolarSnsrVluQf "Solar value quality flag for climate control.";
BA_DEF_  "Baudrate" INT 1000 1000000;
BA_DEF_ BO_  "GenMsgSendType" ENUM  "cyclic","spontaneous","not-used","not-used","not-used","cyclicAndSpontaneous","not-used","cyclicIfActive","NoMsgSendType";
BA_DEF_ BO_  "GenMsgCycleTime" INT 0 65536;
BA_DEF_ BO_  "GenMsgStartDelayTime" INT 0 65536;
BA_DEF_ BO_  "GenMsgDelayTime" INT 0 65536;
BA_DEF_ SG_  "GenSigSendType" ENUM  "Cyclic","OnWrite","OnWriteWithRepetition","OnChange","OnChangeWithRepetition","IfActive","IfActiveWithRepetition","NoSigSendType";
BA_DEF_ SG_  "GenSigStartValue" HEX 0 80000000;
BA_DEF_ BU_  "NmAsrNodeIdentifier" INT 0 255;
BA_DEF_ BU_  "NmAsrNode" ENUM  "No","Yes";
BA_DEF_  "DBName" STRING ;
BA_DEF_  "BusType" STRING ;
BA_DEF_  "ProtocolType" STRING ;
BA_DEF_ BO_  "GenMsgILSupport" ENUM  "No","Yes";
BA_DEF_ BO_  "NmAsrMessage" ENUM  "No","Yes";
BA_DEF_  "NmAsrBaseAddress" HEX 0 536870911;
BA_DEF_  "NmAsrMessageCount" INT 0 255;
BA_DEF_ BU_  "NodeLayerModules" STRING ;
BA_DEF_ BU_  "ILused" ENUM  "No","Yes";
BA_DEF_ SG_  "GenSigFuncType" ENUM  "NoFunction","n/a","n/a","n/a","n/a","n/a","n/a","n/a","n/a","n/a","n/a","n/a","n/a","n/a","n/a","CHK","CNTR","n/a","n/a","n/a","CNTR_AR_01","CRC_AR_01_BOTH","CRC_AR_01_ALT","CRC_AR_01_LOW","CRC_AR_01_NIBBLE","CNTR_AR_04","CRC_AR_04A","CNTR_AR_05","CRC_AR_05";
BA_DEF_ SG_  "GenSigDataID" STRING ;
BA_DEF_ SG_  "SystemSignalLongSymbol" STRING ;
BA_DEF_DEF_  "Baudrate" 1000;
BA_DEF_DEF_  "GenMsgSendType" "NoMsgSendType";
BA_DEF_DEF_  "GenMsgCycleTime" 0;
BA_DEF_DEF_  "GenMsgStartDelayTime" 0;
BA_DEF_DEF_  "GenMsgDelayTime" 0;
BA_DEF_DEF_  "GenSigSendType" "NoSigSendType";
BA_DEF_DEF_  "GenSigStartValue" 0;
BA_DEF_DEF_  "NmAsrNodeIdentifier" 0;
BA_DEF_DEF_  "NmAsrNode" "No";
BA_DEF_DEF_  "DBName" "";
BA_DEF_DEF_  "BusType" "";
BA_DEF_DEF_  "ProtocolType" "";
BA_DEF_DEF_  "GenMsgILSupport" "Yes";
BA_DEF_DEF_  "NmAsrMessage" "No";
BA_DEF_DEF_  "NmAsrBaseAddress" 1280;
BA_DEF_DEF_  "NmAsrMessageCount" 64;
BA_DEF_DEF_  "NodeLayerModules" "CANoeILNLSPA.dll";
BA_DEF_DEF_  "ILused" "Yes";
BA_DEF_DEF_  "GenSigFuncType" "NoFunction";
BA_DEF_DEF_  "GenSigDataID" "";
BA_DEF_DEF_  "SystemSignalLongSymbol" "";
BA_ "BusType" "CAN";
BA_ "ProtocolType" "CAN";
BA_ "Baudrate" 500000;
BA_ "DBName" "BodyCAN";
BA_ "NmAsrNodeIdentifier" BU_ CCM 2;
BA_ "NmAsrNode" BU_ CCM 1;
BA_ "NodeLayerModules" BU_ CCM "CANoeILNLSPA.dll,AsrNM33.dll";
BA_ "NmAsrNodeIdentifier" BU_ CEM 1;
BA_ "NmAsrNode" BU_ CEM 1;
BA_ "NodeLayerModules" BU_ CEM "CANoeILNLSPA.dll,AsrNM33.dll";
BA_ "NmAsrNodeIdentifier" BU_ DDM 3;
BA_ "NmAsrNode" BU_ DDM 1;
BA_ "NodeLayerModules" BU_ DDM "CANoeILNLSPA.dll,AsrNM33.dll";
BA_ "ILused" BU_ ETC 0;
BA_ "NmAsrNodeIdentifier" BU_ ILCM 21;
BA_ "NmAsrNode" BU_ ILCM 1;
BA_ "NodeLayerModules" BU_ ILCM "CANoeILNLSPA.dll,AsrNM33.dll";
BA_ "NmAsrNodeIdentifier" BU_ PDM 4;
BA_ "NmAsrNode" BU_ PDM 1;
BA_ "NodeLayerModules" BU_ PDM "CANoeILNLSPA.dll,AsrNM33.dll";
BA_ "NmAsrNodeIdentifier" BU_ POT 7;
BA_ "NmAsrNode" BU_ POT 1;
BA_ "NodeLayerModules" BU_ POT "CANoeILNLSPA.dll,AsrNM33.dll";
BA_ "NmAsrNodeIdentifier" BU_ RLDM 9;
BA_ "NmAsrNode" BU_ RLDM 1;
BA_ "NodeLayerModules" BU_ RLDM "CANoeILNLSPA.dll,AsrNM33.dll";
BA_ "NmAsrNodeIdentifier" BU_ RRDM 16;
BA_ "NmAsrNode" BU_ RRDM 1;
BA_ "NodeLayerModules" BU_ RRDM "CANoeILNLSPA.dll,AsrNM33.dll";
BA_ "NmAsrNodeIdentifier" BU_ SMD 18;
BA_ "NmAsrNode" BU_ SMD 1;
BA_ "NodeLayerModules" BU_ SMD "CANoeILNLSPA.dll,AsrNM33.dll";
BA_ "NmAsrNodeIdentifier" BU_ SMP 19;
BA_ "NmAsrNode" BU_ SMP 1;
BA_ "NodeLayerModules" BU_ SMP "CANoeILNLSPA.dll,AsrNM33.dll";
BA_ "NmAsrNodeIdentifier" BU_ TRM 10;
BA_ "NmAsrNode" BU_ TRM 1;
BA_ "NodeLayerModules" BU_ TRM "CANoeILNLSPA.dll,AsrNM33.dll";
BA_ "GenMsgSendType" BO_ 1435 0;
BA_ "GenMsgCycleTime" BO_ 1435 1250;
BA_ "GenMsgSendType" BO_ 177 0;
BA_ "GenMsgCycleTime" BO_ 177 20;
BA_ "GenMsgSendType" BO_ 37 0;
BA_ "GenMsgCycleTime" BO_ 37 20;
BA_ "GenMsgSendType" BO_ 512 0;
BA_ "GenMsgCycleTime" BO_ 512 90;
BA_ "GenMsgSendType" BO_ 289 0;
BA_ "GenMsgCycleTime" BO_ 289 30;
BA_ "GenMsgSendType" BO_ 1029 0;
BA_ "GenMsgCycleTime" BO_ 1029 150;
BA_ "GenMsgSendType" BO_ 1033 0;
BA_ "GenMsgCycleTime" BO_ 1033 250;
BA_ "GenMsgSendType" BO_ 1034 0;
BA_ "GenMsgCycleTime" BO_ 1034 150;
BA_ "GenMsgSendType" BO_ 933 0;
BA_ "GenMsgCycleTime" BO_ 933 400;
BA_ "GenMsgSendType" BO_ 1037 0;
BA_ "GenMsgCycleTime" BO_ 1037 150;
BA_ "GenMsgSendType" BO_ 1040 0;
BA_ "GenMsgCycleTime" BO_ 1040 150;
BA_ "GenMsgSendType" BO_ 1049 0;
BA_ "GenMsgCycleTime" BO_ 1049 150;
BA_ "GenMsgSendType" BO_ 901 0;
BA_ "GenMsgCycleTime" BO_ 901 480;
BA_ "GenMsgSendType" BO_ 1145 0;
BA_ "GenMsgCycleTime" BO_ 1145 1000;
BA_ "GenMsgSendType" BO_ 1168 0;
BA_ "GenMsgCycleTime" BO_ 1168 60;
BA_ "GenMsgSendType" BO_ 1184 0;
BA_ "GenMsgCycleTime" BO_ 1184 150;
BA_ "GenMsgSendType" BO_ 1025 0;
BA_ "GenMsgCycleTime" BO_ 1025 500;
BA_ "GenMsgSendType" BO_ 295 0;
BA_ "GenMsgCycleTime" BO_ 295 100;
BA_ "GenMsgSendType" BO_ 831 0;
BA_ "GenMsgCycleTime" BO_ 831 200;
BA_ "GenMsgSendType" BO_ 851 0;
BA_ "GenMsgCycleTime" BO_ 851 1000;
BA_ "GenMsgSendType" BO_ 856 0;
BA_ "GenMsgCycleTime" BO_ 856 1000;
BA_ "GenMsgSendType" BO_ 860 0;
BA_ "GenMsgCycleTime" BO_ 860 1000;
BA_ "GenMsgSendType" BO_ 865 0;
BA_ "GenMsgCycleTime" BO_ 865 1000;
BA_ "GenMsgSendType" BO_ 868 0;
BA_ "GenMsgCycleTime" BO_ 868 1000;
BA_ "GenMsgSendType" BO_ 596 0;
BA_ "GenMsgCycleTime" BO_ 596 900;
BA_ "GenMsgSendType" BO_ 600 0;
BA_ "GenMsgCycleTime" BO_ 600 900;
BA_ "GenMsgSendType" BO_ 604 0;
BA_ "GenMsgCycleTime" BO_ 604 300;
BA_ "GenMsgSendType" BO_ 607 0;
BA_ "GenMsgCycleTime" BO_ 607 900;
BA_ "GenMsgSendType" BO_ 593 1;
BA_ "GenMsgDelayTime" BO_ 593 100;
BA_ "GenMsgSendType" BO_ 1152 0;
BA_ "GenMsgCycleTime" BO_ 1152 1000;
BA_ "GenMsgSendType" BO_ 1153 0;
BA_ "GenMsgCycleTime" BO_ 1153 1000;
BA_ "GenMsgSendType" BO_ 1154 0;
BA_ "GenMsgCycleTime" BO_ 1154 1000;
BA_ "GenMsgSendType" BO_ 1155 0;
BA_ "GenMsgCycleTime" BO_ 1155 1000;
BA_ "GenMsgSendType" BO_ 1156 0;
BA_ "GenMsgCycleTime" BO_ 1156 1000;
BA_ "GenMsgSendType" BO_ 1157 0;
BA_ "GenMsgCycleTime" BO_ 1157 1000;
BA_ "GenMsgSendType" BO_ 1158 0;
BA_ "GenMsgCycleTime" BO_ 1158 1000;
BA_ "GenMsgSendType" BO_ 1159 0;
BA_ "GenMsgCycleTime" BO_ 1159 1000;
BA_ "GenMsgSendType" BO_ 1160 0;
BA_ "GenMsgCycleTime" BO_ 1160 1000;
BA_ "GenMsgSendType" BO_ 1161 0;
BA_ "GenMsgCycleTime" BO_ 1161 1000;
BA_ "GenMsgSendType" BO_ 1162 0;
BA_ "GenMsgCycleTime" BO_ 1162 1000;
BA_ "GenMsgSendType" BO_ 1163 0;
BA_ "GenMsgCycleTime" BO_ 1163 1000;
BA_ "GenMsgSendType" BO_ 805 0;
BA_ "GenMsgCycleTime" BO_ 805 135;
BA_ "GenMsgSendType" BO_ 579 0;
BA_ "GenMsgCycleTime" BO_ 579 100;
BA_ "GenMsgSendType" BO_ 1043 0;
BA_ "GenMsgCycleTime" BO_ 1043 500;
BA_ "GenMsgSendType" BO_ 1282 1;
BA_ "GenMsgDelayTime" BO_ 1282 20;
BA_ "GenMsgILSupport" BO_ 1282 0;
BA_ "NmAsrMessage" BO_ 1282 1;
BA_ "GenMsgSendType" BO_ 1346 1;
BA_ "GenMsgDelayTime" BO_ 1346 500;
BA_ "GenMsgSendType" BO_ 1553 1;
BA_ "GenMsgDelayTime" BO_ 1553 5;
BA_ "GenMsgSendType" BO_ 1409 1;
BA_ "GenMsgDelayTime" BO_ 1409 5;
BA_ "GenMsgSendType" BO_ 1410 1;
BA_ "GenMsgDelayTime" BO_ 1410 5;
BA_ "GenMsgSendType" BO_ 1411 1;
BA_ "GenMsgDelayTime" BO_ 1411 5;
BA_ "GenMsgSendType" BO_ 1412 1;
BA_ "GenMsgDelayTime" BO_ 1412 5;
BA_ "GenMsgSendType" BO_ 1434 0;
BA_ "GenMsgCycleTime" BO_ 1434 1000;
BA_ "GenMsgSendType" BO_ 32 0;
BA_ "GenMsgCycleTime" BO_ 32 10;
BA_ "GenMsgSendType" BO_ 64 0;
BA_ "GenMsgCycleTime" BO_ 64 15;
BA_ "GenMsgSendType" BO_ 118 0;
BA_ "GenMsgCycleTime" BO_ 118 20;
BA_ "GenMsgSendType" BO_ 1072 0;
BA_ "GenMsgCycleTime" BO_ 1072 140;
BA_ "GenSigSendType" SG_ 1435 DvlpFrameForCCMByte0 0;
BA_ "GenSigSendType" SG_ 1435 DvlpFrameForCCMByte1 0;
BA_ "GenSigSendType" SG_ 1435 DvlpFrameForCCMByte2 0;
BA_ "GenSigSendType" SG_ 1435 DvlpFrameForCCMByte3 0;
BA_ "GenSigSendType" SG_ 1435 DvlpFrameForCCMByte4 0;
BA_ "GenSigSendType" SG_ 1435 DvlpFrameForCCMByte5 0;
BA_ "GenSigSendType" SG_ 1435 DvlpFrameForCCMByte6 0;
BA_ "GenSigSendType" SG_ 1435 DvlpFrameForCCMByte7 0;
BA_ "GenSigSendType" SG_ 177 ClimaTiOfEnd 0;
BA_ "GenSigSendType" SG_ 177 EvaprTFrntEvaprTFrnt 0;
BA_ "GenSigStartValue" SG_ 177 EvaprTFrntEvaprTQf 1;
BA_ "GenSigSendType" SG_ 177 EvaprTFrntEvaprTQf 0;
BA_ "GenSigSendType" SG_ 177 HvacCoolgEnaFrnt 0;
BA_ "GenSigSendType" SG_ 177 HvacRecircAct 0;
BA_ "GenSigSendType" SG_ 177 IntPm25LvlFrmClima 0;
BA_ "GenSigSendType" SG_ 37 BtnIllmn6Ccm 0;
BA_ "GenSigSendType" SG_ 37 BtnIllmnForWinDefrstFrntCcm 0;
BA_ "GenSigSendType" SG_ 37 ClimaStsDisp 0;
BA_ "GenSigSendType" SG_ 37 HvacAirMFlowEstimd 0;
BA_ "GenSigSendType" SG_ 37 HvEgyDesForClima 0;
BA_ "GenSigSendType" SG_ 37 IntPm25VluFrmClima 0;
BA_ "GenSigSendType" SG_ 37 OutdPm25VluFrmClima 0;
BA_ "GenSigSendType" SG_ 37 PrkgClimaWarn 0;
BA_ "GenSigSendType" SG_ 512 ClimaActv 0;
BA_ "GenSigSendType" SG_ 512 ClimaPwrCns 0;
BA_ "GenSigSendType" SG_ 512 ClimaPwrCritDes 0;
BA_ "GenSigSendType" SG_ 512 ClimaPwrNormDes 0;
BA_ "GenSigSendType" SG_ 512 LvlOfClimaCmft 0;
BA_ "GenSigSendType" SG_ 512 RemClimaActv 0;
BA_ "GenSigSendType" SG_ 512 SteerWhlHeatgPwrAllwd 0;
BA_ "GenSigStartValue" SG_ 289 CmptmtAirTEstimdAtRowFirstLoResl 600;
BA_ "GenSigSendType" SG_ 289 CmptmtAirTEstimdAtRowFirstLoResl 0;
BA_ "SystemSignalLongSymbol" SG_ 289 CmptmtAirTEstimdAtRowFirstL_0000 "CmptmtAirTEstimdAtRowFirstLoResl_UB";
BA_ "GenSigStartValue" SG_ 289 CmptmtAirTEstimdExtdComptmtT 600;
BA_ "GenSigSendType" SG_ 289 CmptmtAirTEstimdExtdComptmtT 0;
BA_ "GenSigSendType" SG_ 289 CmptmtAirTEstimdExtdQlyFlg 0;
BA_ "GenSigStartValue" SG_ 289 CmptmtTFrntCmptmtTFrnt 600;
BA_ "GenSigSendType" SG_ 289 CmptmtTFrntCmptmtTFrnt 0;
BA_ "GenSigSendType" SG_ 289 CmptmtTFrntFanForCmptmtTRunng 0;
BA_ "GenSigStartValue" SG_ 289 CmptmtTFrntQf 1;
BA_ "GenSigSendType" SG_ 289 CmptmtTFrntQf 0;
BA_ "GenSigSendType" SG_ 289 EngRunngReqByClima 0;
BA_ "GenSigSendType" SG_ 289 EngSpdIncIdleForClima 0;
BA_ "GenSigSendType" SG_ 289 RlyCrashForClimaReq 0;
BA_ "GenSigSendType" SG_ 1029 AirTFbFromClimaAirTFbFromClima 0;
BA_ "GenSigSendType" SG_ 1029 AirTFbFromClimaDataQf 0;
BA_ "GenSigSendType" SG_ 1029 ClimaCmptSts 0;
BA_ "GenSigSendType" SG_ 1029 ClimaDefrstSts 0;
BA_ "GenSigSendType" SG_ 1029 ClimaOvrHeatProActv 0;
BA_ "GenSigSendType" SG_ 1029 CupHoldrActvAllwd 0;
BA_ "GenSigStartValue" SG_ 1029 HvacEvaprTSpFrnt 50;
BA_ "GenSigSendType" SG_ 1029 HvacEvaprTSpFrnt 0;
BA_ "GenSigStartValue" SG_ 1029 HvacEvaprTSpRe 50;
BA_ "GenSigSendType" SG_ 1029 HvacEvaprTSpRe 0;
BA_ "GenSigSendType" SG_ 1029 PwrEstimdAtStbForClima 0;
BA_ "GenSigSendType" SG_ 1033 HvacAirTForRowFirstAtFlrLeEvaprT 0;
BA_ "SystemSignalLongSymbol" SG_ 1033 HvacAirTForRowFirstAtFlrLeEvaprT "HvacAirTForRowFirstAtFlrLeEvaprTFrnt";
BA_ "GenSigStartValue" SG_ 1033 HvacAirTForRowFirstAtFlrLeE_0000 1;
BA_ "GenSigSendType" SG_ 1033 HvacAirTForRowFirstAtFlrLeE_0000 0;
BA_ "SystemSignalLongSymbol" SG_ 1033 HvacAirTForRowFirstAtFlrLeE_0000 "HvacAirTForRowFirstAtFlrLeEvaprTQf";
BA_ "GenSigSendType" SG_ 1033 HvacAirTForRowFirstAtFlrRiEvaprT 0;
BA_ "SystemSignalLongSymbol" SG_ 1033 HvacAirTForRowFirstAtFlrRiEvaprT "HvacAirTForRowFirstAtFlrRiEvaprTFrnt";
BA_ "GenSigStartValue" SG_ 1033 HvacAirTForRowFirstAtFlrRiE_0000 1;
BA_ "GenSigSendType" SG_ 1033 HvacAirTForRowFirstAtFlrRiE_0000 0;
BA_ "SystemSignalLongSymbol" SG_ 1033 HvacAirTForRowFirstAtFlrRiE_0000 "HvacAirTForRowFirstAtFlrRiEvaprTQf";
BA_ "GenSigSendType" SG_ 1033 HvacAirTForRowFirstAtVentLeEvapr 0;
BA_ "SystemSignalLongSymbol" SG_ 1033 HvacAirTForRowFirstAtVentLeEvapr "HvacAirTForRowFirstAtVentLeEvaprTFrnt";
BA_ "GenSigStartValue" SG_ 1033 HvacAirTForRowFirstAtVentLe_0000 1;
BA_ "GenSigSendType" SG_ 1033 HvacAirTForRowFirstAtVentLe_0000 0;
BA_ "SystemSignalLongSymbol" SG_ 1033 HvacAirTForRowFirstAtVentLe_0000 "HvacAirTForRowFirstAtVentLeEvaprTQf";
BA_ "GenSigSendType" SG_ 1033 HvacAirTForRowFirstAtVentRiEvapr 0;
BA_ "SystemSignalLongSymbol" SG_ 1033 HvacAirTForRowFirstAtVentRiEvapr "HvacAirTForRowFirstAtVentRiEvaprTFrnt";
BA_ "GenSigStartValue" SG_ 1033 HvacAirTForRowFirstAtVentRi_0000 1;
BA_ "GenSigSendType" SG_ 1033 HvacAirTForRowFirstAtVentRi_0000 0;
BA_ "SystemSignalLongSymbol" SG_ 1033 HvacAirTForRowFirstAtVentRi_0000 "HvacAirTForRowFirstAtVentRiEvaprTQf";
BA_ "GenSigSendType" SG_ 1034 HvacAirTForRowSecAtFlrLeEvaprTFr 0;
BA_ "SystemSignalLongSymbol" SG_ 1034 HvacAirTForRowSecAtFlrLeEvaprTFr "HvacAirTForRowSecAtFlrLeEvaprTFrnt";
BA_ "GenSigStartValue" SG_ 1034 HvacAirTForRowSecAtFlrLeEvaprTQf 1;
BA_ "GenSigSendType" SG_ 1034 HvacAirTForRowSecAtFlrLeEvaprTQf 0;
BA_ "GenSigSendType" SG_ 1034 HvacAirTForRowSecAtFlrRiEvaprTFr 0;
BA_ "SystemSignalLongSymbol" SG_ 1034 HvacAirTForRowSecAtFlrRiEvaprTFr "HvacAirTForRowSecAtFlrRiEvaprTFrnt";
BA_ "GenSigStartValue" SG_ 1034 HvacAirTForRowSecAtFlrRiEvaprTQf 1;
BA_ "GenSigSendType" SG_ 1034 HvacAirTForRowSecAtFlrRiEvaprTQf 0;
BA_ "GenSigSendType" SG_ 1034 HvacAirTForRowSecAtVentLeEvaprTF 0;
BA_ "SystemSignalLongSymbol" SG_ 1034 HvacAirTForRowSecAtVentLeEvaprTF "HvacAirTForRowSecAtVentLeEvaprTFrnt";
BA_ "GenSigStartValue" SG_ 1034 HvacAirTForRowSecAtVentLeEvaprTQ 1;
BA_ "GenSigSendType" SG_ 1034 HvacAirTForRowSecAtVentLeEvaprTQ 0;
BA_ "SystemSignalLongSymbol" SG_ 1034 HvacAirTForRowSecAtVentLeEvaprTQ "HvacAirTForRowSecAtVentLeEvaprTQf";
BA_ "GenSigSendType" SG_ 1034 HvacAirTForRowSecAtVentRiEvaprTF 0;
BA_ "SystemSignalLongSymbol" SG_ 1034 HvacAirTForRowSecAtVentRiEvaprTF "HvacAirTForRowSecAtVentRiEvaprTFrnt";
BA_ "GenSigStartValue" SG_ 1034 HvacAirTForRowSecAtVentRiEvaprTQ 1;
BA_ "GenSigSendType" SG_ 1034 HvacAirTForRowSecAtVentRiEvaprTQ 0;
BA_ "SystemSignalLongSymbol" SG_ 1034 HvacAirTForRowSecAtVentRiEvaprTQ "HvacAirTForRowSecAtVentRiEvaprTQf";
BA_ "GenSigSendType" SG_ 933 HvacFanSet2HvacFanSpd2 0;
BA_ "GenSigSendType" SG_ 1037 RemClimaWarn 1;
BA_ "GenSigSendType" SG_ 1037 ResrvdSigForECM1 0;
BA_ "GenSigSendType" SG_ 1037 ResrvdSigForECM2 0;
BA_ "GenSigSendType" SG_ 1037 ResrvdSigForECM3 0;
BA_ "GenSigSendType" SG_ 1037 ResrvdSigForECM4 0;
BA_ "GenSigSendType" SG_ 1037 WindIceDetdFrnt 0;
BA_ "GenSigSendType" SG_ 1037 WindIceDetdRe 0;
BA_ "GenSigStartValue" SG_ 1040 CmptModForHp 5;
BA_ "GenSigSendType" SG_ 1040 CmptModForHp 0;
BA_ "GenSigSendType" SG_ 1040 HpReqCritSts 0;
BA_ "GenSigSendType" SG_ 1040 HvacCondsorTEvaprTFrnt 0;
BA_ "GenSigStartValue" SG_ 1040 HvacCondsorTEvaprTQf 1;
BA_ "GenSigSendType" SG_ 1040 HvacCondsorTEvaprTQf 0;
BA_ "GenSigSendType" SG_ 1040 HvacCondsorTspEvaprTFrnt 0;
BA_ "GenSigStartValue" SG_ 1040 HvacCondsorTspEvaprTQf 1;
BA_ "GenSigSendType" SG_ 1040 HvacCondsorTspEvaprTQf 0;
BA_ "GenSigSendType" SG_ 1040 HvahBlwReq 0;
BA_ "GenSigSendType" SG_ 1040 HvahPwrReq 0;
BA_ "GenSigSendType" SG_ 1040 ReEvapVlvSts 0;
BA_ "GenSigSendType" SG_ 1040 RemClimaDelaySts 1;
BA_ "GenSigSendType" SG_ 1040 RemClimaExtnTiRspn 1;
BA_ "GenSigSendType" SG_ 1040 RemClimaHvRspn 1;
BA_ "GenSigSendType" SG_ 1040 RemClimaHvSts 0;
BA_ "GenSigStartValue" SG_ 1049 ClimaSts 1;
BA_ "GenSigSendType" SG_ 1049 ClimaSts 0;
BA_ "GenSigSendType" SG_ 1049 ElecDefrstReqMirrDefrstReq 0;
BA_ "GenSigSendType" SG_ 1049 ElecDefrstReqWinDefrstFrntReq 0;
BA_ "GenSigSendType" SG_ 1049 ElecDefrstReqWinDefrstReReq 0;
BA_ "GenSigSendType" SG_ 1049 FragCh1UseUpWrn 0;
BA_ "GenSigSendType" SG_ 1049 FragCh2UseUpWrn 0;
BA_ "GenSigSendType" SG_ 1049 FragCh3UseUpWrn 0;
BA_ "GenSigSendType" SG_ 1049 FragCh4UseUpWrn 0;
BA_ "GenSigSendType" SG_ 1049 FragCh5UseUpWrn 0;
BA_ "GenSigSendType" SG_ 1049 FragLvlFrmClima 0;
BA_ "GenSigStartValue" SG_ 1049 FragStsFrmClima 1;
BA_ "GenSigSendType" SG_ 1049 FragStsFrmClima 0;
BA_ "GenSigSendType" SG_ 1049 FrntHvacBlowerSts 0;
BA_ "GenSigStartValue" SG_ 1049 HeatrAirTReq 120;
BA_ "GenSigSendType" SG_ 1049 HeatrAirTReq 0;
BA_ "GenSigSendType" SG_ 1049 HvacCoolgEnaRe 0;
BA_ "GenSigSendType" SG_ 1049 HvacOsaAndRecActrQfForHp 0;
BA_ "GenSigStartValue" SG_ 1049 HvahAirTsp 600;
BA_ "GenSigSendType" SG_ 1049 HvahAirTsp 0;
BA_ "GenSigSendType" SG_ 1049 HvahHeatgReq 0;
BA_ "GenSigSendType" SG_ 1049 IntPm25StsFrmClima 0;
BA_ "GenSigSendType" SG_ 1049 OutdPm25LvlFrmClima 0;
BA_ "GenSigSendType" SG_ 1049 PostDrvgClimaAvl 0;
BA_ "GenSigSendType" SG_ 901 CcmElecAirDirCrtlReqPassRiPosY 0;
BA_ "SystemSignalLongSymbol" SG_ 901 CcmElecAirDirCrtlReqPassRiPosY_U "CcmElecAirDirCrtlReqPassRiPosY_UB";
BA_ "GenSigSendType" SG_ 901 CcmIntCo2Conc 0;
BA_ "GenSigSendType" SG_ 901 CcmIntCo2Lvl 0;
BA_ "GenSigSendType" SG_ 1145 CmptmtIntrMtrlTEstimdMtrlSnsrT 0;
BA_ "GenSigStartValue" SG_ 1145 CmptmtIntrMtrlTEstimdMtrlSnsrTQl 1;
BA_ "GenSigSendType" SG_ 1145 CmptmtIntrMtrlTEstimdMtrlSnsrTQl 0;
BA_ "SystemSignalLongSymbol" SG_ 1145 CmptmtIntrMtrlTEstimdMtrlSnsrTQl "CmptmtIntrMtrlTEstimdMtrlSnsrTQly2";
BA_ "GenSigSendType" SG_ 1145 EgyDesForClima 0;
BA_ "GenSigSendType" SG_ 1145 PwrAllwdForElecAirVentn 0;
BA_ "GenSigSendType" SG_ 1145 SunDataAzi 0;
BA_ "GenSigStartValue" SG_ 1145 SunDataElevn 900;
BA_ "GenSigSendType" SG_ 1145 SunDataElevn 0;
BA_ "GenSigStartValue" SG_ 1168 AmbTEstimdAmbTEstimd 700;
BA_ "GenSigSendType" SG_ 1168 AmbTEstimdAmbTEstimd 0;
BA_ "GenSigSendType" SG_ 1168 AmbTEstimdQf 0;
BA_ "GenSigSendType" SG_ 1168 CcmAirClngSts 0;
BA_ "GenSigSendType" SG_ 1168 DrvrSeatHeatgPwrAllwd 0;
BA_ "GenSigStartValue" SG_ 1168 PassSeatHeatgPwrAllwd 100;
BA_ "GenSigSendType" SG_ 1168 PassSeatHeatgPwrAllwd 0;
BA_ "GenSigSendType" SG_ 1168 SeatClimaDurgClimaHmiSeatHeatgFo 0;
BA_ "SystemSignalLongSymbol" SG_ 1168 SeatClimaDurgClimaHmiSeatHeatgFo "SeatClimaDurgClimaHmiSeatHeatgForRowFirstLe";
BA_ "GenSigSendType" SG_ 1168 SeatClimaDurgClimaHmiSeatHe_0000 0;
BA_ "SystemSignalLongSymbol" SG_ 1168 SeatClimaDurgClimaHmiSeatHe_0000 "SeatClimaDurgClimaHmiSeatHeatgForRowFirstRi";
BA_ "GenSigSendType" SG_ 1168 SeatClimaDurgClimaHmiSeatHe_0001 0;
BA_ "SystemSignalLongSymbol" SG_ 1168 SeatClimaDurgClimaHmiSeatHe_0001 "SeatClimaDurgClimaHmiSeatHeatgForRowSecLe";
BA_ "GenSigSendType" SG_ 1168 SeatClimaDurgClimaHmiSeatHe_0002 0;
BA_ "SystemSignalLongSymbol" SG_ 1168 SeatClimaDurgClimaHmiSeatHe_0002 "SeatClimaDurgClimaHmiSeatHeatgForRowSecRi";
BA_ "GenSigSendType" SG_ 1168 SeatClimaDurgClimaHmiSeatVentnFo 0;
BA_ "SystemSignalLongSymbol" SG_ 1168 SeatClimaDurgClimaHmiSeatVentnFo "SeatClimaDurgClimaHmiSeatVentnForRowFirstLe";
BA_ "GenSigSendType" SG_ 1168 SeatClimaDurgClimaHmiSeatVe_0000 0;
BA_ "SystemSignalLongSymbol" SG_ 1168 SeatClimaDurgClimaHmiSeatVe_0000 "SeatClimaDurgClimaHmiSeatVentnForRowFirstRi";
BA_ "GenSigSendType" SG_ 1168 SeatClimaDurgClimaHmiSeatVe_0001 0;
BA_ "SystemSignalLongSymbol" SG_ 1168 SeatClimaDurgClimaHmiSeatVe_0001 "SeatClimaDurgClimaHmiSeatVentnForRowSecLe";
BA_ "GenSigSendType" SG_ 1168 SeatClimaDurgClimaHmiSeatVe_0002 0;
BA_ "SystemSignalLongSymbol" SG_ 1168 SeatClimaDurgClimaHmiSeatVe_0002 "SeatClimaDurgClimaHmiSeatVentnForRowSecRi";
BA_ "GenSigStartValue" SG_ 1168 SecRowLeSeatHeatgPwrAllwd 100;
BA_ "GenSigSendType" SG_ 1168 SecRowLeSeatHeatgPwrAllwd 0;
BA_ "GenSigSendType" SG_ 1184 DefrstMaxSts 0;
BA_ "GenSigSendType" SG_ 1184 ElecAirVentnAvlSts 0;
BA_ "GenSigSendType" SG_ 1184 FragCh1Id 0;
BA_ "GenSigSendType" SG_ 1184 FragCh2Id 0;
BA_ "GenSigSendType" SG_ 1184 FragCh3Id 0;
BA_ "GenSigSendType" SG_ 1184 FragCh4Id 0;
BA_ "GenSigSendType" SG_ 1184 FragCh5Id 0;
BA_ "GenSigSendType" SG_ 1184 FragRefreshPopUp 1;
BA_ "GenSigSendType" SG_ 1184 IntPm25HiPopUp 0;
BA_ "GenSigSendType" SG_ 1184 OutdAirQlyOutdAirQly 0;
BA_ "GenSigSendType" SG_ 1184 OutdAirQlyQf 0;
BA_ "GenSigSendType" SG_ 1184 OutdPm25StsFrmClima 0;
BA_ "GenSigSendType" SG_ 1025 CcmRollgCntrSts 0;
BA_ "GenSigSendType" SG_ 1025 ClimaActvAlrmSts 0;
BA_ "GenSigSendType" SG_ 1025 HvacHeatElmAirMFlowEstimd 0;
BA_ "GenSigSendType" SG_ 1025 HvacHeatgReq 0;
BA_ "GenSigSendType" SG_ 1025 HvacHeatrInletTempReqEvaprTFrnt 0;
BA_ "GenSigSendType" SG_ 1025 HvacHeatrInletTempReqEvaprTQf 0;
BA_ "GenSigSendType" SG_ 1025 HvacHexAirTHvacAirTForHeatrFrnt 0;
BA_ "GenSigStartValue" SG_ 1025 HvacHexAirTHvacAirTForHeatrFrntQ 1;
BA_ "GenSigSendType" SG_ 1025 HvacHexAirTHvacAirTForHeatrFrntQ 0;
BA_ "SystemSignalLongSymbol" SG_ 1025 HvacHexAirTHvacAirTForHeatrFrntQ "HvacHexAirTHvacAirTForHeatrFrntQf";
BA_ "GenSigSendType" SG_ 295 AirFragCh1RunngSts 0;
BA_ "GenSigSendType" SG_ 295 AirFragCh2RunngSts 0;
BA_ "GenSigSendType" SG_ 295 AirFragCh3RunngSts 0;
BA_ "GenSigSendType" SG_ 295 AirFragCh4RunngSts 0;
BA_ "GenSigSendType" SG_ 295 AirFragCh5RunngSts 0;
BA_ "GenSigSendType" SG_ 295 DrvrSeatVentnPwrAllwd 0;
BA_ "GenSigSendType" SG_ 295 EcoClimaSts 0;
BA_ "GenSigSendType" SG_ 295 PassSeatVentnPwrAllwd 0;
BA_ "GenSigSendType" SG_ 295 SecRowLeSeatVentnPwrAllwd 0;
BA_ "GenSigSendType" SG_ 295 SecRowRiSeatHeatgPwrAllwd 0;
BA_ "GenSigSendType" SG_ 295 SecRowRiSeatVentnPwrAllwd 0;
BA_ "GenSigSendType" SG_ 295 SteerWhlHeatgDurgClima 0;
BA_ "GenSigSendType" SG_ 831 CarTiIntForClima 0;
BA_ "GenSigSendType" SG_ 831 ClimaCoolgReqLvl 0;
BA_ "GenSigSendType" SG_ 831 ClimaHeatgReqLvl 0;
BA_ "GenSigSendType" SG_ 831 ClimaOvrHeatPrtSts 0;
BA_ "GenSigSendType" SG_ 831 EvaprVlvReStsExtdDiagcStsForCirc 0;
BA_ "SystemSignalLongSymbol" SG_ 831 EvaprVlvReStsExtdDiagcStsForCirc "EvaprVlvReStsExtdDiagcStsForCircOpen";
BA_ "GenSigSendType" SG_ 831 EvaprVlvReStsExtdDiagcStsForShoT 0;
BA_ "SystemSignalLongSymbol" SG_ 831 EvaprVlvReStsExtdDiagcStsForShoT "EvaprVlvReStsExtdDiagcStsForShoToBatt";
BA_ "GenSigSendType" SG_ 831 EvaprVlvReStsExtdDiagcStsFo_0000 0;
BA_ "SystemSignalLongSymbol" SG_ 831 EvaprVlvReStsExtdDiagcStsFo_0000 "EvaprVlvReStsExtdDiagcStsForShoToGnd";
BA_ "GenSigSendType" SG_ 831 ReHvacBlowerSts 0;
BA_ "GenSigSendType" SG_ 831 RlyCmftForClimaReq 0;
BA_ "GenSigSendType" SG_ 831 UBoostReqByClima 0;
BA_ "GenSigSendType" SG_ 851 CcmIntelliClimaResd1 0;
BA_ "GenSigSendType" SG_ 851 CcmIntelliClimaResd10 0;
BA_ "GenSigSendType" SG_ 851 CcmIntelliClimaResd11 0;
BA_ "GenSigSendType" SG_ 856 CcmIntelliClimaResd12 0;
BA_ "GenSigSendType" SG_ 856 CcmIntelliClimaResd2 0;
BA_ "GenSigSendType" SG_ 856 CcmIntelliClimaResd6 0;
BA_ "GenSigSendType" SG_ 860 CcmIntelliClimaResd13 0;
BA_ "GenSigSendType" SG_ 860 CcmIntelliClimaResd3 0;
BA_ "GenSigSendType" SG_ 860 CcmIntelliClimaResd7 0;
BA_ "GenSigSendType" SG_ 865 CcmIntelliClimaResd14 0;
BA_ "GenSigSendType" SG_ 865 CcmIntelliClimaResd4 0;
BA_ "GenSigSendType" SG_ 865 CcmIntelliClimaResd8 0;
BA_ "GenSigSendType" SG_ 868 CcmIntelliClimaResd15 0;
BA_ "GenSigSendType" SG_ 868 CcmIntelliClimaResd5 0;
BA_ "GenSigSendType" SG_ 868 CcmIntelliClimaResd9 0;
BA_ "GenSigSendType" SG_ 596 ElecVentnMotPwrCnsAct 0;
BA_ "GenSigSendType" SG_ 596 ElecVentnMotPwrCnsDes 0;
BA_ "GenSigSendType" SG_ 596 HvacDefrstFlapActlPosn 0;
BA_ "GenSigSendType" SG_ 596 HvacModFlapActlPosnFrstRowLe 0;
BA_ "GenSigSendType" SG_ 596 HvacModFlapActlPosnFrstRowRi 0;
BA_ "GenSigSendType" SG_ 600 HvacModFlapActlPosnSecRowLe 0;
BA_ "GenSigSendType" SG_ 600 HvacModFlapActlPosnSecRowRi 0;
BA_ "GenSigSendType" SG_ 600 HvacOsaFlapActlPosn 0;
BA_ "GenSigSendType" SG_ 600 HvacRecFlapActlPosn 0;
BA_ "GenSigSendType" SG_ 604 HvacAirMFlowReEstimd 0;
BA_ "GenSigSendType" SG_ 604 HvacTempFlapActlPosnFrstRowLe 0;
BA_ "GenSigSendType" SG_ 604 HvacTempFlapActlPosnFrstRowRi 0;
BA_ "GenSigSendType" SG_ 604 HvacTempFlapActlPosnSecRowLe 0;
BA_ "GenSigSendType" SG_ 604 HvacTempFlapActlPosnSecRowRi 0;
BA_ "GenSigSendType" SG_ 604 InCarCo2HighWarn 0;
BA_ "GenSigStartValue" SG_ 607 TgtHvacAirTForRowFirstLe 250;
BA_ "GenSigSendType" SG_ 607 TgtHvacAirTForRowFirstLe 0;
BA_ "GenSigStartValue" SG_ 607 TgtHvacAirTForRowFirstRi 250;
BA_ "GenSigSendType" SG_ 607 TgtHvacAirTForRowFirstRi 0;
BA_ "GenSigStartValue" SG_ 607 TgtHvacAirTForRowSecLe 250;
BA_ "GenSigSendType" SG_ 607 TgtHvacAirTForRowSecLe 0;
BA_ "GenSigStartValue" SG_ 607 TgtHvacAirTForRowSecRi 250;
BA_ "GenSigSendType" SG_ 607 TgtHvacAirTForRowSecRi 0;
BA_ "GenSigSendType" SG_ 593 AutoDefrstReqPopUp 1;
BA_ "GenSigSendType" SG_ 593 AutoDeHumPopUp 1;
BA_ "GenSigSendType" SG_ 593 ClimaOffReq 1;
BA_ "GenSigSendType" SG_ 593 ClimaOnReq 1;
BA_ "GenSigSendType" SG_ 593 ClimaOvrHeatProRspn 1;
BA_ "GenSigSendType" SG_ 593 ClimaOvrHeatProWarn 1;
BA_ "GenSigSendType" SG_ 593 Co2WarnForTelm 1;
BA_ "GenSigSendType" SG_ 593 DiDblLock 1;
BA_ "GenSigSendType" SG_ 593 RemStrtClimaRspn 1;
BA_ "GenSigSendType" SG_ 593 RoofOpnReqFrmClima 1;
BA_ "GenSigSendType" SG_ 593 SunRoofOpnPopUpForHmi 1;
BA_ "GenSigSendType" SG_ 593 WinAndRoofReqFrmClima 1;
BA_ "GenSigSendType" SG_ 593 WinRfClsdReqForCoolgDwn 1;
BA_ "GenSigSendType" SG_ 1152 CcmCaliSig1Byte0 0;
BA_ "GenSigSendType" SG_ 1152 CcmCaliSig1Byte1 0;
BA_ "GenSigSendType" SG_ 1152 CcmCaliSig1Byte2 0;
BA_ "GenSigSendType" SG_ 1152 CcmCaliSig1Byte3 0;
BA_ "GenSigSendType" SG_ 1152 CcmCaliSig1Byte4 0;
BA_ "GenSigSendType" SG_ 1152 CcmCaliSig1Byte5 0;
BA_ "GenSigSendType" SG_ 1152 CcmCaliSig1Byte6 0;
BA_ "GenSigSendType" SG_ 1152 CcmCaliSig1Byte7 0;
BA_ "GenSigSendType" SG_ 1153 CcmCaliSig2Byte0 0;
BA_ "GenSigSendType" SG_ 1153 CcmCaliSig2Byte1 0;
BA_ "GenSigSendType" SG_ 1153 CcmCaliSig2Byte2 0;
BA_ "GenSigSendType" SG_ 1153 CcmCaliSig2Byte3 0;
BA_ "GenSigSendType" SG_ 1153 CcmCaliSig2Byte4 0;
BA_ "GenSigSendType" SG_ 1153 CcmCaliSig2Byte5 0;
BA_ "GenSigSendType" SG_ 1153 CcmCaliSig2Byte6 0;
BA_ "GenSigSendType" SG_ 1153 CcmCaliSig2Byte7 0;
BA_ "GenSigSendType" SG_ 1154 CcmCaliSig3Byte0 0;
BA_ "GenSigSendType" SG_ 1154 CcmCaliSig3Byte1 0;
BA_ "GenSigSendType" SG_ 1154 CcmCaliSig3Byte2 0;
BA_ "GenSigSendType" SG_ 1154 CcmCaliSig3Byte3 0;
BA_ "GenSigSendType" SG_ 1154 CcmCaliSig3Byte4 0;
BA_ "GenSigSendType" SG_ 1154 CcmCaliSig3Byte5 0;
BA_ "GenSigSendType" SG_ 1154 CcmCaliSig3Byte6 0;
BA_ "GenSigSendType" SG_ 1154 CcmCaliSig3Byte7 0;
BA_ "GenSigSendType" SG_ 1155 CcmCaliSig4Byte0 0;
BA_ "GenSigSendType" SG_ 1155 CcmCaliSig4Byte1 0;
BA_ "GenSigSendType" SG_ 1155 CcmCaliSig4Byte2 0;
BA_ "GenSigSendType" SG_ 1155 CcmCaliSig4Byte3 0;
BA_ "GenSigSendType" SG_ 1155 CcmCaliSig4Byte4 0;
BA_ "GenSigSendType" SG_ 1155 CcmCaliSig4Byte5 0;
BA_ "GenSigSendType" SG_ 1155 CcmCaliSig4Byte6 0;
BA_ "GenSigSendType" SG_ 1155 CcmCaliSig4Byte7 0;
BA_ "GenSigSendType" SG_ 1156 CcmCaliSig5Byte0 0;
BA_ "GenSigSendType" SG_ 1156 CcmCaliSig5Byte1 0;
BA_ "GenSigSendType" SG_ 1156 CcmCaliSig5Byte2 0;
BA_ "GenSigSendType" SG_ 1156 CcmCaliSig5Byte3 0;
BA_ "GenSigSendType" SG_ 1156 CcmCaliSig5Byte4 0;
BA_ "GenSigSendType" SG_ 1156 CcmCaliSig5Byte5 0;
BA_ "GenSigSendType" SG_ 1156 CcmCaliSig5Byte6 0;
BA_ "GenSigSendType" SG_ 1156 CcmCaliSig5Byte7 0;
BA_ "GenSigSendType" SG_ 1157 CcmCaliSig6Byte0 0;
BA_ "GenSigSendType" SG_ 1157 CcmCaliSig6Byte1 0;
BA_ "GenSigSendType" SG_ 1157 CcmCaliSig6Byte2 0;
BA_ "GenSigSendType" SG_ 1157 CcmCaliSig6Byte3 0;
BA_ "GenSigSendType" SG_ 1157 CcmCaliSig6Byte4 0;
BA_ "GenSigSendType" SG_ 1157 CcmCaliSig6Byte5 0;
BA_ "GenSigSendType" SG_ 1157 CcmCaliSig6Byte6 0;
BA_ "GenSigSendType" SG_ 1157 CcmCaliSig6Byte7 0;
BA_ "GenSigSendType" SG_ 1158 CcmCaliSig7Byte0 0;
BA_ "GenSigSendType" SG_ 1158 CcmCaliSig7Byte1 0;
BA_ "GenSigSendType" SG_ 1158 CcmCaliSig7Byte2 0;
BA_ "GenSigSendType" SG_ 1158 CcmCaliSig7Byte3 0;
BA_ "GenSigSendType" SG_ 1158 CcmCaliSig7Byte4 0;
BA_ "GenSigSendType" SG_ 1158 CcmCaliSig7Byte5 0;
BA_ "GenSigSendType" SG_ 1158 CcmCaliSig7Byte6 0;
BA_ "GenSigSendType" SG_ 1158 CcmCaliSig7Byte7 0;
BA_ "GenSigSendType" SG_ 1159 CcmCaliSig8Byte0 0;
BA_ "GenSigSendType" SG_ 1159 CcmCaliSig8Byte1 0;
BA_ "GenSigSendType" SG_ 1159 CcmCaliSig8Byte2 0;
BA_ "GenSigSendType" SG_ 1159 CcmCaliSig8Byte3 0;
BA_ "GenSigSendType" SG_ 1159 CcmCaliSig8Byte4 0;
BA_ "GenSigSendType" SG_ 1159 CcmCaliSig8Byte5 0;
BA_ "GenSigSendType" SG_ 1159 CcmCaliSig8Byte6 0;
BA_ "GenSigSendType" SG_ 1159 CcmCaliSig8Byte7 0;
BA_ "GenSigSendType" SG_ 1160 CcmCaliSig9Byte0 0;
BA_ "GenSigSendType" SG_ 1160 CcmCaliSig9Byte1 0;
BA_ "GenSigSendType" SG_ 1160 CcmCaliSig9Byte2 0;
BA_ "GenSigSendType" SG_ 1160 CcmCaliSig9Byte3 0;
BA_ "GenSigSendType" SG_ 1160 CcmCaliSig9Byte4 0;
BA_ "GenSigSendType" SG_ 1160 CcmCaliSig9Byte5 0;
BA_ "GenSigSendType" SG_ 1160 CcmCaliSig9Byte6 0;
BA_ "GenSigSendType" SG_ 1160 CcmCaliSig9Byte7 0;
BA_ "GenSigSendType" SG_ 1161 CcmCaliSig10Byte0 0;
BA_ "GenSigSendType" SG_ 1161 CcmCaliSig10Byte1 0;
BA_ "GenSigSendType" SG_ 1161 CcmCaliSig10Byte2 0;
BA_ "GenSigSendType" SG_ 1161 CcmCaliSig10Byte3 0;
BA_ "GenSigSendType" SG_ 1161 CcmCaliSig10Byte4 0;
BA_ "GenSigSendType" SG_ 1161 CcmCaliSig10Byte5 0;
BA_ "GenSigSendType" SG_ 1161 CcmCaliSig10Byte6 0;
BA_ "GenSigSendType" SG_ 1161 CcmCaliSig10Byte7 0;
BA_ "GenSigSendType" SG_ 1162 CcmCaliSig11Byte0 0;
BA_ "GenSigSendType" SG_ 1162 CcmCaliSig11Byte1 0;
BA_ "GenSigSendType" SG_ 1162 CcmCaliSig11Byte2 0;
BA_ "GenSigSendType" SG_ 1162 CcmCaliSig11Byte3 0;
BA_ "GenSigSendType" SG_ 1162 CcmCaliSig11Byte4 0;
BA_ "GenSigSendType" SG_ 1162 CcmCaliSig11Byte5 0;
BA_ "GenSigSendType" SG_ 1162 CcmCaliSig11Byte6 0;
BA_ "GenSigSendType" SG_ 1162 CcmCaliSig11Byte7 0;
BA_ "GenSigSendType" SG_ 1163 CcmCaliSig12Byte0 0;
BA_ "GenSigSendType" SG_ 1163 CcmCaliSig12Byte1 0;
BA_ "GenSigSendType" SG_ 1163 CcmCaliSig12Byte2 0;
BA_ "GenSigSendType" SG_ 1163 CcmCaliSig12Byte3 0;
BA_ "GenSigSendType" SG_ 1163 CcmCaliSig12Byte4 0;
BA_ "GenSigSendType" SG_ 1163 CcmCaliSig12Byte5 0;
BA_ "GenSigSendType" SG_ 1163 CcmCaliSig12Byte6 0;
BA_ "GenSigSendType" SG_ 1163 CcmCaliSig12Byte7 0;
BA_ "GenSigStartValue" SG_ 805 CmptmtTReCmptmtTFrnt 600;
BA_ "GenSigSendType" SG_ 805 CmptmtTReCmptmtTFrnt 0;
BA_ "GenSigStartValue" SG_ 805 CmptmtTReCmptmtTFrntQf 1;
BA_ "GenSigSendType" SG_ 805 CmptmtTReCmptmtTFrntQf 0;
BA_ "GenSigSendType" SG_ 805 CmptmtTReFanForCmptmtTRunng 0;
BA_ "GenSigSendType" SG_ 805 EvaprTReEvaprTFrnt 0;
BA_ "GenSigStartValue" SG_ 805 EvaprTReEvaprTQf 1;
BA_ "GenSigSendType" SG_ 805 EvaprTReEvaprTQf 0;
BA_ "GenSigSendType" SG_ 579 CdsParkgClimaActv 0;
BA_ "GenSigSendType" SG_ 579 ClimaOvrHeatProActvSts 0;
BA_ "GenSigSendType" SG_ 579 RemVentActvSts 0;
BA_ "GenSigSendType" SG_ 579 RemVentReqRspnFb 0;
BA_ "GenSigSendType" SG_ 579 RemVentWarnSts 0;
BA_ "GenSigSendType" SG_ 1043 CcmElecAirDirCrtlReqDrvrLePosX 0;
BA_ "SystemSignalLongSymbol" SG_ 1043 CcmElecAirDirCrtlReqDrvrLePosX_U "CcmElecAirDirCrtlReqDrvrLePosX_UB";
BA_ "GenSigSendType" SG_ 1043 CcmElecAirDirCrtlReqDrvrLePosY 0;
BA_ "SystemSignalLongSymbol" SG_ 1043 CcmElecAirDirCrtlReqDrvrLePosY_U "CcmElecAirDirCrtlReqDrvrLePosY_UB";
BA_ "GenSigSendType" SG_ 1043 CcmElecAirDirCrtlReqDrvrRiPosX 0;
BA_ "SystemSignalLongSymbol" SG_ 1043 CcmElecAirDirCrtlReqDrvrRiPosX_U "CcmElecAirDirCrtlReqDrvrRiPosX_UB";
BA_ "GenSigSendType" SG_ 1043 CcmElecAirDirCrtlReqDrvrRiPosY 0;
BA_ "SystemSignalLongSymbol" SG_ 1043 CcmElecAirDirCrtlReqDrvrRiPosY_U "CcmElecAirDirCrtlReqDrvrRiPosY_UB";
BA_ "GenSigSendType" SG_ 1043 CcmElecAirDirCrtlReqPassLePosX 0;
BA_ "SystemSignalLongSymbol" SG_ 1043 CcmElecAirDirCrtlReqPassLePosX_U "CcmElecAirDirCrtlReqPassLePosX_UB";
BA_ "GenSigSendType" SG_ 1043 CcmElecAirDirCrtlReqPassLePosY 0;
BA_ "SystemSignalLongSymbol" SG_ 1043 CcmElecAirDirCrtlReqPassLePosY_U "CcmElecAirDirCrtlReqPassLePosY_UB";
BA_ "GenSigSendType" SG_ 1043 CcmElecAirDirCrtlReqPassRiPosX 0;
BA_ "SystemSignalLongSymbol" SG_ 1043 CcmElecAirDirCrtlReqPassRiPosX_U "CcmElecAirDirCrtlReqPassRiPosX_UB";
BA_ "GenSigSendType" SG_ 1346 VFCVectorCCMBlockID 1;
BA_ "GenSigSendType" SG_ 1346 VFCVectorCCMVFCid0 1;
BA_ "GenSigSendType" SG_ 1346 VFCVectorCCMVFCid1 1;
BA_ "GenSigSendType" SG_ 1346 VFCVectorCCMVFCid10 1;
BA_ "GenSigSendType" SG_ 1346 VFCVectorCCMVFCid11 1;
BA_ "GenSigSendType" SG_ 1346 VFCVectorCCMVFCid12 1;
BA_ "GenSigSendType" SG_ 1346 VFCVectorCCMVFCid13 1;
BA_ "GenSigSendType" SG_ 1346 VFCVectorCCMVFCid14 1;
BA_ "GenSigSendType" SG_ 1346 VFCVectorCCMVFCid15 1;
BA_ "GenSigSendType" SG_ 1346 VFCVectorCCMVFCid16 1;
BA_ "GenSigSendType" SG_ 1346 VFCVectorCCMVFCid17 1;
BA_ "GenSigSendType" SG_ 1346 VFCVectorCCMVFCid18 1;
BA_ "GenSigSendType" SG_ 1346 VFCVectorCCMVFCid19 1;
BA_ "GenSigSendType" SG_ 1346 VFCVectorCCMVFCid2 1;
BA_ "GenSigSendType" SG_ 1346 VFCVectorCCMVFCid20 1;
BA_ "GenSigSendType" SG_ 1346 VFCVectorCCMVFCid21 1;
BA_ "GenSigSendType" SG_ 1346 VFCVectorCCMVFCid22 1;
BA_ "GenSigSendType" SG_ 1346 VFCVectorCCMVFCid23 1;
BA_ "GenSigSendType" SG_ 1346 VFCVectorCCMVFCid24 1;
BA_ "GenSigSendType" SG_ 1346 VFCVectorCCMVFCid25 1;
BA_ "GenSigSendType" SG_ 1346 VFCVectorCCMVFCid26 1;
BA_ "GenSigSendType" SG_ 1346 VFCVectorCCMVFCid27 1;
BA_ "GenSigSendType" SG_ 1346 VFCVectorCCMVFCid28 1;
BA_ "GenSigSendType" SG_ 1346 VFCVectorCCMVFCid29 1;
BA_ "GenSigSendType" SG_ 1346 VFCVectorCCMVFCid3 1;
BA_ "GenSigSendType" SG_ 1346 VFCVectorCCMVFCid30 1;
BA_ "GenSigSendType" SG_ 1346 VFCVectorCCMVFCid31 1;
BA_ "GenSigSendType" SG_ 1346 VFCVectorCCMVFCid32 1;
BA_ "GenSigSendType" SG_ 1346 VFCVectorCCMVFCid33 1;
BA_ "GenSigSendType" SG_ 1346 VFCVectorCCMVFCid34 1;
BA_ "GenSigSendType" SG_ 1346 VFCVectorCCMVFCid35 1;
BA_ "GenSigSendType" SG_ 1346 VFCVectorCCMVFCid36 1;
BA_ "GenSigSendType" SG_ 1346 VFCVectorCCMVFCid37 1;
BA_ "GenSigSendType" SG_ 1346 VFCVectorCCMVFCid38 1;
BA_ "GenSigSendType" SG_ 1346 VFCVectorCCMVFCid39 1;
BA_ "GenSigSendType" SG_ 1346 VFCVectorCCMVFCid4 1;
BA_ "GenSigSendType" SG_ 1346 VFCVectorCCMVFCid40 1;
BA_ "GenSigSendType" SG_ 1346 VFCVectorCCMVFCid41 1;
BA_ "GenSigSendType" SG_ 1346 VFCVectorCCMVFCid42 1;
BA_ "GenSigSendType" SG_ 1346 VFCVectorCCMVFCid43 1;
BA_ "GenSigSendType" SG_ 1346 VFCVectorCCMVFCid44 1;
BA_ "GenSigSendType" SG_ 1346 VFCVectorCCMVFCid45 1;
BA_ "GenSigSendType" SG_ 1346 VFCVectorCCMVFCid46 1;
BA_ "GenSigSendType" SG_ 1346 VFCVectorCCMVFCid47 1;
BA_ "GenSigSendType" SG_ 1346 VFCVectorCCMVFCid48 1;
BA_ "GenSigSendType" SG_ 1346 VFCVectorCCMVFCid49 1;
BA_ "GenSigSendType" SG_ 1346 VFCVectorCCMVFCid5 1;
BA_ "GenSigSendType" SG_ 1346 VFCVectorCCMVFCid50 1;
BA_ "GenSigSendType" SG_ 1346 VFCVectorCCMVFCid51 1;
BA_ "GenSigSendType" SG_ 1346 VFCVectorCCMVFCid52 1;
BA_ "GenSigSendType" SG_ 1346 VFCVectorCCMVFCid53 1;
BA_ "GenSigSendType" SG_ 1346 VFCVectorCCMVFCid54 1;
BA_ "GenSigSendType" SG_ 1346 VFCVectorCCMVFCid55 1;
BA_ "GenSigSendType" SG_ 1346 VFCVectorCCMVFCid56 1;
BA_ "GenSigSendType" SG_ 1346 VFCVectorCCMVFCid57 1;
BA_ "GenSigSendType" SG_ 1346 VFCVectorCCMVFCid58 1;
BA_ "GenSigSendType" SG_ 1346 VFCVectorCCMVFCid59 1;
BA_ "GenSigSendType" SG_ 1346 VFCVectorCCMVFCid6 1;
BA_ "GenSigSendType" SG_ 1346 VFCVectorCCMVFCid60 1;
BA_ "GenSigSendType" SG_ 1346 VFCVectorCCMVFCid61 1;
BA_ "GenSigSendType" SG_ 1346 VFCVectorCCMVFCid7 1;
BA_ "GenSigSendType" SG_ 1346 VFCVectorCCMVFCid8 1;
BA_ "GenSigSendType" SG_ 1346 VFCVectorCCMVFCid9 1;
BA_ "GenSigSendType" SG_ 1434 DiagFrameForECMByte0 0;
BA_ "GenSigSendType" SG_ 1434 DiagFrameForECMByte1 0;
BA_ "GenSigSendType" SG_ 1434 DiagFrameForECMByte2 0;
BA_ "GenSigSendType" SG_ 1434 DiagFrameForECMByte3 0;
BA_ "GenSigSendType" SG_ 1434 DiagFrameForECMByte4 0;
BA_ "GenSigSendType" SG_ 1434 DiagFrameForECMByte5 0;
BA_ "GenSigSendType" SG_ 1434 DiagFrameForECMByte6 0;
BA_ "GenSigSendType" SG_ 1434 DiagFrameForECMByte7 0;
BA_ "GenSigSendType" SG_ 32 DoorDrvrLockCmd 0;
BA_ "GenSigSendType" SG_ 32 DoorDrvrRelsReq 0;
BA_ "GenSigSendType" SG_ 32 DoorLeReLockCmd 0;
BA_ "GenSigSendType" SG_ 32 DoorLeReRelsReq 0;
BA_ "GenSigSendType" SG_ 32 DoorPassLockCmd 0;
BA_ "GenSigSendType" SG_ 32 DoorPassRelsReq 0;
BA_ "GenSigSendType" SG_ 32 DoorRiReLockCmd 0;
BA_ "GenSigSendType" SG_ 32 DoorRiReRelsReq 0;
BA_ "GenSigSendType" SG_ 32 HmiSeatClimaHmiSeatHeatgForRowFi 0;
BA_ "SystemSignalLongSymbol" SG_ 32 HmiSeatClimaHmiSeatHeatgForRowFi "HmiSeatClimaHmiSeatHeatgForRowFirstLe";
BA_ "GenSigSendType" SG_ 32 HmiSeatClimaHmiSeatHeatgFor_0000 0;
BA_ "SystemSignalLongSymbol" SG_ 32 HmiSeatClimaHmiSeatHeatgFor_0000 "HmiSeatClimaHmiSeatHeatgForRowFirstRi";
BA_ "GenSigSendType" SG_ 32 HmiSeatClimaHmiSeatHeatgForRowSe 0;
BA_ "SystemSignalLongSymbol" SG_ 32 HmiSeatClimaHmiSeatHeatgForRowSe "HmiSeatClimaHmiSeatHeatgForRowSecLe";
BA_ "GenSigSendType" SG_ 32 HmiSeatClimaHmiSeatHeatgFor_0001 0;
BA_ "SystemSignalLongSymbol" SG_ 32 HmiSeatClimaHmiSeatHeatgFor_0001 "HmiSeatClimaHmiSeatHeatgForRowSecRi";
BA_ "GenSigSendType" SG_ 32 HmiSeatClimaHmiSeatVentnForRowFi 0;
BA_ "SystemSignalLongSymbol" SG_ 32 HmiSeatClimaHmiSeatVentnForRowFi "HmiSeatClimaHmiSeatVentnForRowFirstLe";
BA_ "GenSigSendType" SG_ 32 HmiSeatClimaHmiSeatVentnFor_0000 0;
BA_ "SystemSignalLongSymbol" SG_ 32 HmiSeatClimaHmiSeatVentnFor_0000 "HmiSeatClimaHmiSeatVentnForRowFirstRi";
BA_ "GenSigSendType" SG_ 32 HmiSeatClimaHmiSeatVentnForRowSe 0;
BA_ "SystemSignalLongSymbol" SG_ 32 HmiSeatClimaHmiSeatVentnForRowSe "HmiSeatClimaHmiSeatVentnForRowSecLe";
BA_ "GenSigSendType" SG_ 32 HmiSeatClimaHmiSeatVentnFor_0001 0;
BA_ "SystemSignalLongSymbol" SG_ 32 HmiSeatClimaHmiSeatVentnFor_0001 "HmiSeatClimaHmiSeatVentnForRowSecRi";
BA_ "GenSigSendType" SG_ 32 IndcrSts 0;
BA_ "GenSigSendType" SG_ 32 TrlrLiBrkActvt 0;
BA_ "GenSigSendType" SG_ 32 TrlrLiTurnIndcrActvt 0;
BA_ "GenSigSendType" SG_ 64 DoorDrvrIntrSwtLedLockgCmd 0;
BA_ "GenSigSendType" SG_ 64 DoorDrvrSts 0;
BA_ "GenSigSendType" SG_ 64 DoorLeReSts 0;
BA_ "GenSigSendType" SG_ 64 DoorPassIntrSwtLedLockgCmd 0;
BA_ "GenSigSendType" SG_ 64 IHUAPSts 0;
BA_ "GenSigSendType" SG_ 64 LcmaIndcnLe 0;
BA_ "GenSigSendType" SG_ 64 LcmaIndcnRi 0;
BA_ "GenSigSendType" SG_ 64 PassLoadAndStoreReqErgoPosn 0;
BA_ "GenSigSendType" SG_ 64 PassLoadAndStoreReqErgoSetgEve 0;
BA_ "GenSigSendType" SG_ 64 SaveSetgToMemPrmnt 0;
BA_ "GenSigSendType" SG_ 64 TrNoKeyPrsntAcoustReq 0;
BA_ "GenSigSendType" SG_ 64 TrOpenerReqTrigSrc 0;
BA_ "GenSigSendType" SG_ 64 TrOpenerReqTrOpenerReq 0;
BA_ "GenSigSendType" SG_ 64 TwliBriSts 0;
BA_ "GenSigSendType" SG_ 64 VehMtnStChks 0;
BA_ "GenSigFuncType" SG_ 64 VehMtnStChks 15;
BA_ "GenSigDataID" SG_ 64 VehMtnStChks "0x36";
BA_ "GenSigSendType" SG_ 64 VehMtnStCntr 0;
BA_ "GenSigFuncType" SG_ 64 VehMtnStCntr 16;
BA_ "GenSigSendType" SG_ 64 VehMtnStVehMtnSt 0;
BA_ "GenSigSendType" SG_ 64 WinGlbCmd 0;
BA_ "GenSigSendType" SG_ 118 ActvnOfIndcrIndcrOut 0;
BA_ "GenSigSendType" SG_ 118 ActvnOfIndcrIndcrOutChks 0;
BA_ "GenSigFuncType" SG_ 118 ActvnOfIndcrIndcrOutChks 15;
BA_ "GenSigDataID" SG_ 118 ActvnOfIndcrIndcrOutChks "0x9E";
BA_ "GenSigSendType" SG_ 118 ActvnOfIndcrIndcrOutCntr 0;
BA_ "GenSigFuncType" SG_ 118 ActvnOfIndcrIndcrOutCntr 16;
BA_ "GenSigSendType" SG_ 118 DoorSldngLeReRelsReq 0;
BA_ "GenSigSendType" SG_ 118 DoorSldngRiReRelsReq 0;
BA_ "GenSigSendType" SG_ 118 RadioFrqAM 0;
BA_ "GenSigSendType" SG_ 118 VehSpdLgtA 0;
BA_ "GenSigSendType" SG_ 118 VehSpdLgtChks 0;
BA_ "GenSigFuncType" SG_ 118 VehSpdLgtChks 15;
BA_ "GenSigDataID" SG_ 118 VehSpdLgtChks "0x37";
BA_ "GenSigSendType" SG_ 118 VehSpdLgtCntr 0;
BA_ "GenSigFuncType" SG_ 118 VehSpdLgtCntr 16;
BA_ "GenSigStartValue" SG_ 118 VehSpdLgtQf 1;
BA_ "GenSigSendType" SG_ 118 VehSpdLgtQf 0;
BA_ "GenSigSendType" SG_ 1072 ClimRlyCmd 0;
BA_ "GenSigStartValue" SG_ 1072 LeSolarData 50.8;
BA_ "GenSigSendType" SG_ 1072 LeSolarData 0;
BA_ "GenSigStartValue" SG_ 1072 RiSolarData 50.8;
BA_ "GenSigSendType" SG_ 1072 RiSolarData 0;
BA_ "GenSigSendType" SG_ 1072 RlyCmdCmft 0;
BA_ "GenSigStartValue" SG_ 1072 SolarSnsrVluQf 1;
BA_ "GenSigSendType" SG_ 1072 SolarSnsrVluQf 0;
VAL_ 177 EvaprTFrntEvaprTQf 0 "HvacTIfQf_SnsrDataNotOk" 1 "HvacTIfQf_SnsrDataOk" ;
VAL_ 177 HvacCoolgEnaFrnt 0 "OnOff1_Off" 1 "OnOff1_On" ;
VAL_ 177 IntPm25LvlFrmClima 0 "CmpmtAirPmLvl_Level1" 1 "CmpmtAirPmLvl_Level2" 2 "CmpmtAirPmLvl_Level3" 3 "CmpmtAirPmLvl_Level4" 4 "CmpmtAirPmLvl_Level5" 5 "CmpmtAirPmLvl_Level6" 6 "CmpmtAirPmLvl_Reserved" 7 "CmpmtAirPmLvl_Invalid" ;
VAL_ 37 BtnIllmn6Ccm 0 "OnOff1_Off" 1 "OnOff1_On" ;
VAL_ 37 BtnIllmnForWinDefrstFrntCcm 0 "OnOff1_Off" 1 "OnOff1_On" ;
VAL_ 37 ClimaStsDisp 0 "Err1_NoErr" 1 "Err1_Err" ;
VAL_ 37 PrkgClimaWarn 0 "ClimaWarn_NoWarn" 1 "ClimaWarn_FuLo" 2 "ClimaWarn_BattLo" 3 "ClimaWarn_FuAndBattLo" 4 "ClimaWarn_TLo" 5 "ClimaWarn_THi" 6 "ClimaWarn_Error" 7 "ClimaWarn_HVError" 8 "ClimaWarn_ActvnLimd" ;
VAL_ 512 ClimaActv 0 "OnOff1_Off" 1 "OnOff1_On" ;
VAL_ 512 LvlOfClimaCmft 0 "LvlOfClimaCmft_Off" 1 "LvlOfClimaCmft_Lvl1" 2 "LvlOfClimaCmft_Lvl2" 3 "LvlOfClimaCmft_Lvl3" 4 "LvlOfClimaCmft_Lvl4" 5 "LvlOfClimaCmft_Lvl5" 6 "LvlOfClimaCmft_Lvl6" 7 "LvlOfClimaCmft_Lvl7" ;
VAL_ 512 RemClimaActv 0 "OnOff1_Off" 1 "OnOff1_On" ;
VAL_ 289 CmptmtAirTEstimdExtdQlyFlg 0 "GenQf1_UndefindDataAccur" 1 "GenQf1_TmpUndefdData" 2 "GenQf1_DataAccurNotWithinSpcn" 3 "GenQf1_AccurData" ;
VAL_ 289 CmptmtTFrntFanForCmptmtTRunng 0 "Flg1_Rst" 1 "Flg1_Set" ;
VAL_ 289 CmptmtTFrntQf 0 "CmptmtTFrntQf_SnsrDataUndefd" 1 "CmptmtTFrntQf_FanNotRunning" 2 "CmptmtTFrntQf_SnsrDataNotOk" 3 "CmptmtTFrntQf_SnsrDataOk" ;
VAL_ 289 EngRunngReqByClima 0 "EngRunngReq_Dft" 1 "EngRunngReq_StopInhb" 2 "EngRunngReq_RunReq" 3 "EngRunngReq_Resd" ;
VAL_ 289 EngSpdIncIdleForClima 0 "Flg1_Rst" 1 "Flg1_Set" ;
VAL_ 289 RlyCrashForClimaReq 0 "OnOff1_Off" 1 "OnOff1_On" ;
VAL_ 1029 AirTFbFromClimaDataQf 0 "DataQf_NotOk" 1 "DataQf_Ok" ;
VAL_ 1029 ClimaCmptSts 0 "CmptSts_NoRequest" 1 "CmptSts_CoolingRequest" 2 "CmptSts_HeatingRequest" 3 "CmptSts_CoolingAndHeatingRequest" 4 "CmptSts_PostHeating" ;
VAL_ 1029 ClimaDefrstSts 0 "OnOff1_Off" 1 "OnOff1_On" ;
VAL_ 1029 ClimaOvrHeatProActv 0 "OnOff1_Off" 1 "OnOff1_On" ;
VAL_ 1033 HvacAirTForRowFirstAtFlrLeE_0000 0 "HvacTIfQf_SnsrDataNotOk" 1 "HvacTIfQf_SnsrDataOk" ;
VAL_ 1033 HvacAirTForRowFirstAtFlrRiE_0000 0 "HvacTIfQf_SnsrDataNotOk" 1 "HvacTIfQf_SnsrDataOk" ;
VAL_ 1033 HvacAirTForRowFirstAtVentLe_0000 0 "HvacTIfQf_SnsrDataNotOk" 1 "HvacTIfQf_SnsrDataOk" ;
VAL_ 1033 HvacAirTForRowFirstAtVentRi_0000 0 "HvacTIfQf_SnsrDataNotOk" 1 "HvacTIfQf_SnsrDataOk" ;
VAL_ 1034 HvacAirTForRowSecAtFlrLeEvaprTQf 0 "HvacTIfQf_SnsrDataNotOk" 1 "HvacTIfQf_SnsrDataOk" ;
VAL_ 1034 HvacAirTForRowSecAtFlrRiEvaprTQf 0 "HvacTIfQf_SnsrDataNotOk" 1 "HvacTIfQf_SnsrDataOk" ;
VAL_ 1034 HvacAirTForRowSecAtVentLeEvaprTQ 0 "HvacTIfQf_SnsrDataNotOk" 1 "HvacTIfQf_SnsrDataOk" ;
VAL_ 1034 HvacAirTForRowSecAtVentRiEvaprTQ 0 "HvacTIfQf_SnsrDataNotOk" 1 "HvacTIfQf_SnsrDataOk" ;
VAL_ 1037 RemClimaWarn 0 "ClimaWarn_NoWarn" 1 "ClimaWarn_FuLo" 2 "ClimaWarn_BattLo" 3 "ClimaWarn_FuAndBattLo" 4 "ClimaWarn_TLo" 5 "ClimaWarn_THi" 6 "ClimaWarn_Error" 7 "ClimaWarn_HVError" 8 "ClimaWarn_ActvnLimd" ;
VAL_ 1037 WindIceDetdFrnt 0 "OnOff1_Off" 1 "OnOff1_On" ;
VAL_ 1037 WindIceDetdRe 0 "OnOff1_Off" 1 "OnOff1_On" ;
VAL_ 1040 CmptModForHp 0 "ModeCmptHp_vent" 1 "ModeCmptHp_cool" 2 "ModeCmptHp_hot" 3 "ModeCmptHp_cool_hot" 4 "ModeCmptHp_cool_defog" 5 "ModeCmptHp_hot_defog" 6 "ModeCmptHp_cool_hot_defog" 7 "ModeCmptHp_reserved" ;
VAL_ 1040 HpReqCritSts 0 "OnOff1_Off" 1 "OnOff1_On" ;
VAL_ 1040 HvacCondsorTEvaprTQf 0 "HvacTIfQf_SnsrDataNotOk" 1 "HvacTIfQf_SnsrDataOk" ;
VAL_ 1040 HvacCondsorTspEvaprTQf 0 "HvacTIfQf_SnsrDataNotOk" 1 "HvacTIfQf_SnsrDataOk" ;
VAL_ 1040 HvahBlwReq 0 "ClimaOffReq_NoReq" 1 "ClimaOffReq_SecRowOffReq" 2 "ClimaOffReq_TrdRowOffReq" 3 "ClimaOffReq_ClimaOff" ;
VAL_ 1040 ReEvapVlvSts 0 "EvaprVlvSts_VlvReqdToClsd" 1 "EvaprVlvSts_VlvReqdToOpen" 2 "EvaprVlvSts_ElecErrByCircOpen" 3 "EvaprVlvSts_ElecErrShoToGnd" 4 "EvaprVlvSts_ElecErrShoToPwrSply" 5 "EvaprVlvSts_Resd" ;
VAL_ 1040 RemClimaDelaySts 0 "OnOff1_Off" 1 "OnOff1_On" ;
VAL_ 1040 RemClimaExtnTiRspn 0 "OnOff1_Off" 1 "OnOff1_On" ;
VAL_ 1040 RemClimaHvRspn 0 "OnOff1_Off" 1 "OnOff1_On" ;
VAL_ 1040 RemClimaHvSts 0 "OnOff1_Off" 1 "OnOff1_On" ;
VAL_ 1049 ClimaSts 0 "ClimaSts_Start" 1 "ClimaSts_Finish" ;
VAL_ 1049 ElecDefrstReqMirrDefrstReq 0 "OnOff1_Off" 1 "OnOff1_On" ;
VAL_ 1049 ElecDefrstReqWinDefrstFrntReq 0 "OnOff1_Off" 1 "OnOff1_On" ;
VAL_ 1049 ElecDefrstReqWinDefrstReReq 0 "OnOff1_Off" 1 "OnOff1_On" ;
VAL_ 1049 FragCh1UseUpWrn 0 "Warn2_NoWarn" 1 "Warn2_Warn" ;
VAL_ 1049 FragCh2UseUpWrn 0 "Warn2_NoWarn" 1 "Warn2_Warn" ;
VAL_ 1049 FragCh3UseUpWrn 0 "Warn2_NoWarn" 1 "Warn2_Warn" ;
VAL_ 1049 FragCh4UseUpWrn 0 "Warn2_NoWarn" 1 "Warn2_Warn" ;
VAL_ 1049 FragCh5UseUpWrn 0 "Warn2_NoWarn" 1 "Warn2_Warn" ;
VAL_ 1049 FragLvlFrmClima 0 "RatUse_NoRequest" 1 "RatUse_Low" 2 "RatUse_Mid" 3 "RatUse_High" ;
VAL_ 1049 FragStsFrmClima 1 "AirFragSts_OFF" 2 "AirFragSts_ON" 3 "AirFragSts_Error" ;
VAL_ 1049 FrntHvacBlowerSts 0 "HvacFanSts_Off" 1 "HvacFanSts_On" 2 "HvacFanSts_Warning" 3 "HvacFanSts_Error" ;
VAL_ 1049 HvacCoolgEnaRe 0 "OnOff1_Off" 1 "OnOff1_On" ;
VAL_ 1049 HvacOsaAndRecActrQfForHp 0 "Err1_NoErr" 1 "Err1_Err" ;
VAL_ 1049 HvahHeatgReq 0 "OnOff1_Off" 1 "OnOff1_On" ;
VAL_ 1049 IntPm25StsFrmClima 0 "PmSnsrSts_Initial" 1 "PmSnsrSts_Collecting" 2 "PmSnsrSts_Complete" 3 "PmSnsrSts_Error" ;
VAL_ 1049 OutdPm25LvlFrmClima 0 "CmpmtAirPmLvl_Level1" 1 "CmpmtAirPmLvl_Level2" 2 "CmpmtAirPmLvl_Level3" 3 "CmpmtAirPmLvl_Level4" 4 "CmpmtAirPmLvl_Level5" 5 "CmpmtAirPmLvl_Level6" 6 "CmpmtAirPmLvl_Reserved" 7 "CmpmtAirPmLvl_Invalid" ;
VAL_ 1049 PostDrvgClimaAvl 0 "OnOff1_Off" 1 "OnOff1_On" ;
VAL_ 901 CcmIntCo2Lvl 0 "Co2Lvl_Lvl0Slight" 1 "Co2Lvl_Lvl1Low" 2 "Co2Lvl_Lvl2Middle" 3 "Co2Lvl_Lvl3High" ;
VAL_ 1145 CmptmtIntrMtrlTEstimdMtrlSnsrTQl 0 "Qly2_Flt" 1 "Qly2_NoInfo" 2 "Qly2_Vld" ;
VAL_ 1168 AmbTEstimdQf 0 "HvacTIfQf_SnsrDataNotOk" 1 "HvacTIfQf_SnsrDataOk" ;
VAL_ 1168 CcmAirClngSts 0 "AIUOff" 1 "AIUOn" 2 "Sleep" 3 "Reserved" ;
VAL_ 1168 SeatClimaDurgClimaHmiSeatHeatgFo 0 "SeatClimaLvl_Off" 1 "SeatClimaLvl_Lvl1" 2 "SeatClimaLvl_Lvl2" 3 "SeatClimaLvl_Lvl3" ;
VAL_ 1168 SeatClimaDurgClimaHmiSeatHe_0000 0 "SeatClimaLvl_Off" 1 "SeatClimaLvl_Lvl1" 2 "SeatClimaLvl_Lvl2" 3 "SeatClimaLvl_Lvl3" ;
VAL_ 1168 SeatClimaDurgClimaHmiSeatHe_0001 0 "SeatClimaLvl_Off" 1 "SeatClimaLvl_Lvl1" 2 "SeatClimaLvl_Lvl2" 3 "SeatClimaLvl_Lvl3" ;
VAL_ 1168 SeatClimaDurgClimaHmiSeatHe_0002 0 "SeatClimaLvl_Off" 1 "SeatClimaLvl_Lvl1" 2 "SeatClimaLvl_Lvl2" 3 "SeatClimaLvl_Lvl3" ;
VAL_ 1168 SeatClimaDurgClimaHmiSeatVentnFo 0 "SeatClimaLvl_Off" 1 "SeatClimaLvl_Lvl1" 2 "SeatClimaLvl_Lvl2" 3 "SeatClimaLvl_Lvl3" ;
VAL_ 1168 SeatClimaDurgClimaHmiSeatVe_0000 0 "SeatClimaLvl_Off" 1 "SeatClimaLvl_Lvl1" 2 "SeatClimaLvl_Lvl2" 3 "SeatClimaLvl_Lvl3" ;
VAL_ 1168 SeatClimaDurgClimaHmiSeatVe_0001 0 "SeatClimaLvl_Off" 1 "SeatClimaLvl_Lvl1" 2 "SeatClimaLvl_Lvl2" 3 "SeatClimaLvl_Lvl3" ;
VAL_ 1168 SeatClimaDurgClimaHmiSeatVe_0002 0 "SeatClimaLvl_Off" 1 "SeatClimaLvl_Lvl1" 2 "SeatClimaLvl_Lvl2" 3 "SeatClimaLvl_Lvl3" ;
VAL_ 1184 DefrstMaxSts 0 "Boolean_FALSE" 1 "Boolean_TRUE" ;
VAL_ 1184 ElecAirVentnAvlSts 0 "StsFd_None" 1 "StsFd_On" 2 "StsFd_Off" 3 "StsFd_Error" 4 "StsFd_Functionallimit" 5 "StsFd_Energylimit" 6 "StsFd_Resvd1" 7 "StsFd_Resvd2" ;
VAL_ 1184 FragRefreshPopUp 0 "OnOff1_Off" 1 "OnOff1_On" ;
VAL_ 1184 IntPm25HiPopUp 0 "IntPmHiPopUp_NoReq" 1 "IntPmHiPopUp_ClimaOn" 2 "IntPmHiPopUp_ClimaOnAndWinClsd" 3 "IntPmHiPopUp_Reserved" ;
VAL_ 1184 OutdAirQlyOutdAirQly 0 "AirQly_No" 1 "AirQly_LvlLo" 2 "AirQly_LvlMed" 3 "AirQly_LvlHi" ;
VAL_ 1184 OutdAirQlyQf 0 "OutdAirQlyQf_SnsrNotOk" 1 "OutdAirQlyQf_SnsrOk" ;
VAL_ 1184 OutdPm25StsFrmClima 0 "PmSnsrSts_Initial" 1 "PmSnsrSts_Collecting" 2 "PmSnsrSts_Complete" 3 "PmSnsrSts_Error" ;
VAL_ 1025 ClimaActvAlrmSts 0 "OnOff1_Off" 1 "OnOff1_On" ;
VAL_ 1025 HvacHeatgReq 0 "OnOff1_Off" 1 "OnOff1_On" ;
VAL_ 1025 HvacHeatrInletTempReqEvaprTQf 0 "HvacTIfQf_SnsrDataNotOk" 1 "HvacTIfQf_SnsrDataOk" ;
VAL_ 1025 HvacHexAirTHvacAirTForHeatrFrntQ 0 "OkNotOk_NotOk" 1 "OkNotOk_Ok" ;
VAL_ 295 AirFragCh1RunngSts 0 "OnOff1_Off" 1 "OnOff1_On" ;
VAL_ 295 AirFragCh2RunngSts 0 "OnOff1_Off" 1 "OnOff1_On" ;
VAL_ 295 AirFragCh3RunngSts 0 "OnOff1_Off" 1 "OnOff1_On" ;
VAL_ 295 AirFragCh4RunngSts 0 "OnOff1_Off" 1 "OnOff1_On" ;
VAL_ 295 AirFragCh5RunngSts 0 "OnOff1_Off" 1 "OnOff1_On" ;
VAL_ 295 EcoClimaSts 0 "OnOff1_Off" 1 "OnOff1_On" ;
VAL_ 295 SteerWhlHeatgDurgClima 0 "Boolean_FALSE" 1 "Boolean_TRUE" ;
VAL_ 831 ClimaCoolgReqLvl 0 "HvBattCoolgReq_NotReqd" 1 "HvBattCoolgReq_LoReq" 2 "HvBattCoolgReq_MedReq" 3 "HvBattCoolgReq_HiReq" ;
VAL_ 831 ClimaHeatgReqLvl 0 "HvBattCoolgReq_NotReqd" 1 "HvBattCoolgReq_LoReq" 2 "HvBattCoolgReq_MedReq" 3 "HvBattCoolgReq_HiReq" ;
VAL_ 831 ClimaOvrHeatPrtSts 0 "OnOff1_Off" 1 "OnOff1_On" ;
VAL_ 831 EvaprVlvReStsExtdDiagcStsForCirc 0 "DiagcSts2_DiagcStsNotRdy" 1 "DiagcSts2_DiagcStsPassd" 2 "DiagcSts2_DiagcStsFaild" 3 "DiagcSts2_Resd" ;
VAL_ 831 EvaprVlvReStsExtdDiagcStsForShoT 0 "DiagcSts2_DiagcStsNotRdy" 1 "DiagcSts2_DiagcStsPassd" 2 "DiagcSts2_DiagcStsFaild" 3 "DiagcSts2_Resd" ;
VAL_ 831 EvaprVlvReStsExtdDiagcStsFo_0000 0 "DiagcSts2_DiagcStsNotRdy" 1 "DiagcSts2_DiagcStsPassd" 2 "DiagcSts2_DiagcStsFaild" 3 "DiagcSts2_Resd" ;
VAL_ 831 ReHvacBlowerSts 0 "HvacFanSts_Off" 1 "HvacFanSts_On" 2 "HvacFanSts_Warning" 3 "HvacFanSts_Error" ;
VAL_ 831 RlyCmftForClimaReq 0 "OnOff1_Off" 1 "OnOff1_On" ;
VAL_ 831 UBoostReqByClima 0 "ReqSts1_NotReqd" 1 "ReqSts1_Reqd" ;
VAL_ 604 InCarCo2HighWarn 0 "Co2Lvl_Lvl0Slight" 1 "Co2Lvl_Lvl1Low" 2 "Co2Lvl_Lvl2Middle" 3 "Co2Lvl_Lvl3High" ;
VAL_ 604 IntCo2RunSts 0 "PmSnsrSts_Initial" 1 "PmSnsrSts_Collecting" 2 "PmSnsrSts_Complete" 3 "PmSnsrSts_Error" ;
VAL_ 593 AutoDefrstReqPopUp 0 "OnOff1_Off" 1 "OnOff1_On" ;
VAL_ 593 AutoDeHumPopUp 0 "ReqSts1_NotReqd" 1 "ReqSts1_Reqd" ;
VAL_ 593 ClimaOffReq 0 "ClimaOffReq_NoReq" 1 "ClimaOffReq_SecRowOffReq" 2 "ClimaOffReq_TrdRowOffReq" 3 "ClimaOffReq_ClimaOff" ;
VAL_ 593 ClimaOnReq 0 "ClimaOnReqSts_NoReq" 1 "ClimaOnReqSts_FstRowOn" 2 "ClimaOnReqSts_SecRowOn" 3 "ClimaOnReqSts_TrdRowOn" 4 "ClimaOnReqSts_AllOn" 5 "ClimaOnReqSts_FstAndSecRowOn" 6 "ClimaOnReqSts_SecAndTrdRowOn" 7 "ClimaOnReqSts_Rsvd" ;
VAL_ 593 ClimaOvrHeatProRspn 0 "OnOff1_Off" 1 "OnOff1_On" ;
VAL_ 593 ClimaOvrHeatProWarn 0 "ClimaOvrheatProWarnSts_NoWarn" 1 "ClimaOvrheatProWarnSts_Err" 2 "ClimaOvrheatProWarnSts_PwrLo" 3 "ClimaOvrheatProWarnSts_Tout" ;
VAL_ 593 Co2WarnForTelm 0 "OnOff1_Off" 1 "OnOff1_On" ;
VAL_ 593 DiDblLock 0 "EnableDisableCoding_Disabled" 1 "EnableDisableCoding_Enabled" ;
VAL_ 593 RemStrtClimaRspn 0 "OnOff1_Off" 1 "OnOff1_On" ;
VAL_ 593 RoofOpnReqFrmClima 0 "OnOff1_Off" 1 "OnOff1_On" ;
VAL_ 593 SunRoofOpnPopUpForHmi 0 "ReqSts1_NotReqd" 1 "ReqSts1_Reqd" ;
VAL_ 593 WinAndRoofReqFrmClima 0 "WinOpenClsGlbReqFromTelm_Idle" 1 "WinOpenClsGlbReqFromTelm_Open" 2 "WinOpenClsGlbReqFromTelm_Close" ;
VAL_ 593 WinRfClsdReqForCoolgDwn 0 "Warn2_NoWarn" 1 "Warn2_Warn" ;
VAL_ 805 CmptmtTReCmptmtTFrntQf 0 "CmptmtTFrntQf_SnsrDataUndefd" 1 "CmptmtTFrntQf_FanNotRunning" 2 "CmptmtTFrntQf_SnsrDataNotOk" 3 "CmptmtTFrntQf_SnsrDataOk" ;
VAL_ 805 CmptmtTReFanForCmptmtTRunng 0 "Flg1_Rst" 1 "Flg1_Set" ;
VAL_ 805 EvaprTReEvaprTQf 0 "HvacTIfQf_SnsrDataNotOk" 1 "HvacTIfQf_SnsrDataOk" ;
VAL_ 579 CdsParkgClimaActv 0 "OnOff1_Off" 1 "OnOff1_On" ;
VAL_ 579 ClimaOvrHeatProActvSts 0 "OnOff1_Off" 1 "OnOff1_On" ;
VAL_ 579 RemVentActvSts 0 "OnOff1_Off" 1 "OnOff1_On" ;
VAL_ 579 RemVentReqRspnFb 0 "OnOff1_Off" 1 "OnOff1_On" ;
VAL_ 579 RemVentWarnSts 0 "RemVentWarningSts_NoErr" 1 "RemVentWarningSts_Err" 2 "RemVentWarningSts_PwrNotAllwd" 3 "RemVentWarningSts_EgyNotAllwd" ;
VAL_ 1346 VFCVectorCCMVFCid0 0 "VFCOnOff_Off" 1 "VFCOnOff_On" ;
VAL_ 1346 VFCVectorCCMVFCid1 0 "VFCOnOff_Off" 1 "VFCOnOff_On" ;
VAL_ 1346 VFCVectorCCMVFCid10 0 "VFCOnOff_Off" 1 "VFCOnOff_On" ;
VAL_ 1346 VFCVectorCCMVFCid11 0 "VFCOnOff_Off" 1 "VFCOnOff_On" ;
VAL_ 1346 VFCVectorCCMVFCid12 0 "VFCOnOff_Off" 1 "VFCOnOff_On" ;
VAL_ 1346 VFCVectorCCMVFCid13 0 "VFCOnOff_Off" 1 "VFCOnOff_On" ;
VAL_ 1346 VFCVectorCCMVFCid14 0 "VFCOnOff_Off" 1 "VFCOnOff_On" ;
VAL_ 1346 VFCVectorCCMVFCid15 0 "VFCOnOff_Off" 1 "VFCOnOff_On" ;
VAL_ 1346 VFCVectorCCMVFCid16 0 "VFCOnOff_Off" 1 "VFCOnOff_On" ;
VAL_ 1346 VFCVectorCCMVFCid17 0 "VFCOnOff_Off" 1 "VFCOnOff_On" ;
VAL_ 1346 VFCVectorCCMVFCid18 0 "VFCOnOff_Off" 1 "VFCOnOff_On" ;
VAL_ 1346 VFCVectorCCMVFCid19 0 "VFCOnOff_Off" 1 "VFCOnOff_On" ;
VAL_ 1346 VFCVectorCCMVFCid2 0 "VFCOnOff_Off" 1 "VFCOnOff_On" ;
VAL_ 1346 VFCVectorCCMVFCid20 0 "VFCOnOff_Off" 1 "VFCOnOff_On" ;
VAL_ 1346 VFCVectorCCMVFCid21 0 "VFCOnOff_Off" 1 "VFCOnOff_On" ;
VAL_ 1346 VFCVectorCCMVFCid22 0 "VFCOnOff_Off" 1 "VFCOnOff_On" ;
VAL_ 1346 VFCVectorCCMVFCid23 0 "VFCOnOff_Off" 1 "VFCOnOff_On" ;
VAL_ 1346 VFCVectorCCMVFCid24 0 "VFCOnOff_Off" 1 "VFCOnOff_On" ;
VAL_ 1346 VFCVectorCCMVFCid25 0 "VFCOnOff_Off" 1 "VFCOnOff_On" ;
VAL_ 1346 VFCVectorCCMVFCid26 0 "VFCOnOff_Off" 1 "VFCOnOff_On" ;
VAL_ 1346 VFCVectorCCMVFCid27 0 "VFCOnOff_Off" 1 "VFCOnOff_On" ;
VAL_ 1346 VFCVectorCCMVFCid28 0 "VFCOnOff_Off" 1 "VFCOnOff_On" ;
VAL_ 1346 VFCVectorCCMVFCid29 0 "VFCOnOff_Off" 1 "VFCOnOff_On" ;
VAL_ 1346 VFCVectorCCMVFCid3 0 "VFCOnOff_Off" 1 "VFCOnOff_On" ;
VAL_ 1346 VFCVectorCCMVFCid30 0 "VFCOnOff_Off" 1 "VFCOnOff_On" ;
VAL_ 1346 VFCVectorCCMVFCid31 0 "VFCOnOff_Off" 1 "VFCOnOff_On" ;
VAL_ 1346 VFCVectorCCMVFCid32 0 "VFCOnOff_Off" 1 "VFCOnOff_On" ;
VAL_ 1346 VFCVectorCCMVFCid33 0 "VFCOnOff_Off" 1 "VFCOnOff_On" ;
VAL_ 1346 VFCVectorCCMVFCid34 0 "VFCOnOff_Off" 1 "VFCOnOff_On" ;
VAL_ 1346 VFCVectorCCMVFCid35 0 "VFCOnOff_Off" 1 "VFCOnOff_On" ;
VAL_ 1346 VFCVectorCCMVFCid36 0 "VFCOnOff_Off" 1 "VFCOnOff_On" ;
VAL_ 1346 VFCVectorCCMVFCid37 0 "VFCOnOff_Off" 1 "VFCOnOff_On" ;
VAL_ 1346 VFCVectorCCMVFCid38 0 "VFCOnOff_Off" 1 "VFCOnOff_On" ;
VAL_ 1346 VFCVectorCCMVFCid39 0 "VFCOnOff_Off" 1 "VFCOnOff_On" ;
VAL_ 1346 VFCVectorCCMVFCid4 0 "VFCOnOff_Off" 1 "VFCOnOff_On" ;
VAL_ 1346 VFCVectorCCMVFCid40 0 "VFCOnOff_Off" 1 "VFCOnOff_On" ;
VAL_ 1346 VFCVectorCCMVFCid41 0 "VFCOnOff_Off" 1 "VFCOnOff_On" ;
VAL_ 1346 VFCVectorCCMVFCid42 0 "VFCOnOff_Off" 1 "VFCOnOff_On" ;
VAL_ 1346 VFCVectorCCMVFCid43 0 "VFCOnOff_Off" 1 "VFCOnOff_On" ;
VAL_ 1346 VFCVectorCCMVFCid44 0 "VFCOnOff_Off" 1 "VFCOnOff_On" ;
VAL_ 1346 VFCVectorCCMVFCid45 0 "VFCOnOff_Off" 1 "VFCOnOff_On" ;
VAL_ 1346 VFCVectorCCMVFCid46 0 "VFCOnOff_Off" 1 "VFCOnOff_On" ;
VAL_ 1346 VFCVectorCCMVFCid47 0 "VFCOnOff_Off" 1 "VFCOnOff_On" ;
VAL_ 1346 VFCVectorCCMVFCid48 0 "VFCOnOff_Off" 1 "VFCOnOff_On" ;
VAL_ 1346 VFCVectorCCMVFCid49 0 "VFCOnOff_Off" 1 "VFCOnOff_On" ;
VAL_ 1346 VFCVectorCCMVFCid5 0 "VFCOnOff_Off" 1 "VFCOnOff_On" ;
VAL_ 1346 VFCVectorCCMVFCid50 0 "VFCOnOff_Off" 1 "VFCOnOff_On" ;
VAL_ 1346 VFCVectorCCMVFCid51 0 "VFCOnOff_Off" 1 "VFCOnOff_On" ;
VAL_ 1346 VFCVectorCCMVFCid52 0 "VFCOnOff_Off" 1 "VFCOnOff_On" ;
VAL_ 1346 VFCVectorCCMVFCid53 0 "VFCOnOff_Off" 1 "VFCOnOff_On" ;
VAL_ 1346 VFCVectorCCMVFCid54 0 "VFCOnOff_Off" 1 "VFCOnOff_On" ;
VAL_ 1346 VFCVectorCCMVFCid55 0 "VFCOnOff_Off" 1 "VFCOnOff_On" ;
VAL_ 1346 VFCVectorCCMVFCid56 0 "VFCOnOff_Off" 1 "VFCOnOff_On" ;
VAL_ 1346 VFCVectorCCMVFCid57 0 "VFCOnOff_Off" 1 "VFCOnOff_On" ;
VAL_ 1346 VFCVectorCCMVFCid58 0 "VFCOnOff_Off" 1 "VFCOnOff_On" ;
VAL_ 1346 VFCVectorCCMVFCid59 0 "VFCOnOff_Off" 1 "VFCOnOff_On" ;
VAL_ 1346 VFCVectorCCMVFCid6 0 "VFCOnOff_Off" 1 "VFCOnOff_On" ;
VAL_ 1346 VFCVectorCCMVFCid60 0 "VFCOnOff_Off" 1 "VFCOnOff_On" ;
VAL_ 1346 VFCVectorCCMVFCid61 0 "VFCOnOff_Off" 1 "VFCOnOff_On" ;
VAL_ 1346 VFCVectorCCMVFCid7 0 "VFCOnOff_Off" 1 "VFCOnOff_On" ;
VAL_ 1346 VFCVectorCCMVFCid8 0 "VFCOnOff_Off" 1 "VFCOnOff_On" ;
VAL_ 1346 VFCVectorCCMVFCid9 0 "VFCOnOff_Off" 1 "VFCOnOff_On" ;
VAL_ 32 DigVideoRecSwt 0 "PsdNotPsd_NotPsd" 1 "PsdNotPsd_Psd" ;
VAL_ 32 DoorDrvrLockCmd 0 "LockActvnSafe1_LockActvnOff" 1 "LockActvnSafe1_LockActvnUnlck" 2 "LockActvnSafe1_LockActvnLock" 3 "LockActvnSafe1_LockActvnSafe" 4 "LockActvnSafe1_LockActvnUnlckByCrash1" 8 "LockActvnSafe1_LockActvnUnlckByCrash2" 12 "LockActvnSafe1_LockActvnUnlckByCrash0" 13 "LockActvnSafe1_LockActvnUnlckByCrash4" 14 "LockActvnSafe1_LockActvnUnlckByCrash3" ;
VAL_ 32 DoorDrvrRelsReq 0 "OnOffSafe1_OnOffSafeInvld1" 1 "OnOffSafe1_OnOffSafeOn" 2 "OnOffSafe1_OnOffSafeOff" 3 "OnOffSafe1_OnOffSafeInvld2" ;
VAL_ 32 DoorLeReLockCmd 0 "LockActvnSafe1_LockActvnOff" 1 "LockActvnSafe1_LockActvnUnlck" 2 "LockActvnSafe1_LockActvnLock" 3 "LockActvnSafe1_LockActvnSafe" 4 "LockActvnSafe1_LockActvnUnlckByCrash1" 8 "LockActvnSafe1_LockActvnUnlckByCrash2" 12 "LockActvnSafe1_LockActvnUnlckByCrash0" 13 "LockActvnSafe1_LockActvnUnlckByCrash4" 14 "LockActvnSafe1_LockActvnUnlckByCrash3" ;
VAL_ 32 DoorLeReRelsReq 0 "OnOffSafe1_OnOffSafeInvld1" 1 "OnOffSafe1_OnOffSafeOn" 2 "OnOffSafe1_OnOffSafeOff" 3 "OnOffSafe1_OnOffSafeInvld2" ;
VAL_ 32 DoorPassLockCmd 0 "LockActvnSafe1_LockActvnOff" 1 "LockActvnSafe1_LockActvnUnlck" 2 "LockActvnSafe1_LockActvnLock" 3 "LockActvnSafe1_LockActvnSafe" 4 "LockActvnSafe1_LockActvnUnlckByCrash1" 8 "LockActvnSafe1_LockActvnUnlckByCrash2" 12 "LockActvnSafe1_LockActvnUnlckByCrash0" 13 "LockActvnSafe1_LockActvnUnlckByCrash4" 14 "LockActvnSafe1_LockActvnUnlckByCrash3" ;
VAL_ 32 DoorPassRelsReq 0 "OnOffSafe1_OnOffSafeInvld1" 1 "OnOffSafe1_OnOffSafeOn" 2 "OnOffSafe1_OnOffSafeOff" 3 "OnOffSafe1_OnOffSafeInvld2" ;
VAL_ 32 DoorRiReLockCmd 0 "LockActvnSafe1_LockActvnOff" 1 "LockActvnSafe1_LockActvnUnlck" 2 "LockActvnSafe1_LockActvnLock" 3 "LockActvnSafe1_LockActvnSafe" 4 "LockActvnSafe1_LockActvnUnlckByCrash1" 8 "LockActvnSafe1_LockActvnUnlckByCrash2" 12 "LockActvnSafe1_LockActvnUnlckByCrash0" 13 "LockActvnSafe1_LockActvnUnlckByCrash4" 14 "LockActvnSafe1_LockActvnUnlckByCrash3" ;
VAL_ 32 DoorRiReRelsReq 0 "OnOffSafe1_OnOffSafeInvld1" 1 "OnOffSafe1_OnOffSafeOn" 2 "OnOffSafe1_OnOffSafeOff" 3 "OnOffSafe1_OnOffSafeInvld2" ;
VAL_ 32 GlvBoxOpenReqFromUI 0 "PsdNotPsd_NotPsd" 1 "PsdNotPsd_Psd" ;
VAL_ 32 HmiSeatClimaHmiSeatHeatgForRowFi 0 "SeatClimaLvl_Off" 1 "SeatClimaLvl_Lvl1" 2 "SeatClimaLvl_Lvl2" 3 "SeatClimaLvl_Lvl3" ;
VAL_ 32 HmiSeatClimaHmiSeatHeatgFor_0000 0 "SeatClimaLvl_Off" 1 "SeatClimaLvl_Lvl1" 2 "SeatClimaLvl_Lvl2" 3 "SeatClimaLvl_Lvl3" ;
VAL_ 32 HmiSeatClimaHmiSeatHeatgForRowSe 0 "SeatClimaLvl_Off" 1 "SeatClimaLvl_Lvl1" 2 "SeatClimaLvl_Lvl2" 3 "SeatClimaLvl_Lvl3" ;
VAL_ 32 HmiSeatClimaHmiSeatHeatgFor_0001 0 "SeatClimaLvl_Off" 1 "SeatClimaLvl_Lvl1" 2 "SeatClimaLvl_Lvl2" 3 "SeatClimaLvl_Lvl3" ;
VAL_ 32 HmiSeatClimaHmiSeatVentnForRowFi 0 "SeatClimaLvl_Off" 1 "SeatClimaLvl_Lvl1" 2 "SeatClimaLvl_Lvl2" 3 "SeatClimaLvl_Lvl3" ;
VAL_ 32 HmiSeatClimaHmiSeatVentnFor_0000 0 "SeatClimaLvl_Off" 1 "SeatClimaLvl_Lvl1" 2 "SeatClimaLvl_Lvl2" 3 "SeatClimaLvl_Lvl3" ;
VAL_ 32 HmiSeatClimaHmiSeatVentnForRowSe 0 "SeatClimaLvl_Off" 1 "SeatClimaLvl_Lvl1" 2 "SeatClimaLvl_Lvl2" 3 "SeatClimaLvl_Lvl3" ;
VAL_ 32 HmiSeatClimaHmiSeatVentnFor_0001 0 "SeatClimaLvl_Off" 1 "SeatClimaLvl_Lvl1" 2 "SeatClimaLvl_Lvl2" 3 "SeatClimaLvl_Lvl3" ;
VAL_ 32 IndcrSts 0 "IndcrSts1_Off" 1 "IndcrSts1_LeOn" 2 "IndcrSts1_RiOn" 3 "IndcrSts1_LeAndRiOn" ;
VAL_ 32 TrlrLiBrkActvt 0 "OnOff1_Off" 1 "OnOff1_On" ;
VAL_ 32 TrlrLiTurnIndcrActvt 0 "IndcrSts1_Off" 1 "IndcrSts1_LeOn" 2 "IndcrSts1_RiOn" 3 "IndcrSts1_LeAndRiOn" ;
VAL_ 64 CabinCoolingReq 0 "Boolean_FALSE" 1 "Boolean_TRUE" ;
VAL_ 64 DoorDrvrIntrSwtLedLockgCmd 0 "OnOff1_Off" 1 "OnOff1_On" ;
VAL_ 64 DoorDrvrSts 0 "DoorSts2_Ukwn" 1 "DoorSts2_Opend" 2 "DoorSts2_Clsd" ;
VAL_ 64 DoorLeReSts 0 "DoorSts2_Ukwn" 1 "DoorSts2_Opend" 2 "DoorSts2_Clsd" ;
VAL_ 64 DoorPassIntrSwtLedLockgCmd 0 "OnOff1_Off" 1 "OnOff1_On" ;
VAL_ 64 IHUAPSts 0 "OnOff1_Off" 1 "OnOff1_On" ;
VAL_ 64 LcmaIndcnLe 0 "WarnLvl_NoWarn" 1 "WarnLvl_WarnLvl1" 2 "WarnLvl_WarnLvl2_NoAudio" 3 "WarnLvl_WarnLvl3_Audio" ;
VAL_ 64 LcmaIndcnRi 0 "WarnLvl_NoWarn" 1 "WarnLvl_WarnLvl1" 2 "WarnLvl_WarnLvl2_NoAudio" 3 "WarnLvl_WarnLvl3_Audio" ;
VAL_ 64 PassLoadAndStoreReqErgoPosn 0 "PassMemPosn_Idle" 1 "PassMemPosn_MemBnk1" 2 "PassMemPosn_MemBnk2" 3 "PassMemPosn_MemBnk3" ;
VAL_ 64 PassLoadAndStoreReqErgoSetgEve 0 "EveMemPosn_Idle" 1 "EveMemPosn_Store" 2 "EveMemPosn_Load" 3 "EveMemPosn_Stop" 4 "EveMemPosn_AutMovmt" 5 "EveMemPosn_Upload" 6 "EveMemPosn_Download" 7 "EveMemPosn_Clear" ;
VAL_ 64 SaveSetgToMemPrmnt 0 "OffOnAut1_Off" 1 "OffOnAut1_On" 2 "OffOnAut1_Aut" ;
VAL_ 64 TrNoKeyPrsntAcoustReq 0 "OnOff1_Off" 1 "OnOff1_On" ;
VAL_ 64 TrOpenerReqTrigSrc 0 "TrOpenerTrigSrc1_TrNoTrigSrc" 1 "TrOpenerTrigSrc1_TrKeyRem" 2 "TrOpenerTrigSrc1_TrSwtIntr" 3 "TrOpenerTrigSrc1_TrByFootOper" 4 "TrOpenerTrigSrc1_TrHndlOutd" 5 "TrOpenerTrigSrc1_TrShutFace" 6 "TrOpenerTrigSrc1_TrHMI" 7 "TrOpenerTrigSrc1_TrByAppch" ;
VAL_ 64 TrOpenerReqTrOpenerReq 0 "TrOpenerReq1_TrOpenerIdle" 1 "TrOpenerReq1_TrOpenerOpen" 2 "TrOpenerReq1_TrOpenerCls" 3 "TrOpenerReq1_TrOpenerStop" 4 "TrOpenerReq1_TrOpenerClsDly" ;
VAL_ 64 TwliBriSts 0 "TwliBriSts1_Night" 1 "TwliBriSts1_Day" ;
VAL_ 64 VehMtnStVehMtnSt 0 "VehMtnSt2_Ukwn" 1 "VehMtnSt2_StandStillVal1" 2 "VehMtnSt2_StandStillVal2" 3 "VehMtnSt2_StandStillVal3" 4 "VehMtnSt2_RollgFwdVal1" 5 "VehMtnSt2_RollgFwdVal2" 6 "VehMtnSt2_RollgBackwVal1" 7 "VehMtnSt2_RollgBackwVal2" ;
VAL_ 64 WinGlbCmd 0 "OpenClsGlbCmd_Idle" 1 "OpenClsGlbCmd_GlobalOpenWindow" 2 "OpenClsGlbCmd_GlobalCloseWindowAndSunroof" 3 "OpenClsGlbCmd_GlobalCloseWindow" 4 "OpenClsGlbCmd_GlobalStop" 5 "OpenClsGlbCmd_Resd1" 6 "OpenClsGlbCmd_Resd2" 7 "OpenClsGlbCmd_Resd3" ;
VAL_ 118 ActvnOfIndcrIndcrOut 0 "IndcrSts1_Off" 1 "IndcrSts1_LeOn" 2 "IndcrSts1_RiOn" 3 "IndcrSts1_LeAndRiOn" ;
VAL_ 118 DoorSldngLeReRelsReq 0 "OnOffSafe1_OnOffSafeInvld1" 1 "OnOffSafe1_OnOffSafeOn" 2 "OnOffSafe1_OnOffSafeOff" 3 "OnOffSafe1_OnOffSafeInvld2" ;
VAL_ 118 DoorSldngRiReRelsReq 0 "OnOffSafe1_OnOffSafeInvld1" 1 "OnOffSafe1_OnOffSafeOn" 2 "OnOffSafe1_OnOffSafeOff" 3 "OnOffSafe1_OnOffSafeInvld2" ;
VAL_ 118 VehSpdLgtQf 0 "GenQf1_UndefindDataAccur" 1 "GenQf1_TmpUndefdData" 2 "GenQf1_DataAccurNotWithinSpcn" 3 "GenQf1_AccurData" ;
VAL_ 1072 ClimRlyCmd 0 "OnOff1_Off" 1 "OnOff1_On" ;
VAL_ 1072 RlyCmdCmft 0 "OnOff1_Off" 1 "OnOff1_On" ;
VAL_ 1072 SolarSnsrVluQf 0 "DataQf_NotOk" 1 "DataQf_Ok" ;
SIG_GROUP_ 1435 DvlpFrameForCCM 1 : DvlpFrameForCCMByte0 DvlpFrameForCCMByte1 DvlpFrameForCCMByte2 DvlpFrameForCCMByte3 DvlpFrameForCCMByte4 DvlpFrameForCCMByte5 DvlpFrameForCCMByte6 DvlpFrameForCCMByte7;
SIG_GROUP_ 177 EvaprTFrnt 1 : EvaprTFrntEvaprTFrnt EvaprTFrntEvaprTQf;
SIG_GROUP_ 289 CmptmtAirTEstimdExtd 1 : CmptmtAirTEstimdExtdComptmtT CmptmtAirTEstimdExtdQlyFlg;
SIG_GROUP_ 289 CmptmtTFrnt 1 : CmptmtTFrntCmptmtTFrnt CmptmtTFrntFanForCmptmtTRunng CmptmtTFrntQf;
SIG_GROUP_ 1029 AirTFbFromClima 1 : AirTFbFromClimaAirTFbFromClima AirTFbFromClimaDataQf;
SIG_GROUP_ 1033 HvacAirTForRowFirstAtFlrLe 1 : HvacAirTForRowFirstAtFlrLeEvaprT HvacAirTForRowFirstAtFlrLeE_0000;
SIG_GROUP_ 1033 HvacAirTForRowFirstAtFlrRi 1 : HvacAirTForRowFirstAtFlrRiEvaprT HvacAirTForRowFirstAtFlrRiE_0000;
SIG_GROUP_ 1033 HvacAirTForRowFirstAtVentLe 1 : HvacAirTForRowFirstAtVentLeEvapr HvacAirTForRowFirstAtVentLe_0000;
SIG_GROUP_ 1033 HvacAirTForRowFirstAtVentRi 1 : HvacAirTForRowFirstAtVentRiEvapr HvacAirTForRowFirstAtVentRi_0000;
SIG_GROUP_ 1034 HvacAirTForRowSecAtFlrLe 1 : HvacAirTForRowSecAtFlrLeEvaprTFr HvacAirTForRowSecAtFlrLeEvaprTQf;
SIG_GROUP_ 1034 HvacAirTForRowSecAtFlrRi 1 : HvacAirTForRowSecAtFlrRiEvaprTFr HvacAirTForRowSecAtFlrRiEvaprTQf;
SIG_GROUP_ 1034 HvacAirTForRowSecAtVentLe 1 : HvacAirTForRowSecAtVentLeEvaprTF HvacAirTForRowSecAtVentLeEvaprTQ;
SIG_GROUP_ 1034 HvacAirTForRowSecAtVentRi 1 : HvacAirTForRowSecAtVentRiEvaprTF HvacAirTForRowSecAtVentRiEvaprTQ;
SIG_GROUP_ 1040 HvacCondsorT 1 : HvacCondsorTEvaprTFrnt HvacCondsorTEvaprTQf;
SIG_GROUP_ 1040 HvacCondsorTsp 1 : HvacCondsorTspEvaprTFrnt HvacCondsorTspEvaprTQf;
SIG_GROUP_ 1049 ElecDefrstReq 1 : ElecDefrstReqMirrDefrstReq ElecDefrstReqWinDefrstFrntReq ElecDefrstReqWinDefrstReReq;
SIG_GROUP_ 1145 CmptmtIntrMtrlTEstimd 1 : CmptmtIntrMtrlTEstimdMtrlSnsrT CmptmtIntrMtrlTEstimdMtrlSnsrTQl;
SIG_GROUP_ 1168 AmbTEstimd 1 : AmbTEstimdAmbTEstimd AmbTEstimdQf;
SIG_GROUP_ 1168 SeatClimaDurgClima 1 : SeatClimaDurgClimaHmiSeatHeatgFo SeatClimaDurgClimaHmiSeatHe_0000 SeatClimaDurgClimaHmiSeatHe_0001 SeatClimaDurgClimaHmiSeatHe_0002 SeatClimaDurgClimaHmiSeatVentnFo SeatClimaDurgClimaHmiSeatVe_0000 SeatClimaDurgClimaHmiSeatVe_0001 SeatClimaDurgClimaHmiSeatVe_0002;
SIG_GROUP_ 1184 OutdAirQly 1 : OutdAirQlyOutdAirQly OutdAirQlyQf;
SIG_GROUP_ 1025 HvacHeatrInletTempReq 1 : HvacHeatrInletTempReqEvaprTFrnt HvacHeatrInletTempReqEvaprTQf;
SIG_GROUP_ 1025 HvacHexAirT 1 : HvacHexAirTHvacAirTForHeatrFrnt HvacHexAirTHvacAirTForHeatrFrntQ;
SIG_GROUP_ 831 EvaprVlvReStsExtd 1 : EvaprVlvReStsExtdDiagcStsForCirc EvaprVlvReStsExtdDiagcStsForShoT EvaprVlvReStsExtdDiagcStsFo_0000;
SIG_GROUP_ 1152 CcmCaliSig1 1 : CcmCaliSig1Byte0 CcmCaliSig1Byte1 CcmCaliSig1Byte2 CcmCaliSig1Byte3 CcmCaliSig1Byte4 CcmCaliSig1Byte5 CcmCaliSig1Byte6 CcmCaliSig1Byte7;
SIG_GROUP_ 1153 CcmCaliSig2 1 : CcmCaliSig2Byte0 CcmCaliSig2Byte1 CcmCaliSig2Byte2 CcmCaliSig2Byte3 CcmCaliSig2Byte4 CcmCaliSig2Byte5 CcmCaliSig2Byte6 CcmCaliSig2Byte7;
SIG_GROUP_ 1154 CcmCaliSig3 1 : CcmCaliSig3Byte0 CcmCaliSig3Byte1 CcmCaliSig3Byte2 CcmCaliSig3Byte3 CcmCaliSig3Byte4 CcmCaliSig3Byte5 CcmCaliSig3Byte6 CcmCaliSig3Byte7;
SIG_GROUP_ 1155 CcmCaliSig4 1 : CcmCaliSig4Byte0 CcmCaliSig4Byte1 CcmCaliSig4Byte2 CcmCaliSig4Byte3 CcmCaliSig4Byte4 CcmCaliSig4Byte5 CcmCaliSig4Byte6 CcmCaliSig4Byte7;
SIG_GROUP_ 1156 CcmCaliSig5 1 : CcmCaliSig5Byte0 CcmCaliSig5Byte1 CcmCaliSig5Byte2 CcmCaliSig5Byte3 CcmCaliSig5Byte4 CcmCaliSig5Byte5 CcmCaliSig5Byte6 CcmCaliSig5Byte7;
SIG_GROUP_ 1157 CcmCaliSig6 1 : CcmCaliSig6Byte0 CcmCaliSig6Byte1 CcmCaliSig6Byte2 CcmCaliSig6Byte3 CcmCaliSig6Byte4 CcmCaliSig6Byte5 CcmCaliSig6Byte6 CcmCaliSig6Byte7;
SIG_GROUP_ 1158 CcmCaliSig7 1 : CcmCaliSig7Byte0 CcmCaliSig7Byte1 CcmCaliSig7Byte2 CcmCaliSig7Byte3 CcmCaliSig7Byte4 CcmCaliSig7Byte5 CcmCaliSig7Byte6 CcmCaliSig7Byte7;
SIG_GROUP_ 1159 CcmCaliSig8 1 : CcmCaliSig8Byte0 CcmCaliSig8Byte1 CcmCaliSig8Byte2 CcmCaliSig8Byte3 CcmCaliSig8Byte4 CcmCaliSig8Byte5 CcmCaliSig8Byte6 CcmCaliSig8Byte7;
SIG_GROUP_ 1160 CcmCaliSig9 1 : CcmCaliSig9Byte0 CcmCaliSig9Byte1 CcmCaliSig9Byte2 CcmCaliSig9Byte3 CcmCaliSig9Byte4 CcmCaliSig9Byte5 CcmCaliSig9Byte6 CcmCaliSig9Byte7;
SIG_GROUP_ 1161 CcmCaliSig10 1 : CcmCaliSig10Byte0 CcmCaliSig10Byte1 CcmCaliSig10Byte2 CcmCaliSig10Byte3 CcmCaliSig10Byte4 CcmCaliSig10Byte5 CcmCaliSig10Byte6 CcmCaliSig10Byte7;
SIG_GROUP_ 1162 CcmCaliSig11 1 : CcmCaliSig11Byte0 CcmCaliSig11Byte1 CcmCaliSig11Byte2 CcmCaliSig11Byte3 CcmCaliSig11Byte4 CcmCaliSig11Byte5 CcmCaliSig11Byte6 CcmCaliSig11Byte7;
SIG_GROUP_ 1163 CcmCaliSig12 1 : CcmCaliSig12Byte0 CcmCaliSig12Byte1 CcmCaliSig12Byte2 CcmCaliSig12Byte3 CcmCaliSig12Byte4 CcmCaliSig12Byte5 CcmCaliSig12Byte6 CcmCaliSig12Byte7;
SIG_GROUP_ 805 CmptmtTRe 1 : CmptmtTReCmptmtTFrnt CmptmtTReCmptmtTFrntQf CmptmtTReFanForCmptmtTRunng;
SIG_GROUP_ 805 EvaprTRe 1 : EvaprTReEvaprTFrnt EvaprTReEvaprTQf;
SIG_GROUP_ 1346 VFCVectorCCM 1 : VFCVectorCCMBlockID VFCVectorCCMVFCid0 VFCVectorCCMVFCid1 VFCVectorCCMVFCid10 VFCVectorCCMVFCid11 VFCVectorCCMVFCid12 VFCVectorCCMVFCid13 VFCVectorCCMVFCid14 VFCVectorCCMVFCid15 VFCVectorCCMVFCid16 VFCVectorCCMVFCid17 VFCVectorCCMVFCid18 VFCVectorCCMVFCid19 VFCVectorCCMVFCid2 VFCVectorCCMVFCid20 VFCVectorCCMVFCid21 VFCVectorCCMVFCid22 VFCVectorCCMVFCid23 VFCVectorCCMVFCid24 VFCVectorCCMVFCid25 VFCVectorCCMVFCid26 VFCVectorCCMVFCid27 VFCVectorCCMVFCid28 VFCVectorCCMVFCid29 VFCVectorCCMVFCid3 VFCVectorCCMVFCid30 VFCVectorCCMVFCid31 VFCVectorCCMVFCid32 VFCVectorCCMVFCid33 VFCVectorCCMVFCid34 VFCVectorCCMVFCid35 VFCVectorCCMVFCid36 VFCVectorCCMVFCid37 VFCVectorCCMVFCid38 VFCVectorCCMVFCid39 VFCVectorCCMVFCid4 VFCVectorCCMVFCid40 VFCVectorCCMVFCid41 VFCVectorCCMVFCid42 VFCVectorCCMVFCid43 VFCVectorCCMVFCid44 VFCVectorCCMVFCid45 VFCVectorCCMVFCid46 VFCVectorCCMVFCid47 VFCVectorCCMVFCid48 VFCVectorCCMVFCid49 VFCVectorCCMVFCid5 VFCVectorCCMVFCid50 VFCVectorCCMVFCid51 VFCVectorCCMVFCid52 VFCVectorCCMVFCid53 VFCVectorCCMVFCid54 VFCVectorCCMVFCid55 VFCVectorCCMVFCid56 VFCVectorCCMVFCid57 VFCVectorCCMVFCid58 VFCVectorCCMVFCid59 VFCVectorCCMVFCid6 VFCVectorCCMVFCid60 VFCVectorCCMVFCid61 VFCVectorCCMVFCid7 VFCVectorCCMVFCid8 VFCVectorCCMVFCid9;
SIG_GROUP_ 1434 DiagFrameForECM 1 : DiagFrameForECMByte0 DiagFrameForECMByte1 DiagFrameForECMByte2 DiagFrameForECMByte3 DiagFrameForECMByte4 DiagFrameForECMByte5 DiagFrameForECMByte6 DiagFrameForECMByte7;
SIG_GROUP_ 32 HmiSeatClima 1 : HmiSeatClimaHmiSeatHeatgForRowFi HmiSeatClimaHmiSeatHeatgFor_0000 HmiSeatClimaHmiSeatHeatgForRowSe HmiSeatClimaHmiSeatHeatgFor_0001 HmiSeatClimaHmiSeatVentnForRowFi HmiSeatClimaHmiSeatVentnFor_0000 HmiSeatClimaHmiSeatVentnForRowSe HmiSeatClimaHmiSeatVentnFor_0001;
SIG_GROUP_ 64 PassLoadAndStoreReq 1 : PassLoadAndStoreReqErgoPosn PassLoadAndStoreReqErgoSetgEve;
SIG_GROUP_ 64 TrOpenerReq 1 : TrOpenerReqTrigSrc TrOpenerReqTrOpenerReq;
SIG_GROUP_ 64 VehMtnSt 1 : VehMtnStChks VehMtnStCntr VehMtnStVehMtnSt;
SIG_GROUP_ 118 ActvnOfIndcr 1 : ActvnOfIndcrIndcrOut ActvnOfIndcrIndcrOutChks ActvnOfIndcrIndcrOutCntr;
SIG_GROUP_ 118 VehSpdLgt 1 : VehSpdLgtA VehSpdLgtChks VehSpdLgtCntr VehSpdLgtQf;
